VERSION ""

NS_ :

BS_:

BU_: PFAF_HS LVMPC_HS DCDC_HS AMP_HS VICM2_HS FICM_HS ARS_HS MCP_B_HS MCP_A_HS ICCM_OBD_HS SAS_HS ACCM_HS VLBS_HS EBCM_OBD_HS EDI_HS HPCC_HS VITM_OBD_HS PTAM_HS OBCM_HS VICM_HS HCP_HS FDCM_HS APPS_HS ICCM_HS EOCM_F_HS GPCM_HS FSCM_ITBC_HS SCM_HS ITBC_HS VCM_HS HMIM_HS FCP_HS VES_HS Dummy_HS MCP_C_HS RWS_HS ONSTAR_HS EPS_HS TestTool_HS MCP_HS BCP_HS ALC_HS AHL_AFL_HS SADS_HS EPB_HS FSCM_HS AFS_HS FCM_HS TCCM_HS RDCM_HS PTO_HS PCM_HS EBCM_HS ACC_HS BCM_HS TCM_HS ECM_HS

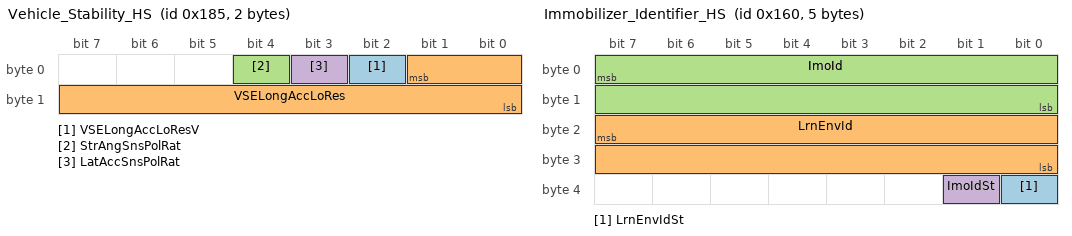
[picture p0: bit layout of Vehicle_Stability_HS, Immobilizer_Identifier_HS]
BO_ 389 Vehicle_Stability_HS: 2 EBCM_HS
 SG_ VSELongAccLoResV : 2|1@0+ (1,0) [0|1] ""  EDI_HS,FCM_HS,TCM_HS,ICCM_OBD_HS,ICCM_HS,ALC_HS,SADS_HS,VES_HS,EPS_HS,EPB_HS,RDCM_HS,BCM_HS,ACC_HS
 SG_ VSELongAccLoRes : 1|10@0- (0.03,0) [-15.36|15.33] "m/s^2"  EDI_HS,FCM_HS,TCM_HS,ICCM_OBD_HS,ICCM_HS,ALC_HS,SADS_HS,VES_HS,EPS_HS,EPB_HS,RDCM_HS,BCM_HS,ACC_HS
 SG_ StrAngSnsPolRat : 4|1@0+ (1,0) [0|1] ""  EPS_HS
 SG_ LatAccSnsPolRat : 3|1@0+ (1,0) [0|1] ""  EPS_HS

BO_ 1922 DTC_Triggered_782: 7 Dummy_HS
 SG_ DTCI_WrnIndRqdSt_782 : 47|1@0+ (1,0) [0|1] ""  HMIM_HS,FCP_HS,ONSTAR_HS
 SG_ DTCIUnused7_782 : 1|1@0+ (1,0) [0|1] ""  HMIM_HS,FCP_HS,ONSTAR_HS
 SG_ DTCIUnused6_782 : 2|1@0+ (1,0) [0|1] ""  HMIM_HS,FCP_HS,ONSTAR_HS
 SG_ DTCIUnused5_782 : 3|1@0+ (1,0) [0|1] ""  HMIM_HS,FCP_HS,ONSTAR_HS
 SG_ DTCIUnused4_782 : 4|1@0+ (1,0) [0|1] ""  HMIM_HS,FCP_HS,ONSTAR_HS
 SG_ DTCIUnused3_782 : 5|1@0+ (1,0) [0|1] ""  HMIM_HS,FCP_HS,ONSTAR_HS
 SG_ DTCIUnused2_782 : 6|1@0+ (1,0) [0|1] ""  HMIM_HS,FCP_HS,ONSTAR_HS
 SG_ DTCIUnused1_782 : 7|1@0+ (1,0) [0|1] ""  HMIM_HS,FCP_HS,ONSTAR_HS
 SG_ DTCI_TstNPsdPwrUpSt_782 : 45|1@0+ (1,0) [0|1] ""  HMIM_HS,FCP_HS,ONSTAR_HS
 SG_ DTCI_TstNPsdCdClrdSt_782 : 42|1@0+ (1,0) [0|1] ""  HMIM_HS,FCP_HS,ONSTAR_HS
 SG_ DTCI_TstFldPwrUpSt_782 : 46|1@0+ (1,0) [0|1] ""  HMIM_HS,FCP_HS,ONSTAR_HS
 SG_ DTCI_TstFldCdClrdStat_782 : 43|1@0+ (1,0) [0|1] ""  HMIM_HS,FCP_HS,ONSTAR_HS
 SG_ DTCI_HistStat_782 : 44|1@0+ (1,0) [0|1] ""  HMIM_HS,FCP_HS,ONSTAR_HS
 SG_ DTCI_DTCTriggered_782 : 0|1@0+ (1,0) [0|1] ""  HMIM_HS,FCP_HS,ONSTAR_HS
 SG_ DTCI_DTCSource_782 : 15|8@0+ (1,0) [0|255] ""  HMIM_HS,FCP_HS,ONSTAR_HS
 SG_ DTCI_DTCNumber_782 : 23|16@0+ (1,0) [0|65535] ""  HMIM_HS,FCP_HS,ONSTAR_HS
 SG_ DTCI_DTCFaultType_782 : 55|8@0+ (1,0) [0|255] ""  HMIM_HS,FCP_HS,ONSTAR_HS
 SG_ DTCI_DTCFailType_782 : 39|8@0+ (1,0) [0|255] ""  HMIM_HS,FCP_HS,ONSTAR_HS
 SG_ DTCI_CurrentStatus_782 : 41|1@0+ (1,0) [0|1] ""  HMIM_HS,FCP_HS,ONSTAR_HS
 SG_ DTCI_CodeSupported_782 : 40|1@0+ (1,0) [0|1] ""  HMIM_HS,FCP_HS,ONSTAR_HS

BO_ 352 Immobilizer_Identifier_HS: 5 BCM_HS
 SG_ LrnEnvIdSt : 32|1@0+ (1,0) [0|1] ""  VLBS_HS,ONSTAR_HS,EBCM_OBD_HS,EBCM_HS
 SG_ LrnEnvId : 23|16@0+ (1,0) [0|65535] ""  VLBS_HS,ONSTAR_HS,EBCM_OBD_HS,EBCM_HS
 SG_ ImoId : 7|16@0+ (1,0) [0|65535] ""  VLBS_HS,ONSTAR_HS,EBCM_OBD_HS,EBCM_HS
 SG_ ImoIdSt : 33|1@0+ (1,0) [0|1] ""  VLBS_HS,ONSTAR_HS,EBCM_OBD_HS,EBCM_HS

BO_ 562 Driving_Mode_Control_HS: 8 EBCM_HS
 SG_ SndPerfMdCsStAvl : 63|1@0+ (1,0) [0|1] ""  BCM_HS
 SG_ SndPerfMdCsCrStVal : 62|3@0+ (1,0) [0|7] ""  BCM_HS
 SG_ DispPerfMdCsStAvl : 59|1@0+ (1,0) [0|1] ""  BCM_HS
 SG_ DispPerfMdCsCrStVal : 58|3@0+ (1,0) [0|7] ""  BCM_HS
 SG_ DrvlneMntsPerfMdRq : 50|3@0+ (1,0) [0|7] ""  Dummy_HS,ICCM_OBD_HS,ICCM_HS
 SG_ RideCntrlPerfMdRq : 18|3@0+ (1,0) [0|7] ""  EDI_HS,SADS_HS
 SG_ StgSysPerfMdRq : 29|3@0+ (1,0) [0|7] ""  EDI_HS,VES_HS,EPS_HS,ARS_HS,AFS_HS
 SG_ DiffPerfMdRq : 26|3@0+ (1,0) [0|7] ""  ICCM_OBD_HS,ICCM_HS
 SG_ SndEnhcmtPerfMdRq : 13|3@0+ (1,0) [0|7] ""  BCM_HS,AMP_HS
 SG_ DsplyPerfMdRq : 10|3@0+ (1,0) [0|7] ""  EDI_HS,BCM_HS
 SG_ ExhstPerfMdRq : 5|3@0+ (1,0) [0|7] ""  FSCM_HS,ICCM_OBD_HS,ICCM_HS
 SG_ HillDscntCntlSysStat : 55|3@0+ (1,0) [0|7] ""  BCM_HS
 SG_ SusCustStngAvlbl : 23|1@0+ (1,0) [0|1] ""  FCP_HS,ONSTAR_HS,BCM_HS
 SG_ SusCustCurrStngVal : 45|3@0+ (1,0) [0|7] ""  FCP_HS,ONSTAR_HS,BCM_HS
 SG_ StrCustStngAvlbl : 7|1@0+ (1,0) [0|1] ""  FCP_HS,ONSTAR_HS,BCM_HS
 SG_ StrCustCurrStngVal : 42|3@0+ (1,0) [0|7] ""  FCP_HS,ONSTAR_HS,BCM_HS
 SG_ DrvlnCustStngAvlbl : 6|1@0+ (1,0) [0|1] ""  FCP_HS,ONSTAR_HS,BCM_HS
 SG_ DrvMdCntrlState : 39|8@0+ (1,0) [0|255] ""  ARS_HS,VES_HS,EPS_HS,AFS_HS,RDCM_HS,SADS_HS
 SG_ AWDPerfMdRq : 2|3@0+ (1,0) [0|7] ""  RDCM_HS,TCCM_HS
 SG_ DrvlnCustCurrStngVal : 22|3@0+ (1,0) [0|7] ""  FCP_HS,ONSTAR_HS,BCM_HS

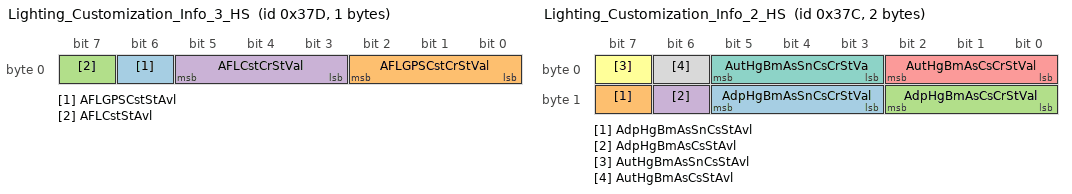
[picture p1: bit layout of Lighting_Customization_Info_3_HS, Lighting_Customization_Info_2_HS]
BO_ 893 Lighting_Customization_Info_3_HS: 1 AHL_AFL_HS
 SG_ AFLGPSCstStAvl : 6|1@0+ (1,0) [0|1] ""  BCM_HS
 SG_ AFLGPSCstCrStVal : 2|3@0+ (1,0) [0|7] ""  BCM_HS
 SG_ AFLCstStAvl : 7|1@0+ (1,0) [0|1] ""  BCM_HS
 SG_ AFLCstCrStVal : 5|3@0+ (1,0) [0|7] ""  BCM_HS

BO_ 892 Lighting_Customization_Info_2_HS: 2 AHL_AFL_HS
 SG_ AdpHgBmAsSnCsCrStVal : 13|3@0+ (1,0) [0|7] ""  BCM_HS
 SG_ AdpHgBmAsSnCsStAvl : 15|1@0+ (1,0) [0|1] ""  BCM_HS
 SG_ AdpHgBmAsCsCrStVal : 10|3@0+ (1,0) [0|7] ""  BCM_HS
 SG_ AdpHgBmAsCsStAvl : 14|1@0+ (1,0) [0|1] ""  BCM_HS
 SG_ AutHgBmAsCsCrStVal : 2|3@0+ (1,0) [0|7] ""  BCM_HS
 SG_ AutHgBmAsSnCsStAvl : 7|1@0+ (1,0) [0|1] ""  BCM_HS
 SG_ AutHgBmAsSnCsCrStVa : 5|3@0+ (1,0) [0|7] ""  BCM_HS
 SG_ AutHgBmAsCsStAvl : 6|1@0+ (1,0) [0|1] ""  BCM_HS

BO_ 386 Environment_Id_Resp_4_HS: 3 EBCM_HS
 SG_ EnvIdRsp4 : 7|16@0+ (1,0) [0|65535] ""  BCM_HS
 SG_ EnvIdRspSt4 : 17|2@0+ (1,0) [0|3] ""  BCM_HS

BO_ 597 USDT_Req_to_AFS_HS: 8 TestTool_HS
 SG_ DgnInf : 7|64@0+ (1,0) [0|1.844674407371E+019] ""  AFS_HS

BO_ 1621 USDT_Resp_From_AFS_HS: 8 AFS_HS
 SG_ DgnInf : 7|64@0+ (1,0) [0|1.844674407371E+019] ""  FCP_HS,ONSTAR_HS,TestTool_HS

BO_ 532 Brake_Pedal_Driver_Status_HS: 6 EBCM_HS
 SG_ RedntVSEActARC : 38|2@0+ (1,0) [0|3] ""  ICCM_OBD_HS,ICCM_HS
 SG_ RedntVSEAct : 39|1@0+ (1,0) [0|1] ""  ICCM_OBD_HS,ICCM_HS
 SG_ AutoBrkngActARC : 22|2@0+ (1,0) [0|3] ""  ICCM_OBD_HS,ICCM_HS
 SG_ ABSAutnmsBrkReqPVal : 41|2@0+ (1,0) [0|3] ""  EPB_HS
 SG_ AutoBrkngAvlbl : 17|1@0+ (1,0) [0|1] ""  EPB_HS
 SG_ ABSAutnmsBrkReqARC : 35|2@0+ (1,0) [0|3] ""  EPB_HS
 SG_ ABSAutnmsBrkReq : 33|1@0+ (1,0) [0|1] ""  EPB_HS
 SG_ ABSActvProtPVal : 43|2@0+ (1,0) [0|3] ""  ICCM_OBD_HS,ICCM_HS
 SG_ ABSActvProtARC : 45|2@0+ (1,0) [0|3] ""  ICCM_OBD_HS,ICCM_HS
 SG_ HlStrAssActIO : 20|1@0+ (1,0) [0|1] ""  BCM_HS
 SG_ ABSActvProt : 46|1@0+ (1,0) [0|1] ""  ICCM_OBD_HS,ICCM_HS
 SG_ BrkSysAutBrkFld : 5|1@0+ (1,0) [0|1] ""  EPB_HS,BCM_HS,ACC_HS
 SG_ IntBrkAssPreFilReq : 4|1@0+ (1,0) [0|1] "N/A"  BCM_HS
 SG_ BrkSysMalFuncIndOn : 3|1@0+ (1,0) [0|1] ""  BCM_HS
 SG_ BrkPdDrvAPrsStaPVal : 16|9@0+ (1,0) [0|511] ""  ACC_HS,EOCM_F_HS,FSCM_ITBC_HS,EPB_HS,SADS_HS
 SG_ BPDAPS_BkPDrvApPV : 8|1@0+ (1,0) [0|1] ""  EOCM_F_HS,FSCM_ITBC_HS,BCM_HS,ACC_HS,SADS_HS,EPB_HS
 SG_ BPDAPS_BkPDrvApP : 0|8@0+ (75,0) [0|19125] "kPa"  EOCM_F_HS,FSCM_ITBC_HS,BCM_HS,ACC_HS,SADS_HS,EPB_HS
 SG_ BrkPdDrvAppPrsAlRC : 2|2@0+ (1,0) [0|3] ""  ACC_HS,EOCM_F_HS,FSCM_ITBC_HS,SADS_HS,EPB_HS
 SG_ BrkFldLvlLwV : 7|1@0+ (1,0) [0|1] ""  BCM_HS
 SG_ AutoBrkngAct : 18|1@0+ (1,0) [0|1] ""  ICCM_OBD_HS,ICCM_HS,EPB_HS,ACC_HS
 SG_ BrkFldLvlLw : 6|1@0+ (1,0) [0|1] ""  BCM_HS

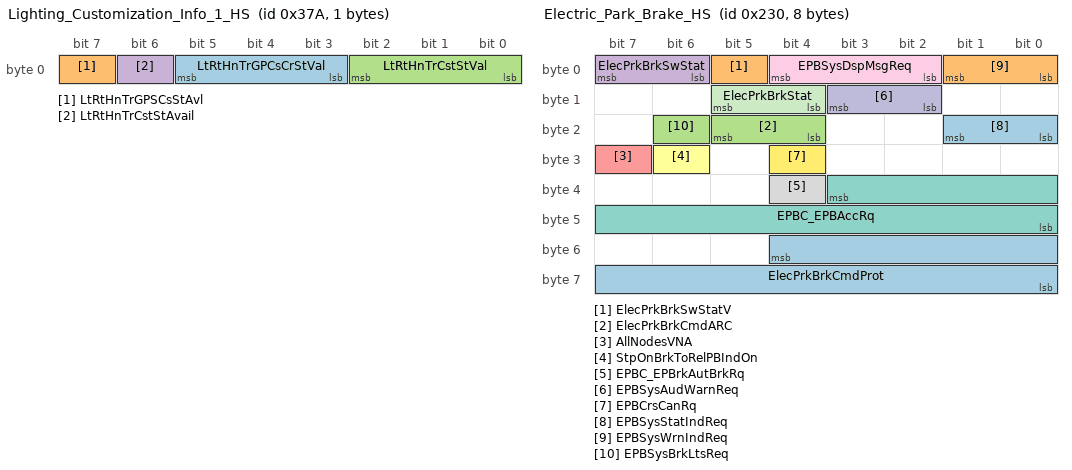
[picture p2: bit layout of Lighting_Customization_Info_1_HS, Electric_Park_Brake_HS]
BO_ 890 Lighting_Customization_Info_1_HS: 1 AHL_AFL_HS
 SG_ LtRtHnTrGPCsCrStVal : 5|3@0+ (1,0) [0|7] ""  BCM_HS
 SG_ LtRtHnTrGPSCsStAvl : 7|1@0+ (1,0) [0|1] ""  BCM_HS
 SG_ LtRtHnTrCstStVal : 2|3@0+ (1,0) [0|7] ""  BCM_HS
 SG_ LtRtHnTrCstStAvail : 6|1@0+ (1,0) [0|1] ""  BCM_HS

BO_ 592 USDT_Req_to_PTAM_HS: 8 TestTool_HS
 SG_ DgnInf : 7|64@0+ (1,0) [0|1.844674407371E+019] ""  PTAM_HS

BO_ 1365 UUDT_Resp_From_AFS_HS: 8 AFS_HS
 SG_ DgnInf_HS555 : 7|64@0+ (1,0) [0|1.844674407371E+019] ""  FCP_HS,ONSTAR_HS,TestTool_HS

BO_ 328 Power_Steering_Information_HS: 1 EPS_HS
 SG_ StrngAsstRdcdIO : 1|1@0+ (1,0) [0|1] ""  BCM_HS
 SG_ PwrStrIO : 0|1@0+ (1,0) [0|1] ""  BCM_HS,EPB_HS

BO_ 560 Electric_Park_Brake_HS: 8 EPB_HS
 SG_ ElecPrkBrkCmdProt : 52|13@0+ (1,0) [0|8191] ""  EBCM_OBD_HS,EBCM_HS
 SG_ ElecPrkBrkSwStatV : 5|1@0+ (1,0) [0|1] ""  EBCM_OBD_HS,EBCM_HS
 SG_ ElecPrkBrkCmdARC : 21|2@0+ (1,0) [0|3] ""  EBCM_OBD_HS,EBCM_HS
 SG_ ElecPrkBrkSwStat : 7|2@0+ (1,0) [0|3] ""  EBCM_OBD_HS,EBCM_HS
 SG_ AllNodesVNA : 31|1@0+ (1,0) [0|1] ""  BCM_HS
 SG_ StpOnBrkToRelPBIndOn : 30|1@0+ (1,0) [0|1] ""  BCM_HS
 SG_ EPBC_EPBAccRq : 35|12@0- (0.01,0) [-20.48|20.47] "m/s^2"  EBCM_OBD_HS,EBCM_HS
 SG_ EPBC_EPBrkAutBrkRq : 36|1@0+ (1,0) [0|1] ""  EBCM_OBD_HS,EBCM_HS
 SG_ EPBSysDspMsgReq : 4|3@0+ (1,0) [0|7] ""  BCM_HS
 SG_ EPBSysAudWarnReq : 11|2@0+ (1,0) [0|3] ""  BCM_HS
 SG_ ElecPrkBrkStat : 13|2@0+ (1,0) [0|2] ""  ICCM_OBD_HS,ICCM_HS,ACC_HS,EOCM_F_HS,BCM_HS,EBCM_OBD_HS,EBCM_HS,RDCM_HS
 SG_ EPBCrsCanRq : 28|1@0+ (1,0) [0|1] ""  ACC_HS,EOCM_F_HS,EBCM_OBD_HS,EBCM_HS,BCM_HS
 SG_ EPBSysStatIndReq : 17|2@0+ (1,0) [0|3] ""  BCM_HS
 SG_ EPBSysWrnIndReq : 1|2@0+ (1,0) [0|3] ""  BCM_HS
 SG_ EPBSysBrkLtsReq : 22|1@0+ (1,0) [0|1] ""  BCM_HS

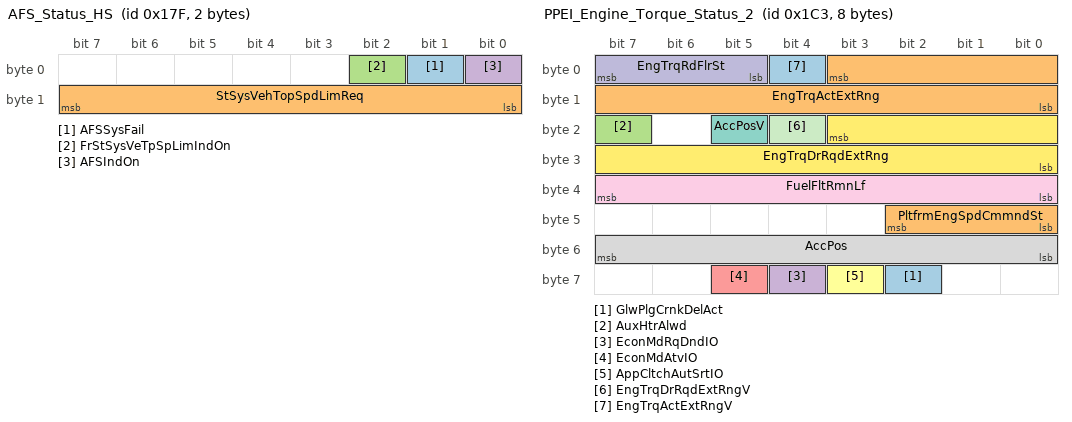
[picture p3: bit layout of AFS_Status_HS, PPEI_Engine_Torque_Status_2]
BO_ 383 AFS_Status_HS: 2 AFS_HS
 SG_ AFSSysFail : 1|1@0+ (1,0) [0|1] ""  EBCM_OBD_HS,EBCM_HS
 SG_ StSysVehTopSpdLimReq : 15|8@0+ (2,0) [0|510] "km/h"  BCM_HS
 SG_ FrStSysVeTpSpLimIndOn : 2|1@0+ (1,0) [0|1] ""  BCM_HS
 SG_ AFSIndOn : 0|1@0+ (1,0) [0|1] ""  BCM_HS

BO_ 451 PPEI_Engine_Torque_Status_2: 8 ECM_HS
 SG_ GlwPlgCrnkDelAct : 58|1@0+ (1,0) [0|1] ""  BCM_HS
 SG_ PltfrmEngSpdCmmndSt : 42|3@0+ (1,0) [0|7] ""  PTO_HS
 SG_ AuxHtrAlwd : 23|1@0+ (1,0) [0|1] ""  BCM_HS
 SG_ EconMdRqDndIO : 60|1@0+ (1,0) [0|1] ""  BCM_HS
 SG_ EconMdAtvIO : 61|1@0+ (1,0) [0|1] ""  BCM_HS
 SG_ AppCltchAutSrtIO : 59|1@0+ (1,0) [0|1] ""  BCM_HS
 SG_ AccPosV : 21|1@0+ (1,0) [0|1] ""  ICCM_OBD_HS,ICCM_HS,FSCM_ITBC_HS,FSCM_HS,ACC_HS,EOCM_F_HS,TCCM_HS,EBCM_OBD_HS,EBCM_HS
 SG_ AccPos : 55|8@0+ (0.392157,0) [0|100.000035] "%"  ICCM_OBD_HS,ICCM_HS,FSCM_ITBC_HS,FSCM_HS,EOCM_F_HS,VICM_HS,ACC_HS,TCCM_HS,EBCM_OBD_HS,EBCM_HS
 SG_ FuelFltRmnLf : 39|8@0+ (0.392157,0) [0|100.000035] "%"  FCP_HS,ONSTAR_HS,BCM_HS
 SG_ EngTrqRdFlrSt : 7|3@0+ (1,0) [0|7] ""  PTAM_HS,EBCM_OBD_HS,EBCM_HS
 SG_ EngTrqDrRqdExtRngV : 20|1@0+ (1,0) [0|1] ""  LVMPC_HS,BCM_HS,PTAM_HS,ACC_HS,RDCM_HS,EBCM_OBD_HS,EBCM_HS,SADS_HS
 SG_ EngTrqDrRqdExtRng : 19|12@0+ (0.5,-848) [-848|1199.5] "Nm"  LVMPC_HS,BCM_HS,PTAM_HS,ACC_HS,RDCM_HS,EBCM_OBD_HS,EBCM_HS,SADS_HS
 SG_ EngTrqActExtRngV : 4|1@0+ (1,0) [0|1] ""  PTO_HS,ICCM_OBD_HS,ICCM_HS,FSCM_ITBC_HS,FSCM_HS,AMP_HS,PTAM_HS,TCCM_HS,VES_HS,ACC_HS,EPS_HS,EPB_HS,BCM_HS,RDCM_HS,EBCM_OBD_HS,EBCM_HS,SADS_HS
 SG_ EngTrqActExtRng : 3|12@0+ (0.5,-848) [-848|1199.5] "Nm"  ICCM_OBD_HS,ICCM_HS,FSCM_ITBC_HS,FSCM_HS,PTO_HS,AMP_HS,PTAM_HS,TCCM_HS,VES_HS,ACC_HS,EPS_HS,EPB_HS,BCM_HS,RDCM_HS,EBCM_OBD_HS,EBCM_HS,SADS_HS

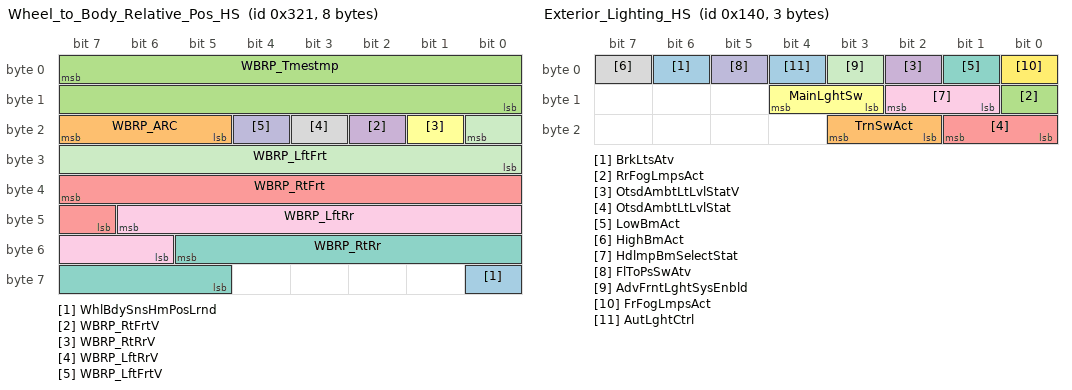
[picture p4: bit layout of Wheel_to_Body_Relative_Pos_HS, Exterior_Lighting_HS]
BO_ 801 Wheel_to_Body_Relative_Pos_HS: 8 SADS_HS
 SG_ WhlBdySnsHmPosLrnd : 56|1@0+ (1,0) [0|1] ""  EDI_HS,ICCM_OBD_HS,ICCM_HS,ALC_HS,SADS_HS,FCM_HS,AHL_AFL_HS,EBCM_OBD_HS,EBCM_HS
 SG_ WBRP_ARC : 23|3@0+ (1,0) [0|7] "counts"  EDI_HS,ICCM_OBD_HS,ICCM_HS,ALC_HS,SADS_HS,FCM_HS,EBCM_OBD_HS,EBCM_HS,AHL_AFL_HS
 SG_ WBRP_Tmestmp : 7|16@0+ (1,0) [0|65535] "micro sec"  EDI_HS,ICCM_OBD_HS,ICCM_HS,ALC_HS,SADS_HS,FCM_HS,EBCM_OBD_HS,EBCM_HS,AHL_AFL_HS
 SG_ WBRP_RtFrtV : 18|1@0+ (1,0) [0|1] ""  EDI_HS,ICCM_OBD_HS,ICCM_HS,ALC_HS,SADS_HS,FCM_HS,EBCM_OBD_HS,EBCM_HS,AHL_AFL_HS
 SG_ WBRP_RtFrt : 39|9@0- (1,0) [-256|255] "mm"  EDI_HS,ICCM_OBD_HS,ICCM_HS,ALC_HS,SADS_HS,FCM_HS,EBCM_OBD_HS,EBCM_HS,AHL_AFL_HS
 SG_ WBRP_RtRrV : 17|1@0+ (1,0) [0|1] ""  EDI_HS,ICCM_OBD_HS,ICCM_HS,ALC_HS,SADS_HS,FCM_HS,EBCM_OBD_HS,EBCM_HS,AHL_AFL_HS
 SG_ WBRP_RtRr : 53|9@0- (1,0) [-256|255] "mm"  EDI_HS,ICCM_OBD_HS,ICCM_HS,ALC_HS,SADS_HS,FCM_HS,EBCM_OBD_HS,EBCM_HS,AHL_AFL_HS
 SG_ WBRP_LftRrV : 19|1@0+ (1,0) [0|1] ""  EDI_HS,ICCM_OBD_HS,ICCM_HS,ALC_HS,SADS_HS,FCM_HS,EBCM_OBD_HS,EBCM_HS,AHL_AFL_HS
 SG_ WBRP_LftRr : 46|9@0- (1,0) [-256|255] "mm"  EDI_HS,ICCM_OBD_HS,ICCM_HS,ALC_HS,SADS_HS,FCM_HS,EBCM_OBD_HS,EBCM_HS,AHL_AFL_HS
 SG_ WBRP_LftFrtV : 20|1@0+ (1,0) [0|1] ""  EDI_HS,ICCM_OBD_HS,ICCM_HS,ALC_HS,SADS_HS,FCM_HS,EBCM_OBD_HS,EBCM_HS,AHL_AFL_HS
 SG_ WBRP_LftFrt : 16|9@0- (1,0) [-256|255] "mm"  EDI_HS,ICCM_OBD_HS,ICCM_HS,ALC_HS,SADS_HS,FCM_HS,EBCM_OBD_HS,EBCM_HS,AHL_AFL_HS

BO_ 320 Exterior_Lighting_HS: 3 BCM_HS
 SG_ BrkLtsAtv : 6|1@0+ (1,0) [0|1] ""  AHL_AFL_HS,EOCM_F_HS,ACC_HS
 SG_ TrnSwAct : 19|2@0+ (1,0) [0|3] ""  EOCM_F_HS,AHL_AFL_HS
 SG_ RrFogLmpsAct : 8|1@0+ (1,0) [0|1] ""  AHL_AFL_HS
 SG_ OtsdAmbtLtLvlStatV : 2|1@0+ (1,0) [0|1] ""  FCM_HS,EOCM_F_HS,AHL_AFL_HS
 SG_ OtsdAmbtLtLvlStat : 17|2@0+ (1,0) [0|3] ""  FCM_HS,EOCM_F_HS,AHL_AFL_HS
 SG_ MainLghtSw : 12|2@0+ (1,0) [0|3] "N/A"  FCM_HS,AHL_AFL_HS
 SG_ LowBmAct : 1|1@0+ (1,0) [0|1] ""  FCM_HS,EOCM_F_HS,AHL_AFL_HS
 SG_ HighBmAct : 7|1@0+ (1,0) [0|1] ""  FCM_HS,EOCM_F_HS,AHL_AFL_HS
 SG_ HdlmpBmSelectStat : 10|2@0+ (1,0) [0|3] ""  FCM_HS,AHL_AFL_HS
 SG_ FlToPsSwAtv : 5|1@0+ (1,0) [0|1] ""  FCM_HS,AHL_AFL_HS
 SG_ AdvFrntLghtSysEnbld : 3|1@0+ (1,0) [0|1] ""  AHL_AFL_HS
 SG_ FrFogLmpsAct : 0|1@0+ (1,0) [0|1] ""  FCM_HS,AHL_AFL_HS
 SG_ AutLghtCtrl : 4|1@0+ (1,0) [0|1] "N/A"  AHL_AFL_HS

BO_ 957 ETEI_Glow_Plug_Diagnostic_Status: 8 GPCM_HS
 SG_ RdctHtrCStat : 26|1@0+ (1,0) [0|1] ""  PCM_HS,ECM_HS
 SG_ RdctHtrBStat : 27|1@0+ (1,0) [0|1] ""  PCM_HS,ECM_HS
 SG_ RdctHtrAStat : 28|1@0+ (1,0) [0|1] ""  PCM_HS,ECM_HS
 SG_ GPCMDS2_DTCStatus : 58|3@0+ (1,0) [0|7] ""  PCM_HS,ECM_HS
 SG_ GPCMDS2_DTCIndex : 63|5@0+ (1,0) [0|31] ""  PCM_HS,ECM_HS
 SG_ IntAirHtrPwrConsmp : 55|8@0+ (20,0) [0|5100] "W"  PCM_HS,ECM_HS
 SG_ IntAirHtrPwrConsmpV : 29|1@0+ (1,0) [0|1] ""  PCM_HS,ECM_HS
 SG_ DslGlwPlgMdOvTmOD : 25|1@0+ (1,0) [0|1] ""  PCM_HS,ECM_HS
 SG_ IQAI_DataByte : 47|8@0+ (1,0) [0|255] ""  PCM_HS,ECM_HS
 SG_ IQAI_DataSeqNmbr : 35|4@0+ (1,0) [0|15] ""  PCM_HS,ECM_HS
 SG_ IQAI_InjIdInd : 38|3@0+ (1,0) [0|7] ""  PCM_HS,ECM_HS
 SG_ IQAI_DataStat : 39|1@0+ (1,0) [0|1] ""  PCM_HS,ECM_HS
 SG_ IntAirHtrTempSensVoltV : 30|1@0+ (1,0) [0|1] ""  PCM_HS,ECM_HS
 SG_ IntAirHtrTempSensVolt : 23|8@0+ (0.0196078,0) [0|4.999989] "volts"  PCM_HS,ECM_HS
 SG_ IntAirHtrSupVoltV : 31|1@0+ (1,0) [0|1] ""  PCM_HS,ECM_HS
 SG_ IntAirHtrSupVolt : 15|8@0+ (0.1,0) [0|25.5] "volts"  PCM_HS,ECM_HS
 SG_ GPCMDS_DTCStatus : 2|3@0+ (1,0) [0|7] ""  PCM_HS,ECM_HS
 SG_ GPCMDS_DTCIndex : 7|5@0+ (1,0) [0|31] ""  PCM_HS,ECM_HS

BO_ 1364 UUDT_Resp_From_EPB_HS: 8 EPB_HS
 SG_ DgnInf_HS554 : 7|64@0+ (1,0) [0|1.844674407371E+019] ""  FCP_HS,ONSTAR_HS,TestTool_HS

BO_ 2041 PCU_Resp_From_SDM_HS: 8 BCM_HS
 SG_ PCUInfo_7F9 : 7|64@0+ (1,0) [0|1.844674407371E+019] ""  TestTool_HS

BO_ 1904 DTC_Triggered_770: 7 FSCM_HS
 SG_ DTCI_WrnIndRqdSt_770 : 47|1@0+ (1,0) [0|1] ""  HMIM_HS,FCP_HS,ONSTAR_HS
 SG_ DTCIUnused7_770 : 7|1@0+ (1,0) [0|1] ""  HMIM_HS,FCP_HS,ONSTAR_HS
 SG_ DTCIUnused6_770 : 6|1@0+ (1,0) [0|1] ""  HMIM_HS,FCP_HS,ONSTAR_HS
 SG_ DTCIUnused5_770 : 5|1@0+ (1,0) [0|1] ""  HMIM_HS,FCP_HS,ONSTAR_HS
 SG_ DTCIUnused4_770 : 4|1@0+ (1,0) [0|1] ""  HMIM_HS,FCP_HS,ONSTAR_HS
 SG_ DTCIUnused3_770 : 3|1@0+ (1,0) [0|1] ""  HMIM_HS,FCP_HS,ONSTAR_HS
 SG_ DTCIUnused2_770 : 2|1@0+ (1,0) [0|1] ""  HMIM_HS,FCP_HS,ONSTAR_HS
 SG_ DTCIUnused1_770 : 1|1@0+ (1,0) [0|1] ""  HMIM_HS,FCP_HS,ONSTAR_HS
 SG_ DTCI_TstNPsdPwrUpSt_770 : 45|1@0+ (1,0) [0|1] ""  HMIM_HS,FCP_HS,ONSTAR_HS
 SG_ DTCI_TstNPsdCdClrdSt_770 : 42|1@0+ (1,0) [0|1] ""  HMIM_HS,FCP_HS,ONSTAR_HS
 SG_ DTCI_TstFldPwrUpSt_770 : 46|1@0+ (1,0) [0|1] ""  HMIM_HS,FCP_HS,ONSTAR_HS
 SG_ DTCI_TstFldCdClrdStat_770 : 43|1@0+ (1,0) [0|1] ""  HMIM_HS,FCP_HS,ONSTAR_HS
 SG_ DTCI_HistStat_770 : 44|1@0+ (1,0) [0|1] ""  HMIM_HS,FCP_HS,ONSTAR_HS
 SG_ DTCI_DTCTriggered_770 : 0|1@0+ (1,0) [0|1] ""  HMIM_HS,FCP_HS,ONSTAR_HS
 SG_ DTCI_DTCSource_770 : 15|8@0+ (1,0) [0|255] ""  HMIM_HS,FCP_HS,ONSTAR_HS
 SG_ DTCI_DTCNumber_770 : 23|16@0+ (1,0) [0|65535] ""  HMIM_HS,FCP_HS,ONSTAR_HS
 SG_ DTCI_DTCFaultType_770 : 55|8@0+ (1,0) [0|255] ""  HMIM_HS,FCP_HS,ONSTAR_HS
 SG_ DTCI_DTCFailType_770 : 39|8@0+ (1,0) [0|255] ""  HMIM_HS,FCP_HS,ONSTAR_HS
 SG_ DTCI_CurrentStatus_770 : 41|1@0+ (1,0) [0|1] ""  HMIM_HS,FCP_HS,ONSTAR_HS
 SG_ DTCI_CodeSupported_770 : 40|1@0+ (1,0) [0|1] ""  HMIM_HS,FCP_HS,ONSTAR_HS

BO_ 1908 DTC_Triggered_774: 7 DCDC_HS
 SG_ DTCI_DTCFaultType_774 : 55|8@0+ (1,0) [0|255] ""  HMIM_HS,FCP_HS,ONSTAR_HS
 SG_ DTCI_CodeSupported_774 : 40|1@0+ (1,0) [0|1] ""  HMIM_HS,FCP_HS,ONSTAR_HS
 SG_ DTCI_CurrentStatus_774 : 41|1@0+ (1,0) [0|1] ""  HMIM_HS,FCP_HS,ONSTAR_HS
 SG_ DTCI_TstNPsdCdClrdSt_774 : 42|1@0+ (1,0) [0|1] ""  HMIM_HS,FCP_HS,ONSTAR_HS
 SG_ DTCI_TstFldCdClrdStat_774 : 43|1@0+ (1,0) [0|1] ""  HMIM_HS,FCP_HS,ONSTAR_HS
 SG_ DTCI_HistStat_774 : 44|1@0+ (1,0) [0|1] ""  HMIM_HS,FCP_HS,ONSTAR_HS
 SG_ DTCI_TstNPsdPwrUpSt_774 : 45|1@0+ (1,0) [0|1] ""  HMIM_HS,FCP_HS,ONSTAR_HS
 SG_ DTCI_TstFldPwrUpSt_774 : 46|1@0+ (1,0) [0|1] ""  HMIM_HS,FCP_HS,ONSTAR_HS
 SG_ DTCI_WrnIndRqdSt_774 : 47|1@0+ (1,0) [0|1] ""  HMIM_HS,FCP_HS,ONSTAR_HS
 SG_ DTCI_DTCFailType_774 : 39|8@0+ (1,0) [0|255] ""  HMIM_HS,FCP_HS,ONSTAR_HS
 SG_ DTCI_DTCNumber_774 : 23|16@0+ (1,0) [0|65535] ""  HMIM_HS,FCP_HS,ONSTAR_HS
 SG_ DTCI_DTCSource_774 : 15|8@0+ (1,0) [0|255] ""  HMIM_HS,FCP_HS,ONSTAR_HS
 SG_ DTCI_DTCTriggered_774 : 0|1@0+ (1,0) [0|1] ""  HMIM_HS,FCP_HS,ONSTAR_HS
 SG_ DTCIUnused7_774 : 1|1@0+ (1,0) [0|1] ""  HMIM_HS,FCP_HS,ONSTAR_HS
 SG_ DTCIUnused6_774 : 2|1@0+ (1,0) [0|1] ""  HMIM_HS,FCP_HS,ONSTAR_HS
 SG_ DTCIUnused5_774 : 3|1@0+ (1,0) [0|1] ""  HMIM_HS,FCP_HS,ONSTAR_HS
 SG_ DTCIUnused4_774 : 4|1@0+ (1,0) [0|1] ""  HMIM_HS,FCP_HS,ONSTAR_HS
 SG_ DTCIUnused3_774 : 5|1@0+ (1,0) [0|1] ""  HMIM_HS,FCP_HS,ONSTAR_HS
 SG_ DTCIUnused2_774 : 6|1@0+ (1,0) [0|1] ""  HMIM_HS,FCP_HS,ONSTAR_HS
 SG_ DTCIUnused1_774 : 7|1@0+ (1,0) [0|1] ""  HMIM_HS,FCP_HS,ONSTAR_HS

BO_ 1909 DTC_Triggered_775: 7 MCP_HS
 SG_ DTCI_DTCFaultType_775 : 55|8@0+ (1,0) [0|255] ""  HMIM_HS,FCP_HS,ONSTAR_HS
 SG_ DTCI_CodeSupported_775 : 40|1@0+ (1,0) [0|1] ""  HMIM_HS,FCP_HS,ONSTAR_HS
 SG_ DTCI_CurrentStatus_775 : 41|1@0+ (1,0) [0|1] ""  HMIM_HS,FCP_HS,ONSTAR_HS
 SG_ DTCI_TstNPsdCdClrdSt_775 : 42|1@0+ (1,0) [0|1] ""  HMIM_HS,FCP_HS,ONSTAR_HS
 SG_ DTCI_TstFldCdClrdStat_775 : 43|1@0+ (1,0) [0|1] ""  HMIM_HS,FCP_HS,ONSTAR_HS
 SG_ DTCI_HistStat_775 : 44|1@0+ (1,0) [0|1] ""  HMIM_HS,FCP_HS,ONSTAR_HS
 SG_ DTCI_TstNPsdPwrUpSt_775 : 45|1@0+ (1,0) [0|1] ""  HMIM_HS,FCP_HS,ONSTAR_HS
 SG_ DTCI_TstFldPwrUpSt_775 : 46|1@0+ (1,0) [0|1] ""  HMIM_HS,FCP_HS,ONSTAR_HS
 SG_ DTCI_WrnIndRqdSt_775 : 47|1@0+ (1,0) [0|1] ""  HMIM_HS,FCP_HS,ONSTAR_HS
 SG_ DTCI_DTCFailType_775 : 39|8@0+ (1,0) [0|255] ""  HMIM_HS,FCP_HS,ONSTAR_HS
 SG_ DTCI_DTCNumber_775 : 23|16@0+ (1,0) [0|65535] ""  HMIM_HS,FCP_HS,ONSTAR_HS
 SG_ DTCI_DTCSource_775 : 15|8@0+ (1,0) [0|255] ""  HMIM_HS,FCP_HS,ONSTAR_HS
 SG_ DTCI_DTCTriggered_775 : 0|1@0+ (1,0) [0|1] ""  HMIM_HS,FCP_HS,ONSTAR_HS
 SG_ DTCIUnused7_775 : 1|1@0+ (1,0) [0|1] ""  HMIM_HS,FCP_HS,ONSTAR_HS
 SG_ DTCIUnused6_775 : 2|1@0+ (1,0) [0|1] ""  HMIM_HS,FCP_HS,ONSTAR_HS
 SG_ DTCIUnused5_775 : 3|1@0+ (1,0) [0|1] ""  HMIM_HS,FCP_HS,ONSTAR_HS
 SG_ DTCIUnused4_775 : 4|1@0+ (1,0) [0|1] ""  HMIM_HS,FCP_HS,ONSTAR_HS
 SG_ DTCIUnused3_775 : 5|1@0+ (1,0) [0|1] ""  HMIM_HS,FCP_HS,ONSTAR_HS
 SG_ DTCIUnused2_775 : 6|1@0+ (1,0) [0|1] ""  HMIM_HS,FCP_HS,ONSTAR_HS
 SG_ DTCIUnused1_775 : 7|1@0+ (1,0) [0|1] ""  HMIM_HS,FCP_HS,ONSTAR_HS

BO_ 1910 DTC_Triggered_776: 7 BCP_HS
 SG_ DTCI_DTCFaultType_776 : 55|8@0+ (1,0) [0|255] ""  HMIM_HS,FCP_HS,ONSTAR_HS
 SG_ DTCI_CodeSupported_776 : 40|1@0+ (1,0) [0|1] ""  HMIM_HS,FCP_HS,ONSTAR_HS
 SG_ DTCI_CurrentStatus_776 : 41|1@0+ (1,0) [0|1] ""  HMIM_HS,FCP_HS,ONSTAR_HS
 SG_ DTCI_TstNPsdCdClrdSt_776 : 42|1@0+ (1,0) [0|1] ""  HMIM_HS,FCP_HS,ONSTAR_HS
 SG_ DTCI_TstFldCdClrdStat_776 : 43|1@0+ (1,0) [0|1] ""  HMIM_HS,FCP_HS,ONSTAR_HS
 SG_ DTCI_HistStat_776 : 44|1@0+ (1,0) [0|1] ""  HMIM_HS,FCP_HS,ONSTAR_HS
 SG_ DTCI_TstNPsdPwrUpSt_776 : 45|1@0+ (1,0) [0|1] ""  HMIM_HS,FCP_HS,ONSTAR_HS
 SG_ DTCI_TstFldPwrUpSt_776 : 46|1@0+ (1,0) [0|1] ""  HMIM_HS,FCP_HS,ONSTAR_HS
 SG_ DTCI_WrnIndRqdSt_776 : 47|1@0+ (1,0) [0|1] ""  HMIM_HS,FCP_HS,ONSTAR_HS
 SG_ DTCI_DTCFailType_776 : 39|8@0+ (1,0) [0|255] ""  HMIM_HS,FCP_HS,ONSTAR_HS
 SG_ DTCI_DTCNumber_776 : 23|16@0+ (1,0) [0|65535] ""  HMIM_HS,FCP_HS,ONSTAR_HS
 SG_ DTCI_DTCSource_776 : 15|8@0+ (1,0) [0|255] ""  HMIM_HS,FCP_HS,ONSTAR_HS
 SG_ DTCI_DTCTriggered_776 : 0|1@0+ (1,0) [0|1] ""  HMIM_HS,FCP_HS,ONSTAR_HS
 SG_ DTCIUnused7_776 : 1|1@0+ (1,0) [0|1] ""  HMIM_HS,FCP_HS,ONSTAR_HS
 SG_ DTCIUnused6_776 : 2|1@0+ (1,0) [0|1] ""  HMIM_HS,FCP_HS,ONSTAR_HS
 SG_ DTCIUnused5_776 : 3|1@0+ (1,0) [0|1] ""  HMIM_HS,FCP_HS,ONSTAR_HS
 SG_ DTCIUnused4_776 : 4|1@0+ (1,0) [0|1] ""  HMIM_HS,FCP_HS,ONSTAR_HS
 SG_ DTCIUnused3_776 : 5|1@0+ (1,0) [0|1] ""  HMIM_HS,FCP_HS,ONSTAR_HS
 SG_ DTCIUnused2_776 : 6|1@0+ (1,0) [0|1] ""  HMIM_HS,FCP_HS,ONSTAR_HS
 SG_ DTCIUnused1_776 : 7|1@0+ (1,0) [0|1] ""  HMIM_HS,FCP_HS,ONSTAR_HS

BO_ 1912 DTC_Triggered_778: 7 EPS_HS
 SG_ DTCI_DTCFaultType_778 : 55|8@0+ (1,0) [0|255] ""  HMIM_HS,FCP_HS,ONSTAR_HS
 SG_ DTCI_CodeSupported_778 : 40|1@0+ (1,0) [0|1] ""  HMIM_HS,FCP_HS,ONSTAR_HS
 SG_ DTCI_CurrentStatus_778 : 41|1@0+ (1,0) [0|1] ""  HMIM_HS,FCP_HS,ONSTAR_HS
 SG_ DTCI_TstNPsdCdClrdSt_778 : 42|1@0+ (1,0) [0|1] ""  HMIM_HS,FCP_HS,ONSTAR_HS
 SG_ DTCI_TstFldCdClrdStat_778 : 43|1@0+ (1,0) [0|1] ""  HMIM_HS,FCP_HS,ONSTAR_HS
 SG_ DTCI_HistStat_778 : 44|1@0+ (1,0) [0|1] ""  HMIM_HS,FCP_HS,ONSTAR_HS
 SG_ DTCI_TstNPsdPwrUpSt_778 : 45|1@0+ (1,0) [0|1] ""  HMIM_HS,FCP_HS,ONSTAR_HS
 SG_ DTCI_TstFldPwrUpSt_778 : 46|1@0+ (1,0) [0|1] ""  HMIM_HS,FCP_HS,ONSTAR_HS
 SG_ DTCI_WrnIndRqdSt_778 : 47|1@0+ (1,0) [0|1] ""  HMIM_HS,FCP_HS,ONSTAR_HS
 SG_ DTCI_DTCFailType_778 : 39|8@0+ (1,0) [0|255] ""  HMIM_HS,FCP_HS,ONSTAR_HS
 SG_ DTCI_DTCNumber_778 : 23|16@0+ (1,0) [0|65535] ""  HMIM_HS,FCP_HS,ONSTAR_HS
 SG_ DTCI_DTCSource_778 : 15|8@0+ (1,0) [0|255] ""  HMIM_HS,FCP_HS,ONSTAR_HS
 SG_ DTCI_DTCTriggered_778 : 0|1@0+ (1,0) [0|1] ""  HMIM_HS,FCP_HS,ONSTAR_HS
 SG_ DTCIUnused7_778 : 1|1@0+ (1,0) [0|1] ""  HMIM_HS,FCP_HS,ONSTAR_HS
 SG_ DTCIUnused6_778 : 2|1@0+ (1,0) [0|1] ""  HMIM_HS,FCP_HS,ONSTAR_HS
 SG_ DTCIUnused5_778 : 3|1@0+ (1,0) [0|1] ""  HMIM_HS,FCP_HS,ONSTAR_HS
 SG_ DTCIUnused4_778 : 4|1@0+ (1,0) [0|1] ""  HMIM_HS,FCP_HS,ONSTAR_HS
 SG_ DTCIUnused3_778 : 5|1@0+ (1,0) [0|1] ""  HMIM_HS,FCP_HS,ONSTAR_HS
 SG_ DTCIUnused2_778 : 6|1@0+ (1,0) [0|1] ""  HMIM_HS,FCP_HS,ONSTAR_HS
 SG_ DTCIUnused1_778 : 7|1@0+ (1,0) [0|1] ""  HMIM_HS,FCP_HS,ONSTAR_HS

BO_ 1913 DTC_Triggered_779: 7 AFS_HS
 SG_ DTCI_DTCFaultType_779 : 55|8@0+ (1,0) [0|255] ""  HMIM_HS,FCP_HS,ONSTAR_HS
 SG_ DTCI_CodeSupported_779 : 40|1@0+ (1,0) [0|1] ""  HMIM_HS,FCP_HS,ONSTAR_HS
 SG_ DTCI_CurrentStatus_779 : 41|1@0+ (1,0) [0|1] ""  HMIM_HS,FCP_HS,ONSTAR_HS
 SG_ DTCI_TstNPsdCdClrdSt_779 : 42|1@0+ (1,0) [0|1] ""  HMIM_HS,FCP_HS,ONSTAR_HS
 SG_ DTCI_TstFldCdClrdStat_779 : 43|1@0+ (1,0) [0|1] ""  HMIM_HS,FCP_HS,ONSTAR_HS
 SG_ DTCI_HistStat_779 : 44|1@0+ (1,0) [0|1] ""  HMIM_HS,FCP_HS,ONSTAR_HS
 SG_ DTCI_TstNPsdPwrUpSt_779 : 45|1@0+ (1,0) [0|1] ""  HMIM_HS,FCP_HS,ONSTAR_HS
 SG_ DTCI_TstFldPwrUpSt_779 : 46|1@0+ (1,0) [0|1] ""  HMIM_HS,FCP_HS,ONSTAR_HS
 SG_ DTCI_WrnIndRqdSt_779 : 47|1@0+ (1,0) [0|1] ""  HMIM_HS,FCP_HS,ONSTAR_HS
 SG_ DTCI_DTCFailType_779 : 39|8@0+ (1,0) [0|255] ""  HMIM_HS,FCP_HS,ONSTAR_HS
 SG_ DTCI_DTCNumber_779 : 23|16@0+ (1,0) [0|65535] ""  HMIM_HS,FCP_HS,ONSTAR_HS
 SG_ DTCI_DTCSource_779 : 15|8@0+ (1,0) [0|255] ""  HMIM_HS,FCP_HS,ONSTAR_HS
 SG_ DTCI_DTCTriggered_779 : 0|1@0+ (1,0) [0|1] ""  HMIM_HS,FCP_HS,ONSTAR_HS
 SG_ DTCIUnused7_779 : 1|1@0+ (1,0) [0|1] ""  HMIM_HS,FCP_HS,ONSTAR_HS
 SG_ DTCIUnused6_779 : 2|1@0+ (1,0) [0|1] ""  HMIM_HS,FCP_HS,ONSTAR_HS
 SG_ DTCIUnused5_779 : 3|1@0+ (1,0) [0|1] ""  HMIM_HS,FCP_HS,ONSTAR_HS
 SG_ DTCIUnused4_779 : 4|1@0+ (1,0) [0|1] ""  HMIM_HS,FCP_HS,ONSTAR_HS
 SG_ DTCIUnused3_779 : 5|1@0+ (1,0) [0|1] ""  HMIM_HS,FCP_HS,ONSTAR_HS
 SG_ DTCIUnused2_779 : 6|1@0+ (1,0) [0|1] ""  HMIM_HS,FCP_HS,ONSTAR_HS
 SG_ DTCIUnused1_779 : 7|1@0+ (1,0) [0|1] ""  HMIM_HS,FCP_HS,ONSTAR_HS

BO_ 1916 DTC_Triggered_77C: 7 AHL_AFL_HS
 SG_ DTCI_DTCFaultType_77C : 55|8@0+ (1,0) [0|255] ""  HMIM_HS,FCP_HS,ONSTAR_HS
 SG_ DTCI_CodeSupported_77C : 40|1@0+ (1,0) [0|1] ""  HMIM_HS,FCP_HS,ONSTAR_HS
 SG_ DTCI_CurrentStatus_77C : 41|1@0+ (1,0) [0|1] ""  HMIM_HS,FCP_HS,ONSTAR_HS
 SG_ DTCI_TstNPsdCdClrdSt_77C : 42|1@0+ (1,0) [0|1] ""  HMIM_HS,FCP_HS,ONSTAR_HS
 SG_ DTCI_TstFldCdClrdStat_77C : 43|1@0+ (1,0) [0|1] ""  HMIM_HS,FCP_HS,ONSTAR_HS
 SG_ DTCI_HistStat_77C : 44|1@0+ (1,0) [0|1] ""  HMIM_HS,FCP_HS,ONSTAR_HS
 SG_ DTCI_TstNPsdPwrUpSt_77C : 45|1@0+ (1,0) [0|1] ""  HMIM_HS,FCP_HS,ONSTAR_HS
 SG_ DTCI_TstFldPwrUpSt_77C : 46|1@0+ (1,0) [0|1] ""  HMIM_HS,FCP_HS,ONSTAR_HS
 SG_ DTCI_WrnIndRqdSt_77C : 47|1@0+ (1,0) [0|1] ""  HMIM_HS,FCP_HS,ONSTAR_HS
 SG_ DTCI_DTCFailType_77C : 39|8@0+ (1,0) [0|255] ""  HMIM_HS,FCP_HS,ONSTAR_HS
 SG_ DTCI_DTCNumber_77C : 23|16@0+ (1,0) [0|65535] ""  HMIM_HS,FCP_HS,ONSTAR_HS
 SG_ DTCI_DTCSource_77C : 15|8@0+ (1,0) [0|255] ""  HMIM_HS,FCP_HS,ONSTAR_HS
 SG_ DTCI_DTCTriggered_77C : 0|1@0+ (1,0) [0|1] ""  HMIM_HS,FCP_HS,ONSTAR_HS
 SG_ DTCIUnused7_77C : 1|1@0+ (1,0) [0|1] ""  HMIM_HS,FCP_HS,ONSTAR_HS
 SG_ DTCIUnused6_77C : 2|1@0+ (1,0) [0|1] ""  HMIM_HS,FCP_HS,ONSTAR_HS
 SG_ DTCIUnused5_77C : 3|1@0+ (1,0) [0|1] ""  HMIM_HS,FCP_HS,ONSTAR_HS
 SG_ DTCIUnused4_77C : 4|1@0+ (1,0) [0|1] ""  HMIM_HS,FCP_HS,ONSTAR_HS
 SG_ DTCIUnused3_77C : 5|1@0+ (1,0) [0|1] ""  HMIM_HS,FCP_HS,ONSTAR_HS
 SG_ DTCIUnused2_77C : 6|1@0+ (1,0) [0|1] ""  HMIM_HS,FCP_HS,ONSTAR_HS
 SG_ DTCIUnused1_77C : 7|1@0+ (1,0) [0|1] ""  HMIM_HS,FCP_HS,ONSTAR_HS

BO_ 1917 DTC_Triggered_77D: 7 EPB_HS
 SG_ DTCI_DTCFaultType_77D : 55|8@0+ (1,0) [0|255] ""  HMIM_HS,FCP_HS,ONSTAR_HS
 SG_ DTCI_CodeSupported_77D : 40|1@0+ (1,0) [0|1] ""  HMIM_HS,FCP_HS,ONSTAR_HS
 SG_ DTCI_CurrentStatus_77D : 41|1@0+ (1,0) [0|1] ""  HMIM_HS,FCP_HS,ONSTAR_HS
 SG_ DTCI_TstNPsdCdClrdSt_77D : 42|1@0+ (1,0) [0|1] ""  HMIM_HS,FCP_HS,ONSTAR_HS
 SG_ DTCI_TstFldCdClrdStat_77D : 43|1@0+ (1,0) [0|1] ""  HMIM_HS,FCP_HS,ONSTAR_HS
 SG_ DTCI_HistStat_77D : 44|1@0+ (1,0) [0|1] ""  HMIM_HS,FCP_HS,ONSTAR_HS
 SG_ DTCI_TstNPsdPwrUpSt_77D : 45|1@0+ (1,0) [0|1] ""  HMIM_HS,FCP_HS,ONSTAR_HS
 SG_ DTCI_TstFldPwrUpSt_77D : 46|1@0+ (1,0) [0|1] ""  HMIM_HS,FCP_HS,ONSTAR_HS
 SG_ DTCI_WrnIndRqdSt_77D : 47|1@0+ (1,0) [0|1] ""  HMIM_HS,FCP_HS,ONSTAR_HS
 SG_ DTCI_DTCFailType_77D : 39|8@0+ (1,0) [0|255] ""  HMIM_HS,FCP_HS,ONSTAR_HS
 SG_ DTCI_DTCNumber_77D : 23|16@0+ (1,0) [0|65535] ""  HMIM_HS,FCP_HS,ONSTAR_HS
 SG_ DTCI_DTCSource_77D : 15|8@0+ (1,0) [0|255] ""  HMIM_HS,FCP_HS,ONSTAR_HS
 SG_ DTCI_DTCTriggered_77D : 0|1@0+ (1,0) [0|1] ""  HMIM_HS,FCP_HS,ONSTAR_HS
 SG_ DTCIUnused7_77D : 1|1@0+ (1,0) [0|1] ""  HMIM_HS,FCP_HS,ONSTAR_HS
 SG_ DTCIUnused6_77D : 2|1@0+ (1,0) [0|1] ""  HMIM_HS,FCP_HS,ONSTAR_HS
 SG_ DTCIUnused5_77D : 3|1@0+ (1,0) [0|1] ""  HMIM_HS,FCP_HS,ONSTAR_HS
 SG_ DTCIUnused4_77D : 4|1@0+ (1,0) [0|1] ""  HMIM_HS,FCP_HS,ONSTAR_HS
 SG_ DTCIUnused3_77D : 5|1@0+ (1,0) [0|1] ""  HMIM_HS,FCP_HS,ONSTAR_HS
 SG_ DTCIUnused2_77D : 6|1@0+ (1,0) [0|1] ""  HMIM_HS,FCP_HS,ONSTAR_HS
 SG_ DTCIUnused1_77D : 7|1@0+ (1,0) [0|1] ""  HMIM_HS,FCP_HS,ONSTAR_HS

BO_ 1918 DTC_Triggered_77E: 7 SADS_HS
 SG_ DTCI_DTCFaultType_77E : 55|8@0+ (1,0) [0|255] ""  HMIM_HS,FCP_HS,ONSTAR_HS
 SG_ DTCI_CodeSupported_77E : 40|1@0+ (1,0) [0|1] ""  HMIM_HS,FCP_HS,ONSTAR_HS
 SG_ DTCI_CurrentStatus_77E : 41|1@0+ (1,0) [0|1] ""  HMIM_HS,FCP_HS,ONSTAR_HS
 SG_ DTCI_TstNPsdCdClrdSt_77E : 42|1@0+ (1,0) [0|1] ""  HMIM_HS,FCP_HS,ONSTAR_HS
 SG_ DTCI_TstFldCdClrdStat_77E : 43|1@0+ (1,0) [0|1] ""  HMIM_HS,FCP_HS,ONSTAR_HS
 SG_ DTCI_HistStat_77E : 44|1@0+ (1,0) [0|1] ""  HMIM_HS,FCP_HS,ONSTAR_HS
 SG_ DTCI_TstNPsdPwrUpSt_77E : 45|1@0+ (1,0) [0|1] ""  HMIM_HS,FCP_HS,ONSTAR_HS
 SG_ DTCI_TstFldPwrUpSt_77E : 46|1@0+ (1,0) [0|1] ""  HMIM_HS,FCP_HS,ONSTAR_HS
 SG_ DTCI_WrnIndRqdSt_77E : 47|1@0+ (1,0) [0|1] ""  HMIM_HS,FCP_HS,ONSTAR_HS
 SG_ DTCI_DTCFailType_77E : 39|8@0+ (1,0) [0|255] ""  HMIM_HS,FCP_HS,ONSTAR_HS
 SG_ DTCI_DTCNumber_77E : 23|16@0+ (1,0) [0|65535] ""  HMIM_HS,FCP_HS,ONSTAR_HS
 SG_ DTCI_DTCSource_77E : 15|8@0+ (1,0) [0|255] ""  HMIM_HS,FCP_HS,ONSTAR_HS
 SG_ DTCI_DTCTriggered_77E : 0|1@0+ (1,0) [0|1] ""  HMIM_HS,FCP_HS,ONSTAR_HS
 SG_ DTCIUnused7_77E : 1|1@0+ (1,0) [0|1] ""  HMIM_HS,FCP_HS,ONSTAR_HS
 SG_ DTCIUnused6_77E : 2|1@0+ (1,0) [0|1] ""  HMIM_HS,FCP_HS,ONSTAR_HS
 SG_ DTCIUnused5_77E : 3|1@0+ (1,0) [0|1] ""  HMIM_HS,FCP_HS,ONSTAR_HS
 SG_ DTCIUnused4_77E : 4|1@0+ (1,0) [0|1] ""  HMIM_HS,FCP_HS,ONSTAR_HS
 SG_ DTCIUnused3_77E : 5|1@0+ (1,0) [0|1] ""  HMIM_HS,FCP_HS,ONSTAR_HS
 SG_ DTCIUnused2_77E : 6|1@0+ (1,0) [0|1] ""  HMIM_HS,FCP_HS,ONSTAR_HS
 SG_ DTCIUnused1_77E : 7|1@0+ (1,0) [0|1] ""  HMIM_HS,FCP_HS,ONSTAR_HS

BO_ 1919 DTC_Triggered_77F: 7 TCM_HS
 SG_ DTCI_DTCFaultType_77F : 55|8@0+ (1,0) [0|255] ""  HMIM_HS,FCP_HS,ONSTAR_HS
 SG_ DTCI_CodeSupported_77F : 40|1@0+ (1,0) [0|1] ""  HMIM_HS,FCP_HS,ONSTAR_HS
 SG_ DTCI_CurrentStatus_77F : 41|1@0+ (1,0) [0|1] ""  HMIM_HS,FCP_HS,ONSTAR_HS
 SG_ DTCI_TstNPsdCdClrdSt_77F : 42|1@0+ (1,0) [0|1] ""  HMIM_HS,FCP_HS,ONSTAR_HS
 SG_ DTCI_TstFldCdClrdStat_77F : 43|1@0+ (1,0) [0|1] ""  HMIM_HS,FCP_HS,ONSTAR_HS
 SG_ DTCI_HistStat_77F : 44|1@0+ (1,0) [0|1] ""  HMIM_HS,FCP_HS,ONSTAR_HS
 SG_ DTCI_TstNPsdPwrUpSt_77F : 45|1@0+ (1,0) [0|1] ""  HMIM_HS,FCP_HS,ONSTAR_HS
 SG_ DTCI_TstFldPwrUpSt_77F : 46|1@0+ (1,0) [0|1] ""  HMIM_HS,FCP_HS,ONSTAR_HS
 SG_ DTCI_WrnIndRqdSt_77F : 47|1@0+ (1,0) [0|1] ""  HMIM_HS,FCP_HS,ONSTAR_HS
 SG_ DTCI_DTCFailType_77F : 39|8@0+ (1,0) [0|255] ""  HMIM_HS,FCP_HS,ONSTAR_HS
 SG_ DTCI_DTCNumber_77F : 23|16@0+ (1,0) [0|65535] ""  HMIM_HS,FCP_HS,ONSTAR_HS
 SG_ DTCI_DTCSource_77F : 15|8@0+ (1,0) [0|255] ""  HMIM_HS,FCP_HS,ONSTAR_HS
 SG_ DTCI_DTCTriggered_77F : 0|1@0+ (1,0) [0|1] ""  HMIM_HS,FCP_HS,ONSTAR_HS
 SG_ DTCIUnused7_77F : 1|1@0+ (1,0) [0|1] ""  HMIM_HS,FCP_HS,ONSTAR_HS
 SG_ DTCIUnused6_77F : 2|1@0+ (1,0) [0|1] ""  HMIM_HS,FCP_HS,ONSTAR_HS
 SG_ DTCIUnused5_77F : 3|1@0+ (1,0) [0|1] ""  HMIM_HS,FCP_HS,ONSTAR_HS
 SG_ DTCIUnused4_77F : 4|1@0+ (1,0) [0|1] ""  HMIM_HS,FCP_HS,ONSTAR_HS
 SG_ DTCIUnused3_77F : 5|1@0+ (1,0) [0|1] ""  HMIM_HS,FCP_HS,ONSTAR_HS
 SG_ DTCIUnused2_77F : 6|1@0+ (1,0) [0|1] ""  HMIM_HS,FCP_HS,ONSTAR_HS
 SG_ DTCIUnused1_77F : 7|1@0+ (1,0) [0|1] ""  HMIM_HS,FCP_HS,ONSTAR_HS

BO_ 589 USDT_Req_to_ONS_HS: 8 TestTool_HS
 SG_ DgnInf : 7|64@0+ (1,0) [0|1.844674407371E+019] ""  FCP_HS,ONSTAR_HS

BO_ 1357 UUDT_Resp_From_ONS_HS: 8 ONSTAR_HS
 SG_ DgnInf_HS54D : 7|64@0+ (1,0) [0|1.844674407371E+019] ""  TestTool_HS

BO_ 1613 USDT_Resp_From_ONS_HS: 8 ONSTAR_HS
 SG_ DgnInf : 7|64@0+ (1,0) [0|1.844674407371E+019] ""  TestTool_HS

BO_ 1606 USDT_Resp_From_APPS_HS: 8 APPS_HS
 SG_ DgnInf : 7|64@0+ (1,0) [0|1.844674407371E+019] ""  FCP_HS,ONSTAR_HS,TestTool_HS

BO_ 582 USDT_Req_to_APPS_HS: 8 TestTool_HS
 SG_ DgnInf : 7|64@0+ (1,0) [0|1.844674407371E+019] ""  APPS_HS

BO_ 590 USDT_Req_to_SADS_HS: 8 TestTool_HS
 SG_ DgnInf : 7|64@0+ (1,0) [0|1.844674407371E+019] ""  SADS_HS

BO_ 601 USDT_Req_to_MCP_C_HS: 8 TestTool_HS
 SG_ DgnInf : 7|64@0+ (1,0) [0|1.844674407371E+019] ""  MCP_C_HS

BO_ 1369 UUDT_Resp_From_MCP_C_HS: 8 MCP_C_HS
 SG_ DgnInf_HS559 : 7|64@0+ (1,0) [0|1.844674407371E+019] ""  FCP_HS,ONSTAR_HS,TestTool_HS

BO_ 1625 USDT_Resp_From_MCP_C_HS: 8 MCP_C_HS
 SG_ DgnInf : 7|64@0+ (1,0) [0|1.844674407371E+019] ""  FCP_HS,ONSTAR_HS,TestTool_HS

BO_ 1356 UUDT_Resp_From_PFAF_HS: 8 PFAF_HS
 SG_ DgnInf_HS54C : 7|64@0+ (1,0) [0|1.844674407371E+019] ""  FCP_HS,ONSTAR_HS,TestTool_HS

BO_ 1358 UUDT_Resp_From_SADS_HS: 8 SADS_HS
 SG_ DgnInf_HS54E : 7|64@0+ (1,0) [0|1.844674407371E+019] ""  FCP_HS,ONSTAR_HS,TestTool_HS

BO_TX_BU_ 389 : EBCM_OBD_HS,EBCM_HS;
BO_TX_BU_ 562 : EBCM_OBD_HS,EBCM_HS;
BO_TX_BU_ 386 : EBCM_OBD_HS,EBCM_HS;
BO_TX_BU_ 597 : FCP_HS,ONSTAR_HS,TestTool_HS;
BO_TX_BU_ 532 : EBCM_OBD_HS,EBCM_HS;
BO_TX_BU_ 592 : FCP_HS,ONSTAR_HS,TestTool_HS;
BO_TX_BU_ 328 : EBCM_OBD_HS,EBCM_HS,VES_HS,EPS_HS;
BO_TX_BU_ 801 : ICCM_OBD_HS,ICCM_HS,ALC_HS,SADS_HS;
BO_TX_BU_ 1904 : FSCM_ITBC_HS,FSCM_HS;
BO_TX_BU_ 1909 : MCP_A_HS,MCP_HS;
BO_TX_BU_ 1912 : VES_HS,EPS_HS;
BO_TX_BU_ 1357 : FCP_HS,ONSTAR_HS;
BO_TX_BU_ 1613 : FCP_HS,ONSTAR_HS;
BO_TX_BU_ 582 : FCP_HS,ONSTAR_HS,TestTool_HS;
BO_TX_BU_ 590 : FCP_HS,ONSTAR_HS,TestTool_HS;
BO_TX_BU_ 601 : FCP_HS,ONSTAR_HS,TestTool_HS;
CM_ SG_ 1922 DTCI_DTCSource_782 "This shall be equal to the Diagnostic Address of the transmittting device.";
CM_ SG_ 1922 DTCI_DTCFaultType_782 "Based on Powertrain definition.  Not expected to be supported by all devices.";
CM_ SG_ 1922 DTCI_DTCFailType_782 "Assigned per GMW3110, Appendix E";
CM_ SG_ 532 BrkSysAutBrkFld "BrakeSystemAutomaticBrakingFailed";
CM_ SG_ 532 IntBrkAssPreFilReq "IntelligentBrakeAssistPreFillRequest";
CM_ SG_ 801 WBRP_RtFrt "Negative values indicate Compression, Positive values indicate Extension.";
CM_ SG_ 801 WBRP_RtRr "Negative values indicate Compression, Positive values indicate Extension.";
CM_ SG_ 801 WBRP_LftRr "Negative values indicate Compression, Positive values indicate Extension.";
CM_ SG_ 801 WBRP_LftFrt "Negative values indicate Compression, Positive values indicate Extension.";
CM_ SG_ 320 MainLghtSw "Operator selection for the main lighting switch";
CM_ SG_ 320 AutLghtCtrl "This signal represents if Automatic Lights Control feature is active/inactive";
CM_ SG_ 1904 DTCI_DTCSource_770 "This shall be equal to the Diagnostic Address of the transmittting device.";
CM_ SG_ 1904 DTCI_DTCFaultType_770 "Based on Powertrain definition.  Not expected to be supported by all devices.";
CM_ SG_ 1904 DTCI_DTCFailType_770 "Assigned per GMW3110, Appendix E";
CM_ SG_ 1908 DTCI_DTCFaultType_774 "Based on Powertrain definition.  Not expected to be supported by all devices.";
CM_ SG_ 1908 DTCI_DTCFailType_774 "Assigned per GMW3110, Appendix E";
CM_ SG_ 1908 DTCI_DTCSource_774 "This shall be equal to the Diagnostic Address of the transmittting device.";
CM_ SG_ 1909 DTCI_DTCFaultType_775 "Based on Powertrain definition.  Not expected to be supported by all devices.";
CM_ SG_ 1909 DTCI_DTCFailType_775 "Assigned per GMW3110, Appendix E";
CM_ SG_ 1909 DTCI_DTCSource_775 "This shall be equal to the Diagnostic Address of the transmittting device.";
CM_ SG_ 1910 DTCI_DTCFaultType_776 "Based on Powertrain definition.  Not expected to be supported by all devices.";
CM_ SG_ 1910 DTCI_DTCFailType_776 "Assigned per GMW3110, Appendix E";
CM_ SG_ 1910 DTCI_DTCSource_776 "This shall be equal to the Diagnostic Address of the transmittting device.";
CM_ SG_ 1912 DTCI_DTCFaultType_778 "Based on Powertrain definition.  Not expected to be supported by all devices.";
CM_ SG_ 1912 DTCI_DTCFailType_778 "Assigned per GMW3110, Appendix E";
CM_ SG_ 1912 DTCI_DTCSource_778 "This shall be equal to the Diagnostic Address of the transmittting device.";
CM_ SG_ 1913 DTCI_DTCFaultType_779 "Based on Powertrain definition.  Not expected to be supported by all devices.";
CM_ SG_ 1913 DTCI_DTCFailType_779 "Assigned per GMW3110, Appendix E";
CM_ SG_ 1913 DTCI_DTCSource_779 "This shall be equal to the Diagnostic Address of the transmittting device.";
CM_ SG_ 1916 DTCI_DTCFaultType_77C "Based on Powertrain definition.  Not expected to be supported by all devices.";
CM_ SG_ 1916 DTCI_DTCFailType_77C "Assigned per GMW3110, Appendix E";
CM_ SG_ 1916 DTCI_DTCSource_77C "This shall be equal to the Diagnostic Address of the transmittting device.";
CM_ SG_ 1917 DTCI_DTCFaultType_77D "Based on Powertrain definition.  Not expected to be supported by all devices.";
CM_ SG_ 1917 DTCI_DTCFailType_77D "Assigned per GMW3110, Appendix E";
CM_ SG_ 1917 DTCI_DTCSource_77D "This shall be equal to the Diagnostic Address of the transmittting device.";
CM_ SG_ 1918 DTCI_DTCFaultType_77E "Based on Powertrain definition.  Not expected to be supported by all devices.";
CM_ SG_ 1918 DTCI_DTCFailType_77E "Assigned per GMW3110, Appendix E";
CM_ SG_ 1918 DTCI_DTCSource_77E "This shall be equal to the Diagnostic Address of the transmittting device.";
CM_ SG_ 1919 DTCI_DTCFaultType_77F "Based on Powertrain definition.  Not expected to be supported by all devices.";
CM_ SG_ 1919 DTCI_DTCFailType_77F "Assigned per GMW3110, Appendix E";
CM_ SG_ 1919 DTCI_DTCSource_77F "This shall be equal to the Diagnostic Address of the transmittting device.";
BA_DEF_ SG_  "VNSigSLHS_VNReq" ENUM  "No","Yes";
BA_DEF_ SG_  "VNSigSLHSSharedDiagnostic" ENUM  "No","Yes";
BA_DEF_ SG_  "SignalType" STRING ;
BA_DEF_ SG_  "PacketOrder" INT 0 65535;
BA_DEF_ SG_  "SignalLongName" STRING ;
BA_DEF_ SG_  "GenSigStartValue" INT 0 65535;
BA_DEF_ SG_  "VNSigAllNodes" ENUM  "No","Yes";
BA_DEF_ SG_  "GenSigDeltaValue" INT 0 0;
BA_DEF_ SG_  "GenSigSendType" ENUM  "not used","not used","not used","not used","not used","not used","not used","NoSigSendType","not used","not used","OnAnyChange","OnChangeIfActive","OnDelta";
BA_DEF_ SG_  "GenSigSendOnInit" ENUM  "Not Initialized","Application","Handler";
BA_DEF_ BO_  "AppGenMsgCycleTime" INT 0 0;
BA_DEF_ BO_  "GenMsgILSupport" ENUM  "No","Yes";
BA_DEF_ BO_  "TpApplType" STRING ;
BA_DEF_ BO_  "Prio" INT 0 7;
BA_DEF_ BO_  "MessageSubnet" ENUM  "LS","MS","HS","CE","PE","HV","FO";
BA_DEF_ BO_  "DiagState" ENUM  "No","Yes";
BA_DEF_ BO_  "GenMsgDelayTime" INT 0 100000;
BA_DEF_ BO_  "GenMsgCycleTime" INT 0 100000;
BA_DEF_ BO_  "GenMsgSendType" ENUM  "cyclicX","spontanX","cyclicIfActiveX","spontanWithDelay","cyclicAndSpontanX","cyclicAndSpontanWithDelay","spontanWithRepitition","cyclicIfActiveAndSpontanWD";
BA_DEF_ BO_  "DiagResponse" ENUM  "No","Yes";
BA_DEF_ BO_  "DiagRequest" ENUM  "No","Yes";
BA_DEF_ BO_  "NmMessage" ENUM  "No","Yes";
BA_DEF_REL_ BU_SG_REL_  "GenSigSuprvRespComment" STRING ;
BA_DEF_REL_ BU_SG_REL_  "GenSigVBitResp" ENUM  "No","Yes";
BA_DEF_REL_ BU_SG_REL_  "GenSigVBitRespComment" STRING ;
BA_DEF_REL_ BU_SG_REL_  "GenSigVDAFailComment" STRING ;
BA_DEF_REL_ BU_SG_REL_  "GenSigVDAFailResp" ENUM  "No","Yes";
BA_DEF_REL_ BU_SG_REL_  "GenSigRxStartValue" STRING ;
BA_DEF_REL_ BU_SG_REL_  "GenSigSuprvRespSubValue" INT 0 65535;
BA_DEF_REL_ BU_SG_REL_  "GenSigSuprvResp" ENUM  "None","Notify App","Substitute Default";
BA_DEF_REL_ BU_SG_REL_  "GenSigTimeoutMsg" HEX -2147483648 268435455;
BA_DEF_REL_ BU_SG_REL_  "GenSigTimeoutTime" INT 0 15000;
BA_DEF_DEF_  "VNSigSLHS_VNReq" "No";
BA_DEF_DEF_  "VNSigSLHSSharedDiagnostic" "No";
BA_DEF_DEF_  "SignalType" "";
BA_DEF_DEF_  "PacketOrder" 0;
BA_DEF_DEF_  "SignalLongName" "";
BA_DEF_DEF_  "GenSigStartValue" 0;
BA_DEF_DEF_  "VNSigAllNodes" "No";
BA_DEF_DEF_  "GenSigDeltaValue" 0;
BA_DEF_DEF_  "GenSigSendType" "NoSigSendType";
BA_DEF_DEF_  "GenSigSendOnInit" "Not Initialized";
BA_DEF_DEF_  "AppGenMsgCycleTime" 0;
BA_DEF_DEF_  "GenMsgILSupport" "Yes";
BA_DEF_DEF_  "TpApplType" "";
BA_DEF_DEF_  "Prio" 4;
BA_DEF_DEF_  "MessageSubnet" "FO";
BA_DEF_DEF_  "DiagState" "No";
BA_DEF_DEF_  "GenMsgDelayTime" 0;
BA_DEF_DEF_  "GenMsgCycleTime" 0;
BA_DEF_DEF_  "GenMsgSendType" "spontanX";
BA_DEF_DEF_  "DiagResponse" "No";
BA_DEF_DEF_  "DiagRequest" "No";
BA_DEF_DEF_  "NmMessage" "No";
BA_DEF_DEF_REL_ "GenSigSuprvRespComment" "";
BA_DEF_DEF_REL_ "GenSigVBitResp" "No";
BA_DEF_DEF_REL_ "GenSigVBitRespComment" "";
BA_DEF_DEF_REL_ "GenSigVDAFailComment" "";
BA_DEF_DEF_REL_ "GenSigVDAFailResp" "No";
BA_DEF_DEF_REL_ "GenSigRxStartValue" "";
BA_DEF_DEF_REL_ "GenSigSuprvRespSubValue" 0;
BA_DEF_DEF_REL_ "GenSigSuprvResp" "None";
BA_DEF_DEF_REL_ "GenSigTimeoutMsg" 0;
BA_DEF_DEF_REL_ "GenSigTimeoutTime" 0;
BA_ "Prio" BO_ 389 0;
BA_ "MessageSubnet" BO_ 389 2;
BA_ "GenMsgCycleTime" BO_ 389 20;
BA_ "GenMsgSendType" BO_ 389 0;
BA_ "Prio" BO_ 1922 0;
BA_ "MessageSubnet" BO_ 1922 2;
BA_ "GenMsgCycleTime" BO_ 1922 1000;
BA_ "GenMsgSendType" BO_ 1922 0;
BA_ "Prio" BO_ 352 0;
BA_ "MessageSubnet" BO_ 352 2;
BA_ "GenMsgCycleTime" BO_ 352 100;
BA_ "GenMsgSendType" BO_ 352 0;
BA_ "Prio" BO_ 562 0;
BA_ "MessageSubnet" BO_ 562 2;
BA_ "GenMsgCycleTime" BO_ 562 20;
BA_ "GenMsgSendType" BO_ 562 0;
BA_ "Prio" BO_ 893 0;
BA_ "MessageSubnet" BO_ 893 2;
BA_ "GenMsgCycleTime" BO_ 893 100;
BA_ "GenMsgSendType" BO_ 893 0;
BA_ "Prio" BO_ 892 0;
BA_ "MessageSubnet" BO_ 892 2;
BA_ "GenMsgCycleTime" BO_ 892 100;
BA_ "GenMsgSendType" BO_ 892 0;
BA_ "Prio" BO_ 386 0;
BA_ "MessageSubnet" BO_ 386 2;
BA_ "GenMsgCycleTime" BO_ 386 100;
BA_ "GenMsgSendType" BO_ 386 0;
BA_ "Prio" BO_ 597 0;
BA_ "MessageSubnet" BO_ 597 2;
BA_ "DiagRequest" BO_ 597 1;
BA_ "Prio" BO_ 1621 0;
BA_ "MessageSubnet" BO_ 1621 2;
BA_ "DiagResponse" BO_ 1621 1;
BA_ "Prio" BO_ 532 0;
BA_ "MessageSubnet" BO_ 532 2;
BA_ "GenMsgCycleTime" BO_ 532 50;
BA_ "GenMsgSendType" BO_ 532 0;
BA_ "Prio" BO_ 890 0;
BA_ "MessageSubnet" BO_ 890 2;
BA_ "GenMsgCycleTime" BO_ 890 100;
BA_ "GenMsgSendType" BO_ 890 0;
BA_ "Prio" BO_ 592 0;
BA_ "MessageSubnet" BO_ 592 2;
BA_ "DiagRequest" BO_ 592 1;
BA_ "GenMsgILSupport" BO_ 1365 0;
BA_ "TpApplType" BO_ 1365 "DiagUUDTResponse";
BA_ "Prio" BO_ 1365 0;
BA_ "MessageSubnet" BO_ 1365 2;
BA_ "Prio" BO_ 328 0;
BA_ "MessageSubnet" BO_ 328 2;
BA_ "GenMsgDelayTime" BO_ 328 100;
BA_ "GenMsgCycleTime" BO_ 328 1000;
BA_ "GenMsgSendType" BO_ 328 0;
BA_ "Prio" BO_ 560 0;
BA_ "MessageSubnet" BO_ 560 2;
BA_ "GenMsgCycleTime" BO_ 560 50;
BA_ "GenMsgSendType" BO_ 560 0;
BA_ "Prio" BO_ 383 0;
BA_ "MessageSubnet" BO_ 383 2;
BA_ "GenMsgCycleTime" BO_ 383 100;
BA_ "GenMsgSendType" BO_ 383 0;
BA_ "Prio" BO_ 451 0;
BA_ "MessageSubnet" BO_ 451 2;
BA_ "GenMsgCycleTime" BO_ 451 25;
BA_ "GenMsgSendType" BO_ 451 0;
BA_ "Prio" BO_ 801 0;
BA_ "MessageSubnet" BO_ 801 2;
BA_ "GenMsgCycleTime" BO_ 801 25;
BA_ "GenMsgSendType" BO_ 801 0;
BA_ "Prio" BO_ 320 0;
BA_ "MessageSubnet" BO_ 320 2;
BA_ "GenMsgDelayTime" BO_ 320 10;
BA_ "GenMsgCycleTime" BO_ 320 1000;
BA_ "GenMsgSendType" BO_ 320 0;
BA_ "Prio" BO_ 957 0;
BA_ "MessageSubnet" BO_ 957 2;
BA_ "GenMsgCycleTime" BO_ 957 100;
BA_ "GenMsgSendType" BO_ 957 0;
BA_ "GenMsgILSupport" BO_ 1364 0;
BA_ "TpApplType" BO_ 1364 "DiagUUDTResponse";
BA_ "Prio" BO_ 1364 0;
BA_ "MessageSubnet" BO_ 1364 2;
BA_ "Prio" BO_ 2041 0;
BA_ "MessageSubnet" BO_ 2041 2;
BA_ "Prio" BO_ 1904 6;
BA_ "MessageSubnet" BO_ 1904 2;
BA_ "GenMsgCycleTime" BO_ 1904 1000;
BA_ "GenMsgSendType" BO_ 1904 0;
BA_ "Prio" BO_ 1908 6;
BA_ "MessageSubnet" BO_ 1908 2;
BA_ "GenMsgCycleTime" BO_ 1908 1000;
BA_ "GenMsgSendType" BO_ 1908 0;
BA_ "Prio" BO_ 1909 6;
BA_ "MessageSubnet" BO_ 1909 2;
BA_ "GenMsgCycleTime" BO_ 1909 1000;
BA_ "GenMsgSendType" BO_ 1909 0;
BA_ "Prio" BO_ 1910 6;
BA_ "MessageSubnet" BO_ 1910 2;
BA_ "GenMsgCycleTime" BO_ 1910 1000;
BA_ "GenMsgSendType" BO_ 1910 0;
BA_ "Prio" BO_ 1912 6;
BA_ "MessageSubnet" BO_ 1912 2;
BA_ "GenMsgCycleTime" BO_ 1912 1000;
BA_ "GenMsgSendType" BO_ 1912 0;
BA_ "Prio" BO_ 1913 6;
BA_ "MessageSubnet" BO_ 1913 2;
BA_ "GenMsgCycleTime" BO_ 1913 1000;
BA_ "GenMsgSendType" BO_ 1913 0;
BA_ "Prio" BO_ 1916 6;
BA_ "MessageSubnet" BO_ 1916 2;
BA_ "GenMsgCycleTime" BO_ 1916 1000;
BA_ "GenMsgSendType" BO_ 1916 0;
BA_ "Prio" BO_ 1917 6;
BA_ "MessageSubnet" BO_ 1917 2;
BA_ "GenMsgCycleTime" BO_ 1917 1000;
BA_ "GenMsgSendType" BO_ 1917 0;
BA_ "Prio" BO_ 1918 6;
BA_ "MessageSubnet" BO_ 1918 2;
BA_ "GenMsgCycleTime" BO_ 1918 1000;
BA_ "GenMsgSendType" BO_ 1918 0;
BA_ "Prio" BO_ 1919 6;
BA_ "MessageSubnet" BO_ 1919 2;
BA_ "GenMsgCycleTime" BO_ 1919 1000;
BA_ "GenMsgSendType" BO_ 1919 0;
BA_ "Prio" BO_ 589 0;
BA_ "MessageSubnet" BO_ 589 2;
BA_ "DiagRequest" BO_ 589 1;
BA_ "GenMsgILSupport" BO_ 1357 0;
BA_ "TpApplType" BO_ 1357 "DiagUUDTResponse";
BA_ "Prio" BO_ 1357 0;
BA_ "MessageSubnet" BO_ 1357 2;
BA_ "Prio" BO_ 1613 0;
BA_ "MessageSubnet" BO_ 1613 2;
BA_ "DiagResponse" BO_ 1613 1;
BA_ "Prio" BO_ 1606 0;
BA_ "MessageSubnet" BO_ 1606 2;
BA_ "DiagResponse" BO_ 1606 1;
BA_ "Prio" BO_ 582 0;
BA_ "MessageSubnet" BO_ 582 2;
BA_ "DiagRequest" BO_ 582 1;
BA_ "Prio" BO_ 590 0;
BA_ "MessageSubnet" BO_ 590 2;
BA_ "DiagRequest" BO_ 590 1;
BA_ "Prio" BO_ 601 0;
BA_ "MessageSubnet" BO_ 601 2;
BA_ "DiagRequest" BO_ 601 1;
BA_ "GenMsgILSupport" BO_ 1369 0;
BA_ "TpApplType" BO_ 1369 "DiagUUDTResponse";
BA_ "Prio" BO_ 1369 0;
BA_ "MessageSubnet" BO_ 1369 2;
BA_ "Prio" BO_ 1625 0;
BA_ "MessageSubnet" BO_ 1625 2;
BA_ "DiagResponse" BO_ 1625 1;
BA_ "GenMsgILSupport" BO_ 1356 0;
BA_ "TpApplType" BO_ 1356 "DiagUUDTResponse";
BA_ "Prio" BO_ 1356 0;
BA_ "MessageSubnet" BO_ 1356 2;
BA_ "GenMsgILSupport" BO_ 1358 0;
BA_ "TpApplType" BO_ 1358 "DiagUUDTResponse";
BA_ "Prio" BO_ 1358 0;
BA_ "MessageSubnet" BO_ 1358 2;
BA_ "SignalType" SG_ 389 VSELongAccLoResV "ENM";
BA_ "SignalLongName" SG_ 389 VSELongAccLoResV "Vehicle Stability Enhancement Longitudinal Acceleration Low Resolution Validity";
BA_ "VNSigAllNodes" SG_ 389 VSELongAccLoResV 1;
BA_ "SignalType" SG_ 389 VSELongAccLoRes "SNM";
BA_ "SignalLongName" SG_ 389 VSELongAccLoRes "Vehicle Stability Enhancement Longitudinal Acceleration Low Resolution";
BA_ "VNSigAllNodes" SG_ 389 VSELongAccLoRes 1;
BA_ "SignalType" SG_ 389 StrAngSnsPolRat "ENM";
BA_ "SignalLongName" SG_ 389 StrAngSnsPolRat "Steering Angle Sensor Polarity Rationality";
BA_ "VNSigAllNodes" SG_ 389 StrAngSnsPolRat 1;
BA_ "SignalType" SG_ 389 LatAccSnsPolRat "ENM";
BA_ "SignalLongName" SG_ 389 LatAccSnsPolRat "Lateral Acceleration Sensor Polarity Rationality";
BA_ "VNSigAllNodes" SG_ 389 LatAccSnsPolRat 1;
BA_ "SignalType" SG_ 1922 DTCI_WrnIndRqdSt_782 "BLN";
BA_ "PacketOrder" SG_ 1922 DTCI_WrnIndRqdSt_782 12;
BA_ "SignalLongName" SG_ 1922 DTCI_WrnIndRqdSt_782 "Diagnostic Trouble Code Information Extended 782 : Warning Indicator Requested Status";
BA_ "VNSigAllNodes" SG_ 1922 DTCI_WrnIndRqdSt_782 1;
BA_ "SignalType" SG_ 1922 DTCIUnused7_782 "BLN";
BA_ "PacketOrder" SG_ 1922 DTCIUnused7_782 7;
BA_ "SignalLongName" SG_ 1922 DTCIUnused7_782 "Diagnostic Trouble Code Information Extended 782 : Unused 7";
BA_ "VNSigAllNodes" SG_ 1922 DTCIUnused7_782 1;
BA_ "SignalType" SG_ 1922 DTCIUnused6_782 "BLN";
BA_ "PacketOrder" SG_ 1922 DTCIUnused6_782 6;
BA_ "SignalLongName" SG_ 1922 DTCIUnused6_782 "Diagnostic Trouble Code Information Extended 782 : Unused 6";
BA_ "VNSigAllNodes" SG_ 1922 DTCIUnused6_782 1;
BA_ "SignalType" SG_ 1922 DTCIUnused5_782 "BLN";
BA_ "PacketOrder" SG_ 1922 DTCIUnused5_782 5;
BA_ "SignalLongName" SG_ 1922 DTCIUnused5_782 "Diagnostic Trouble Code Information Extended 782 : Unused 5";
BA_ "VNSigAllNodes" SG_ 1922 DTCIUnused5_782 1;
BA_ "SignalType" SG_ 1922 DTCIUnused4_782 "BLN";
BA_ "PacketOrder" SG_ 1922 DTCIUnused4_782 4;
BA_ "SignalLongName" SG_ 1922 DTCIUnused4_782 "Diagnostic Trouble Code Information Extended 782 : Unused 4";
BA_ "VNSigAllNodes" SG_ 1922 DTCIUnused4_782 1;
BA_ "SignalType" SG_ 1922 DTCIUnused3_782 "BLN";
BA_ "PacketOrder" SG_ 1922 DTCIUnused3_782 3;
BA_ "SignalLongName" SG_ 1922 DTCIUnused3_782 "Diagnostic Trouble Code Information Extended 782 : Unused 3";
BA_ "VNSigAllNodes" SG_ 1922 DTCIUnused3_782 1;
BA_ "SignalType" SG_ 1922 DTCIUnused2_782 "BLN";
BA_ "PacketOrder" SG_ 1922 DTCIUnused2_782 2;
BA_ "SignalLongName" SG_ 1922 DTCIUnused2_782 "Diagnostic Trouble Code Information Extended 782 : Unused 2";
BA_ "VNSigAllNodes" SG_ 1922 DTCIUnused2_782 1;
BA_ "SignalType" SG_ 1922 DTCIUnused1_782 "BLN";
BA_ "PacketOrder" SG_ 1922 DTCIUnused1_782 1;
BA_ "SignalLongName" SG_ 1922 DTCIUnused1_782 "Diagnostic Trouble Code Information Extended 782 : Unused 1";
BA_ "VNSigAllNodes" SG_ 1922 DTCIUnused1_782 1;
BA_ "SignalType" SG_ 1922 DTCI_TstNPsdPwrUpSt_782 "BLN";
BA_ "PacketOrder" SG_ 1922 DTCI_TstNPsdPwrUpSt_782 14;
BA_ "SignalLongName" SG_ 1922 DTCI_TstNPsdPwrUpSt_782 "Diagnostic Trouble Code Information Extended 782 : Test Not Passed Since Power Up Status";
BA_ "VNSigAllNodes" SG_ 1922 DTCI_TstNPsdPwrUpSt_782 1;
BA_ "SignalType" SG_ 1922 DTCI_TstNPsdCdClrdSt_782 "BLN";
BA_ "PacketOrder" SG_ 1922 DTCI_TstNPsdCdClrdSt_782 17;
BA_ "SignalLongName" SG_ 1922 DTCI_TstNPsdCdClrdSt_782 "Diagnostic Trouble Code Information Extended 782 : Test Not Passed Since Code Cleared Status";
BA_ "VNSigAllNodes" SG_ 1922 DTCI_TstNPsdCdClrdSt_782 1;
BA_ "SignalType" SG_ 1922 DTCI_TstFldPwrUpSt_782 "BLN";
BA_ "PacketOrder" SG_ 1922 DTCI_TstFldPwrUpSt_782 13;
BA_ "SignalLongName" SG_ 1922 DTCI_TstFldPwrUpSt_782 "Diagnostic Trouble Code Information Extended 782 : Test Failed Since Power Up Status";
BA_ "VNSigAllNodes" SG_ 1922 DTCI_TstFldPwrUpSt_782 1;
BA_ "SignalType" SG_ 1922 DTCI_TstFldCdClrdStat_782 "BLN";
BA_ "PacketOrder" SG_ 1922 DTCI_TstFldCdClrdStat_782 16;
BA_ "SignalLongName" SG_ 1922 DTCI_TstFldCdClrdStat_782 "Diagnostic Trouble Code Information Extended 782 : Test Failed Since Code Cleared Status";
BA_ "VNSigAllNodes" SG_ 1922 DTCI_TstFldCdClrdStat_782 1;
BA_ "SignalType" SG_ 1922 DTCI_HistStat_782 "BLN";
BA_ "PacketOrder" SG_ 1922 DTCI_HistStat_782 15;
BA_ "SignalLongName" SG_ 1922 DTCI_HistStat_782 "Diagnostic Trouble Code Information Extended 782 : History Status";
BA_ "VNSigAllNodes" SG_ 1922 DTCI_HistStat_782 1;
BA_ "SignalType" SG_ 1922 DTCI_DTCTriggered_782 "BLN";
BA_ "PacketOrder" SG_ 1922 DTCI_DTCTriggered_782 8;
BA_ "SignalLongName" SG_ 1922 DTCI_DTCTriggered_782 "Diagnostic Trouble Code Information Extended 782 : Diagnostic Trouble Code Triggered";
BA_ "VNSigAllNodes" SG_ 1922 DTCI_DTCTriggered_782 1;
BA_ "SignalType" SG_ 1922 DTCI_DTCSource_782 "UNM";
BA_ "PacketOrder" SG_ 1922 DTCI_DTCSource_782 9;
BA_ "SignalLongName" SG_ 1922 DTCI_DTCSource_782 "Diagnostic Trouble Code Information Extended 782 : Diagnostic Trouble Code Source";
BA_ "VNSigAllNodes" SG_ 1922 DTCI_DTCSource_782 1;
BA_ "SignalType" SG_ 1922 DTCI_DTCNumber_782 "UNM";
BA_ "PacketOrder" SG_ 1922 DTCI_DTCNumber_782 10;
BA_ "SignalLongName" SG_ 1922 DTCI_DTCNumber_782 "Diagnostic Trouble Code Information Extended 782 : Diagnostic Trouble Code Number";
BA_ "VNSigAllNodes" SG_ 1922 DTCI_DTCNumber_782 1;
BA_ "SignalType" SG_ 1922 DTCI_DTCFaultType_782 "ENM";
BA_ "PacketOrder" SG_ 1922 DTCI_DTCFaultType_782 20;
BA_ "SignalLongName" SG_ 1922 DTCI_DTCFaultType_782 "Diagnostic Trouble Code Information Extended 782 : Diagnostic Trouble Code Fault Type";
BA_ "VNSigAllNodes" SG_ 1922 DTCI_DTCFaultType_782 1;
BA_ "SignalType" SG_ 1922 DTCI_DTCFailType_782 "UNM";
BA_ "PacketOrder" SG_ 1922 DTCI_DTCFailType_782 11;
BA_ "SignalLongName" SG_ 1922 DTCI_DTCFailType_782 "Diagnostic Trouble Code Information Extended 782 : Diagnostic Trouble Code Failure Type";
BA_ "VNSigAllNodes" SG_ 1922 DTCI_DTCFailType_782 1;
BA_ "SignalType" SG_ 1922 DTCI_CurrentStatus_782 "BLN";
BA_ "PacketOrder" SG_ 1922 DTCI_CurrentStatus_782 18;
BA_ "SignalLongName" SG_ 1922 DTCI_CurrentStatus_782 "Diagnostic Trouble Code Information Extended 782 : Current Status";
BA_ "VNSigAllNodes" SG_ 1922 DTCI_CurrentStatus_782 1;
BA_ "SignalType" SG_ 1922 DTCI_CodeSupported_782 "BLN";
BA_ "PacketOrder" SG_ 1922 DTCI_CodeSupported_782 19;
BA_ "SignalLongName" SG_ 1922 DTCI_CodeSupported_782 "Diagnostic Trouble Code Information Extended 782 : Code Supported";
BA_ "VNSigAllNodes" SG_ 1922 DTCI_CodeSupported_782 1;
BA_ "SignalType" SG_ 352 LrnEnvIdSt "ENM";
BA_ "SignalLongName" SG_ 352 LrnEnvIdSt "Learn Environment Identification Status";
BA_ "VNSigAllNodes" SG_ 352 LrnEnvIdSt 1;
BA_ "SignalType" SG_ 352 LrnEnvId "UNM";
BA_ "SignalLongName" SG_ 352 LrnEnvId "Learn Environment Identification";
BA_ "VNSigAllNodes" SG_ 352 LrnEnvId 1;
BA_ "SignalType" SG_ 352 ImoId "UNM";
BA_ "SignalLongName" SG_ 352 ImoId "Immobilizer Identifier";
BA_ "VNSigAllNodes" SG_ 352 ImoId 1;
BA_ "SignalType" SG_ 352 ImoIdSt "ENM";
BA_ "SignalLongName" SG_ 352 ImoIdSt "Immobilizer Identifier Status";
BA_ "VNSigAllNodes" SG_ 352 ImoIdSt 1;
BA_ "SignalType" SG_ 562 SndPerfMdCsStAvl "BLN";
BA_ "SignalLongName" SG_ 562 SndPerfMdCsStAvl "Sound Performance Mode Customization Setting Available";
BA_ "VNSigAllNodes" SG_ 562 SndPerfMdCsStAvl 1;
BA_ "SignalType" SG_ 562 SndPerfMdCsCrStVal "ENM";
BA_ "SignalLongName" SG_ 562 SndPerfMdCsCrStVal "Sound Performance Mode Customization Current Setting Value";
BA_ "VNSigAllNodes" SG_ 562 SndPerfMdCsCrStVal 1;
BA_ "SignalType" SG_ 562 DispPerfMdCsStAvl "BLN";
BA_ "SignalLongName" SG_ 562 DispPerfMdCsStAvl "Display Performance Mode Customization Setting Available";
BA_ "VNSigAllNodes" SG_ 562 DispPerfMdCsStAvl 1;
BA_ "SignalType" SG_ 562 DispPerfMdCsCrStVal "ENM";
BA_ "SignalLongName" SG_ 562 DispPerfMdCsCrStVal "Display Performance Mode Customization Current Setting Value";
BA_ "VNSigAllNodes" SG_ 562 DispPerfMdCsCrStVal 1;
BA_ "SignalType" SG_ 562 DrvlneMntsPerfMdRq "ENM";
BA_ "SignalLongName" SG_ 562 DrvlneMntsPerfMdRq "Driveline Mounts Performance Mode Request";
BA_ "VNSigAllNodes" SG_ 562 DrvlneMntsPerfMdRq 1;
BA_ "SignalType" SG_ 562 RideCntrlPerfMdRq "ENM";
BA_ "SignalLongName" SG_ 562 RideCntrlPerfMdRq "Ride Control Performance Mode Request";
BA_ "VNSigAllNodes" SG_ 562 RideCntrlPerfMdRq 1;
BA_ "SignalType" SG_ 562 StgSysPerfMdRq "ENM";
BA_ "SignalLongName" SG_ 562 StgSysPerfMdRq "Steering System Performance Mode Request";
BA_ "VNSigAllNodes" SG_ 562 StgSysPerfMdRq 1;
BA_ "SignalType" SG_ 562 DiffPerfMdRq "ENM";
BA_ "SignalLongName" SG_ 562 DiffPerfMdRq "Differential Performance Mode Request";
BA_ "VNSigAllNodes" SG_ 562 DiffPerfMdRq 1;
BA_ "SignalType" SG_ 562 SndEnhcmtPerfMdRq "ENM";
BA_ "SignalLongName" SG_ 562 SndEnhcmtPerfMdRq "Sound Enhancement Performance Mode Request";
BA_ "VNSigAllNodes" SG_ 562 SndEnhcmtPerfMdRq 1;
BA_ "SignalType" SG_ 562 DsplyPerfMdRq "ENM";
BA_ "SignalLongName" SG_ 562 DsplyPerfMdRq "Display Performance Mode Request";
BA_ "VNSigAllNodes" SG_ 562 DsplyPerfMdRq 1;
BA_ "SignalType" SG_ 562 ExhstPerfMdRq "ENM";
BA_ "SignalLongName" SG_ 562 ExhstPerfMdRq "Exhaust Performance Mode Request";
BA_ "VNSigAllNodes" SG_ 562 ExhstPerfMdRq 1;
BA_ "SignalType" SG_ 562 HillDscntCntlSysStat "ENM";
BA_ "SignalLongName" SG_ 562 HillDscntCntlSysStat "Hill Descent Control System Status";
BA_ "VNSigAllNodes" SG_ 562 HillDscntCntlSysStat 1;
BA_ "SignalType" SG_ 562 SusCustStngAvlbl "BLN";
BA_ "SignalLongName" SG_ 562 SusCustStngAvlbl "Suspension Customization Setting Available";
BA_ "VNSigAllNodes" SG_ 562 SusCustStngAvlbl 1;
BA_ "SignalType" SG_ 562 SusCustCurrStngVal "ENM";
BA_ "SignalLongName" SG_ 562 SusCustCurrStngVal "Suspension Customization Current Setting Value";
BA_ "VNSigAllNodes" SG_ 562 SusCustCurrStngVal 1;
BA_ "SignalType" SG_ 562 StrCustStngAvlbl "BLN";
BA_ "SignalLongName" SG_ 562 StrCustStngAvlbl "Steering Customization Setting Available";
BA_ "VNSigAllNodes" SG_ 562 StrCustStngAvlbl 1;
BA_ "SignalType" SG_ 562 StrCustCurrStngVal "ENM";
BA_ "SignalLongName" SG_ 562 StrCustCurrStngVal "Steering Customization Current Setting Value";
BA_ "VNSigAllNodes" SG_ 562 StrCustCurrStngVal 1;
BA_ "SignalType" SG_ 562 DrvlnCustStngAvlbl "BLN";
BA_ "SignalLongName" SG_ 562 DrvlnCustStngAvlbl "Driveline Customization Setting Available";
BA_ "VNSigAllNodes" SG_ 562 DrvlnCustStngAvlbl 1;
BA_ "SignalType" SG_ 562 DrvMdCntrlState "UNM";
BA_ "SignalLongName" SG_ 562 DrvMdCntrlState "Driving Mode Control State";
BA_ "VNSigAllNodes" SG_ 562 DrvMdCntrlState 1;
BA_ "SignalType" SG_ 562 AWDPerfMdRq "ENM";
BA_ "SignalLongName" SG_ 562 AWDPerfMdRq "AWD Performance Mode Request";
BA_ "VNSigAllNodes" SG_ 562 AWDPerfMdRq 1;
BA_ "SignalType" SG_ 562 DrvlnCustCurrStngVal "ENM";
BA_ "SignalLongName" SG_ 562 DrvlnCustCurrStngVal "Driveline Customization Current Setting Value";
BA_ "VNSigAllNodes" SG_ 562 DrvlnCustCurrStngVal 1;
BA_ "SignalType" SG_ 893 AFLGPSCstStAvl "BLN";
BA_ "SignalLongName" SG_ 893 AFLGPSCstStAvl "Adaptive Forward Lighting With GPS Customization Setting Available";
BA_ "VNSigAllNodes" SG_ 893 AFLGPSCstStAvl 1;
BA_ "SignalType" SG_ 893 AFLGPSCstCrStVal "ENM";
BA_ "SignalLongName" SG_ 893 AFLGPSCstCrStVal "Adaptive Forward Lighting With GPS Customization Current Setting Value";
BA_ "VNSigAllNodes" SG_ 893 AFLGPSCstCrStVal 1;
BA_ "SignalType" SG_ 893 AFLCstStAvl "BLN";
BA_ "SignalLongName" SG_ 893 AFLCstStAvl "Adaptive Forward Lighting Customization Setting Available";
BA_ "VNSigAllNodes" SG_ 893 AFLCstStAvl 1;
BA_ "SignalType" SG_ 893 AFLCstCrStVal "ENM";
BA_ "SignalLongName" SG_ 893 AFLCstCrStVal "Adaptive Forward Lighting Customization Current Setting Value";
BA_ "VNSigAllNodes" SG_ 893 AFLCstCrStVal 1;
BA_ "SignalType" SG_ 892 AdpHgBmAsSnCsCrStVal "ENM";
BA_ "SignalLongName" SG_ 892 AdpHgBmAsSnCsCrStVal "Adaptive High Beam Assist With Sensitivity Customization Current Setting Value";
BA_ "VNSigAllNodes" SG_ 892 AdpHgBmAsSnCsCrStVal 1;
BA_ "SignalType" SG_ 892 AdpHgBmAsSnCsStAvl "BLN";
BA_ "SignalLongName" SG_ 892 AdpHgBmAsSnCsStAvl "Adaptive High Beam Assist With Sensitivity Customization Setting Available";
BA_ "VNSigAllNodes" SG_ 892 AdpHgBmAsSnCsStAvl 1;
BA_ "SignalType" SG_ 892 AdpHgBmAsCsCrStVal "ENM";
BA_ "SignalLongName" SG_ 892 AdpHgBmAsCsCrStVal "Adaptive High Beam Assist Customization Current Setting Value";
BA_ "VNSigAllNodes" SG_ 892 AdpHgBmAsCsCrStVal 1;
BA_ "SignalType" SG_ 892 AdpHgBmAsCsStAvl "BLN";
BA_ "SignalLongName" SG_ 892 AdpHgBmAsCsStAvl "Adaptive High Beam Assist Customization Setting Available";
BA_ "VNSigAllNodes" SG_ 892 AdpHgBmAsCsStAvl 1;
BA_ "SignalType" SG_ 892 AutHgBmAsCsCrStVal "ENM";
BA_ "SignalLongName" SG_ 892 AutHgBmAsCsCrStVal "Auto High Beam Assist Customization Current Setting Value";
BA_ "VNSigAllNodes" SG_ 892 AutHgBmAsCsCrStVal 1;
BA_ "SignalType" SG_ 892 AutHgBmAsSnCsStAvl "BLN";
BA_ "SignalLongName" SG_ 892 AutHgBmAsSnCsStAvl "Auto High Beam Assist With Sensitivity Customization Setting Available";
BA_ "VNSigAllNodes" SG_ 892 AutHgBmAsSnCsStAvl 1;
BA_ "SignalType" SG_ 892 AutHgBmAsSnCsCrStVa "ENM";
BA_ "SignalLongName" SG_ 892 AutHgBmAsSnCsCrStVa "Auto High Beam Assist With Sensitivity Customization Current Setting Value";
BA_ "VNSigAllNodes" SG_ 892 AutHgBmAsSnCsCrStVa 1;
BA_ "SignalType" SG_ 892 AutHgBmAsCsStAvl "BLN";
BA_ "SignalLongName" SG_ 892 AutHgBmAsCsStAvl "Auto High Beam Assist Customization Setting Available";
BA_ "VNSigAllNodes" SG_ 892 AutHgBmAsCsStAvl 1;
BA_ "SignalType" SG_ 386 EnvIdRsp4 "UNM";
BA_ "SignalLongName" SG_ 386 EnvIdRsp4 "Environment Identification Response 4";
BA_ "VNSigAllNodes" SG_ 386 EnvIdRsp4 1;
BA_ "SignalType" SG_ 386 EnvIdRspSt4 "ENM";
BA_ "SignalLongName" SG_ 386 EnvIdRspSt4 "Environment Identification Response Status 4";
BA_ "VNSigAllNodes" SG_ 386 EnvIdRspSt4 1;
BA_ "VNSigSLHSSharedDiagnostic" SG_ 597 DgnInf 1;
BA_ "SignalType" SG_ 597 DgnInf "UNM";
BA_ "SignalLongName" SG_ 597 DgnInf "Diagnostic Information";
BA_ "VNSigAllNodes" SG_ 597 DgnInf 1;
BA_ "VNSigSLHSSharedDiagnostic" SG_ 1621 DgnInf 1;
BA_ "SignalType" SG_ 1621 DgnInf "UNM";
BA_ "SignalLongName" SG_ 1621 DgnInf "Diagnostic Information";
BA_ "VNSigAllNodes" SG_ 1621 DgnInf 1;
BA_ "SignalType" SG_ 532 RedntVSEActARC "UNM";
BA_ "SignalLongName" SG_ 532 RedntVSEActARC "Redundant Vehicle Stability Enhancement System Active Alive Rolling Count";
BA_ "VNSigAllNodes" SG_ 532 RedntVSEActARC 1;
BA_ "SignalType" SG_ 532 RedntVSEAct "BLN";
BA_ "SignalLongName" SG_ 532 RedntVSEAct "Redundant Vehicle Stability Enhancement System Active";
BA_ "VNSigAllNodes" SG_ 532 RedntVSEAct 1;
BA_ "SignalType" SG_ 532 AutoBrkngActARC "UNM";
BA_ "SignalLongName" SG_ 532 AutoBrkngActARC "Automatic Braking Active Alive Rolling Count";
BA_ "VNSigAllNodes" SG_ 532 AutoBrkngActARC 1;
BA_ "SignalType" SG_ 532 ABSAutnmsBrkReqPVal "UNM";
BA_ "SignalLongName" SG_ 532 ABSAutnmsBrkReqPVal "Antilock Brake System Autonomous Braking Request Protection Value";
BA_ "VNSigAllNodes" SG_ 532 ABSAutnmsBrkReqPVal 1;
BA_ "SignalType" SG_ 532 AutoBrkngAvlbl "BLN";
BA_ "SignalLongName" SG_ 532 AutoBrkngAvlbl "Automatic Braking Available";
BA_ "VNSigAllNodes" SG_ 532 AutoBrkngAvlbl 1;
BA_ "SignalType" SG_ 532 ABSAutnmsBrkReqARC "UNM";
BA_ "SignalLongName" SG_ 532 ABSAutnmsBrkReqARC "Antilock Brake System Autonomous Braking Request Alive Rolling Count";
BA_ "VNSigAllNodes" SG_ 532 ABSAutnmsBrkReqARC 1;
BA_ "SignalType" SG_ 532 ABSAutnmsBrkReq "BLN";
BA_ "SignalLongName" SG_ 532 ABSAutnmsBrkReq "Antilock Brake System Autonomous Braking Request";
BA_ "VNSigAllNodes" SG_ 532 ABSAutnmsBrkReq 1;
BA_ "SignalType" SG_ 532 ABSActvProtPVal "UNM";
BA_ "SignalLongName" SG_ 532 ABSActvProtPVal "Antilock Brake System Active Protected Protection Value";
BA_ "VNSigAllNodes" SG_ 532 ABSActvProtPVal 1;
BA_ "SignalType" SG_ 532 ABSActvProtARC "UNM";
BA_ "SignalLongName" SG_ 532 ABSActvProtARC "Antilock Brake System Active Protected Alive Rolling Count";
BA_ "VNSigAllNodes" SG_ 532 ABSActvProtARC 1;
BA_ "SignalType" SG_ 532 HlStrAssActIO "BLN";
BA_ "SignalLongName" SG_ 532 HlStrAssActIO "Hill Start Assist Active Indication On";
BA_ "VNSigAllNodes" SG_ 532 HlStrAssActIO 1;
BA_ "SignalType" SG_ 532 ABSActvProt "BLN";
BA_ "SignalLongName" SG_ 532 ABSActvProt "Antilock Brake System Active Protected";
BA_ "VNSigAllNodes" SG_ 532 ABSActvProt 1;
BA_ "SignalType" SG_ 532 BrkSysAutBrkFld "BLN";
BA_ "SignalLongName" SG_ 532 BrkSysAutBrkFld "Brake System Automatic Braking Failed";
BA_ "VNSigAllNodes" SG_ 532 BrkSysAutBrkFld 1;
BA_ "SignalType" SG_ 532 IntBrkAssPreFilReq "BLN";
BA_ "SignalLongName" SG_ 532 IntBrkAssPreFilReq "Inteligent Brake Assist Pre-Fil Request";
BA_ "VNSigAllNodes" SG_ 532 IntBrkAssPreFilReq 1;
BA_ "SignalType" SG_ 532 BrkSysMalFuncIndOn "BLN";
BA_ "SignalLongName" SG_ 532 BrkSysMalFuncIndOn "Brake System Malfunction Indication On";
BA_ "VNSigAllNodes" SG_ 532 BrkSysMalFuncIndOn 1;
BA_ "SignalType" SG_ 532 BrkPdDrvAPrsStaPVal "UNM";
BA_ "SignalLongName" SG_ 532 BrkPdDrvAPrsStaPVal "Brake Pedal Driver Applied Pressure Status Protection Value";
BA_ "VNSigAllNodes" SG_ 532 BrkPdDrvAPrsStaPVal 1;
BA_ "SignalType" SG_ 532 BPDAPS_BkPDrvApPV "ENM";
BA_ "PacketOrder" SG_ 532 BPDAPS_BkPDrvApPV 2;
BA_ "SignalLongName" SG_ 532 BPDAPS_BkPDrvApPV "Brake Pedal Driver Applied Pressure Status : Brake Pedal Driver Applied Pressure Validity";
BA_ "VNSigAllNodes" SG_ 532 BPDAPS_BkPDrvApPV 1;
BA_ "SignalType" SG_ 532 BPDAPS_BkPDrvApP "UNM";
BA_ "PacketOrder" SG_ 532 BPDAPS_BkPDrvApP 1;
BA_ "SignalLongName" SG_ 532 BPDAPS_BkPDrvApP "Brake Pedal Driver Applied Pressure Status : Brake Pedal Driver Applied Pressure";
BA_ "VNSigAllNodes" SG_ 532 BPDAPS_BkPDrvApP 1;
BA_ "SignalType" SG_ 532 BrkPdDrvAppPrsAlRC "UNM";
BA_ "SignalLongName" SG_ 532 BrkPdDrvAppPrsAlRC "Brake Pedal Driver Applied Pressure Alive Rolling Count";
BA_ "VNSigAllNodes" SG_ 532 BrkPdDrvAppPrsAlRC 1;
BA_ "SignalType" SG_ 532 BrkFldLvlLwV "ENM";
BA_ "SignalLongName" SG_ 532 BrkFldLvlLwV "Brake Fluid Level Low Validity";
BA_ "VNSigAllNodes" SG_ 532 BrkFldLvlLwV 1;
BA_ "SignalType" SG_ 532 AutoBrkngAct "BLN";
BA_ "SignalLongName" SG_ 532 AutoBrkngAct "Automatic Braking Active";
BA_ "VNSigAllNodes" SG_ 532 AutoBrkngAct 1;
BA_ "SignalType" SG_ 532 BrkFldLvlLw "BLN";
BA_ "SignalLongName" SG_ 532 BrkFldLvlLw "Brake Fluid Level Low";
BA_ "VNSigAllNodes" SG_ 532 BrkFldLvlLw 1;
BA_ "SignalType" SG_ 890 LtRtHnTrGPCsCrStVal "ENM";
BA_ "SignalLongName" SG_ 890 LtRtHnTrGPCsCrStVal "Left Right Hand Traffic With GPS Customization Current Setting Value";
BA_ "VNSigAllNodes" SG_ 890 LtRtHnTrGPCsCrStVal 1;
BA_ "SignalType" SG_ 890 LtRtHnTrGPSCsStAvl "BLN";
BA_ "SignalLongName" SG_ 890 LtRtHnTrGPSCsStAvl "Left Right Hand Traffic With GPS Customization Setting Available";
BA_ "VNSigAllNodes" SG_ 890 LtRtHnTrGPSCsStAvl 1;
BA_ "SignalType" SG_ 890 LtRtHnTrCstStVal "ENM";
BA_ "SignalLongName" SG_ 890 LtRtHnTrCstStVal "Left Right Hand Traffic Customization Current Setting Value";
BA_ "VNSigAllNodes" SG_ 890 LtRtHnTrCstStVal 1;
BA_ "SignalType" SG_ 890 LtRtHnTrCstStAvail "ENM";
BA_ "SignalLongName" SG_ 890 LtRtHnTrCstStAvail "Left Right Hand Traffic Customization Setting Available";
BA_ "VNSigAllNodes" SG_ 890 LtRtHnTrCstStAvail 1;
BA_ "VNSigSLHSSharedDiagnostic" SG_ 592 DgnInf 1;
BA_ "SignalType" SG_ 592 DgnInf "UNM";
BA_ "SignalLongName" SG_ 592 DgnInf "Diagnostic Information";
BA_ "VNSigAllNodes" SG_ 592 DgnInf 1;
BA_ "VNSigSLHSSharedDiagnostic" SG_ 1365 DgnInf_HS555 1;
BA_ "SignalType" SG_ 1365 DgnInf_HS555 "UNM";
BA_ "SignalLongName" SG_ 1365 DgnInf_HS555 "Diagnostic Information HS555";
BA_ "VNSigAllNodes" SG_ 1365 DgnInf_HS555 1;
BA_ "GenSigSendType" SG_ 328 StrngAsstRdcdIO 10;
BA_ "SignalType" SG_ 328 StrngAsstRdcdIO "BLN";
BA_ "SignalLongName" SG_ 328 StrngAsstRdcdIO "Steering Assist Reduced Indication On";
BA_ "VNSigAllNodes" SG_ 328 StrngAsstRdcdIO 1;
BA_ "GenSigSendType" SG_ 328 PwrStrIO 10;
BA_ "SignalType" SG_ 328 PwrStrIO "BLN";
BA_ "SignalLongName" SG_ 328 PwrStrIO "Power Steering Indication On";
BA_ "VNSigAllNodes" SG_ 328 PwrStrIO 1;
BA_ "SignalType" SG_ 560 ElecPrkBrkCmdProt "UNM";
BA_ "SignalLongName" SG_ 560 ElecPrkBrkCmdProt "Electric Park Brake Command Protection";
BA_ "VNSigAllNodes" SG_ 560 ElecPrkBrkCmdProt 1;
BA_ "SignalType" SG_ 560 ElecPrkBrkSwStatV "ENM";
BA_ "SignalLongName" SG_ 560 ElecPrkBrkSwStatV "Electric Park Brake Switch Status Validity";
BA_ "VNSigAllNodes" SG_ 560 ElecPrkBrkSwStatV 1;
BA_ "SignalType" SG_ 560 ElecPrkBrkCmdARC "UNM";
BA_ "SignalLongName" SG_ 560 ElecPrkBrkCmdARC "Electric Park Brake Command Alive Rolling Count";
BA_ "VNSigAllNodes" SG_ 560 ElecPrkBrkCmdARC 1;
BA_ "SignalType" SG_ 560 ElecPrkBrkSwStat "ENM";
BA_ "SignalLongName" SG_ 560 ElecPrkBrkSwStat "Electric Park Brake Switch Status";
BA_ "VNSigAllNodes" SG_ 560 ElecPrkBrkSwStat 1;
BA_ "VNSigSLHS_VNReq" SG_ 560 AllNodesVNA 1;
BA_ "SignalType" SG_ 560 AllNodesVNA "ENM";
BA_ "SignalLongName" SG_ 560 AllNodesVNA "All Nodes Virtual Network Activation";
BA_ "VNSigAllNodes" SG_ 560 AllNodesVNA 1;
BA_ "SignalType" SG_ 560 StpOnBrkToRelPBIndOn "BLN";
BA_ "SignalLongName" SG_ 560 StpOnBrkToRelPBIndOn "Step On Brake To Release Park Brake Indication On";
BA_ "VNSigAllNodes" SG_ 560 StpOnBrkToRelPBIndOn 1;
BA_ "SignalType" SG_ 560 EPBC_EPBAccRq "SNM";
BA_ "PacketOrder" SG_ 560 EPBC_EPBAccRq 2;
BA_ "SignalLongName" SG_ 560 EPBC_EPBAccRq "Electric Park Brake Command : Electric Park Brake Acceleration Requested";
BA_ "VNSigAllNodes" SG_ 560 EPBC_EPBAccRq 1;
BA_ "SignalType" SG_ 560 EPBC_EPBrkAutBrkRq "BLN";
BA_ "PacketOrder" SG_ 560 EPBC_EPBrkAutBrkRq 1;
BA_ "SignalLongName" SG_ 560 EPBC_EPBrkAutBrkRq "Electric Park Brake Command : Electric Park Brake Automatic Braking Requested";
BA_ "VNSigAllNodes" SG_ 560 EPBC_EPBrkAutBrkRq 1;
BA_ "SignalType" SG_ 560 EPBSysDspMsgReq "ENM";
BA_ "SignalLongName" SG_ 560 EPBSysDspMsgReq "Electric Park Brake System Display Message Request";
BA_ "VNSigAllNodes" SG_ 560 EPBSysDspMsgReq 1;
BA_ "SignalType" SG_ 560 EPBSysAudWarnReq "ENM";
BA_ "SignalLongName" SG_ 560 EPBSysAudWarnReq "Electric Park Brake System Audible Warning Request";
BA_ "VNSigAllNodes" SG_ 560 EPBSysAudWarnReq 1;
BA_ "SignalType" SG_ 560 ElecPrkBrkStat "ENM";
BA_ "SignalLongName" SG_ 560 ElecPrkBrkStat "Electric Park Brake Status";
BA_ "VNSigAllNodes" SG_ 560 ElecPrkBrkStat 1;
BA_ "SignalType" SG_ 560 EPBCrsCanRq "BLN";
BA_ "SignalLongName" SG_ 560 EPBCrsCanRq "Electric Park Brake Cruise Control Cancel Requested";
BA_ "VNSigAllNodes" SG_ 560 EPBCrsCanRq 1;
BA_ "SignalType" SG_ 560 EPBSysStatIndReq "ENM";
BA_ "SignalLongName" SG_ 560 EPBSysStatIndReq "Electric Park Brake System Status Indication Request";
BA_ "VNSigAllNodes" SG_ 560 EPBSysStatIndReq 1;
BA_ "SignalType" SG_ 560 EPBSysWrnIndReq "ENM";
BA_ "SignalLongName" SG_ 560 EPBSysWrnIndReq "Electric Park Brake System Warning Indication Request";
BA_ "VNSigAllNodes" SG_ 560 EPBSysWrnIndReq 1;
BA_ "SignalType" SG_ 560 EPBSysBrkLtsReq "BLN";
BA_ "SignalLongName" SG_ 560 EPBSysBrkLtsReq "Electric Park Brake System Brake Lights Requested";
BA_ "VNSigAllNodes" SG_ 560 EPBSysBrkLtsReq 1;
BA_ "SignalType" SG_ 383 AFSSysFail "BLN";
BA_ "SignalLongName" SG_ 383 AFSSysFail "Active Front Steering System Failed";
BA_ "VNSigAllNodes" SG_ 383 AFSSysFail 1;
BA_ "SignalType" SG_ 383 StSysVehTopSpdLimReq "UNM";
BA_ "SignalLongName" SG_ 383 StSysVehTopSpdLimReq "Steering System Vehicle Top Speed Limit Request";
BA_ "VNSigAllNodes" SG_ 383 StSysVehTopSpdLimReq 1;
BA_ "SignalType" SG_ 383 FrStSysVeTpSpLimIndOn "BLN";
BA_ "SignalLongName" SG_ 383 FrStSysVeTpSpLimIndOn "Front Steering System Vehicle Top Speed Limitation Indication On";
BA_ "VNSigAllNodes" SG_ 383 FrStSysVeTpSpLimIndOn 1;
BA_ "SignalType" SG_ 383 AFSIndOn "BLN";
BA_ "SignalLongName" SG_ 383 AFSIndOn "Active Front Steering Indication On";
BA_ "VNSigAllNodes" SG_ 383 AFSIndOn 1;
BA_ "SignalType" SG_ 451 GlwPlgCrnkDelAct "BLN";
BA_ "SignalLongName" SG_ 451 GlwPlgCrnkDelAct "Glow Plugs Crank Delay Active";
BA_ "VNSigAllNodes" SG_ 451 GlwPlgCrnkDelAct 1;
BA_ "SignalType" SG_ 451 PltfrmEngSpdCmmndSt "ENM";
BA_ "SignalLongName" SG_ 451 PltfrmEngSpdCmmndSt "Platform Engine Speed Command Status";
BA_ "VNSigAllNodes" SG_ 451 PltfrmEngSpdCmmndSt 1;
BA_ "SignalType" SG_ 451 AuxHtrAlwd "BLN";
BA_ "SignalLongName" SG_ 451 AuxHtrAlwd "Auxiliary Heater Allowed";
BA_ "VNSigAllNodes" SG_ 451 AuxHtrAlwd 1;
BA_ "SignalType" SG_ 451 EconMdRqDndIO "BLN";
BA_ "SignalLongName" SG_ 451 EconMdRqDndIO "Economy Mode Request Denied Indication On";
BA_ "VNSigAllNodes" SG_ 451 EconMdRqDndIO 1;
BA_ "SignalType" SG_ 451 EconMdAtvIO "BLN";
BA_ "SignalLongName" SG_ 451 EconMdAtvIO "Economy Mode Active Indication On";
BA_ "VNSigAllNodes" SG_ 451 EconMdAtvIO 1;
BA_ "SignalType" SG_ 451 AppCltchAutSrtIO "BLN";
BA_ "SignalLongName" SG_ 451 AppCltchAutSrtIO "Apply Clutch For Automatic Start Indication On";
BA_ "VNSigAllNodes" SG_ 451 AppCltchAutSrtIO 1;
BA_ "SignalType" SG_ 451 AccPosV "ENM";
BA_ "SignalLongName" SG_ 451 AccPosV "Accelerator Effective Position Validity";
BA_ "VNSigAllNodes" SG_ 451 AccPosV 1;
BA_ "SignalType" SG_ 451 AccPos "UNM";
BA_ "SignalLongName" SG_ 451 AccPos "Accelerator Effective Position";
BA_ "VNSigAllNodes" SG_ 451 AccPos 1;
BA_ "SignalType" SG_ 451 FuelFltRmnLf "UNM";
BA_ "SignalLongName" SG_ 451 FuelFltRmnLf "Fuel Filter Remaining Life";
BA_ "VNSigAllNodes" SG_ 451 FuelFltRmnLf 1;
BA_ "SignalType" SG_ 451 EngTrqRdFlrSt "ENM";
BA_ "SignalLongName" SG_ 451 EngTrqRdFlrSt "Engine Torque Reduction Failure Status";
BA_ "VNSigAllNodes" SG_ 451 EngTrqRdFlrSt 1;
BA_ "SignalType" SG_ 451 EngTrqDrRqdExtRngV "ENM";
BA_ "SignalLongName" SG_ 451 EngTrqDrRqdExtRngV "Engine Torque Driver Requested Extended Range Validity";
BA_ "VNSigAllNodes" SG_ 451 EngTrqDrRqdExtRngV 1;
BA_ "SignalType" SG_ 451 EngTrqDrRqdExtRng "UNM";
BA_ "SignalLongName" SG_ 451 EngTrqDrRqdExtRng "Engine Torque Driver Requested Extended Range";
BA_ "GenSigStartValue" SG_ 451 EngTrqDrRqdExtRng 1696;
BA_ "VNSigAllNodes" SG_ 451 EngTrqDrRqdExtRng 1;
BA_ "SignalType" SG_ 451 EngTrqActExtRngV "ENM";
BA_ "SignalLongName" SG_ 451 EngTrqActExtRngV "Engine Torque Actual Extended Range Validity";
BA_ "VNSigAllNodes" SG_ 451 EngTrqActExtRngV 1;
BA_ "SignalType" SG_ 451 EngTrqActExtRng "UNM";
BA_ "SignalLongName" SG_ 451 EngTrqActExtRng "Engine Torque Actual Extended Range";
BA_ "GenSigStartValue" SG_ 451 EngTrqActExtRng 1696;
BA_ "VNSigAllNodes" SG_ 451 EngTrqActExtRng 1;
BA_ "SignalType" SG_ 801 WhlBdySnsHmPosLrnd "BLN";
BA_ "SignalLongName" SG_ 801 WhlBdySnsHmPosLrnd "Wheel to Body Sensors Home Position Learned";
BA_ "VNSigAllNodes" SG_ 801 WhlBdySnsHmPosLrnd 1;
BA_ "SignalType" SG_ 801 WBRP_ARC "UNM";
BA_ "SignalLongName" SG_ 801 WBRP_ARC "Wheel to Body Relative Position : Alive Rolling Count";
BA_ "VNSigAllNodes" SG_ 801 WBRP_ARC 1;
BA_ "SignalType" SG_ 801 WBRP_Tmestmp "UNM";
BA_ "SignalLongName" SG_ 801 WBRP_Tmestmp "Wheel to Body Relative Position : Timestamp";
BA_ "VNSigAllNodes" SG_ 801 WBRP_Tmestmp 1;
BA_ "SignalType" SG_ 801 WBRP_RtFrtV "ENM";
BA_ "SignalLongName" SG_ 801 WBRP_RtFrtV "Wheel to Body Relative Position : Right Front Validity";
BA_ "VNSigAllNodes" SG_ 801 WBRP_RtFrtV 1;
BA_ "SignalType" SG_ 801 WBRP_RtFrt "SNM";
BA_ "SignalLongName" SG_ 801 WBRP_RtFrt "Wheel to Body Relative Position : Right Front";
BA_ "VNSigAllNodes" SG_ 801 WBRP_RtFrt 1;
BA_ "SignalType" SG_ 801 WBRP_RtRrV "ENM";
BA_ "SignalLongName" SG_ 801 WBRP_RtRrV "Wheel to Body Relative Position : Right Rear Validity";
BA_ "VNSigAllNodes" SG_ 801 WBRP_RtRrV 1;
BA_ "SignalType" SG_ 801 WBRP_RtRr "SNM";
BA_ "SignalLongName" SG_ 801 WBRP_RtRr "Wheel to Body Relative Position : Right Rear";
BA_ "VNSigAllNodes" SG_ 801 WBRP_RtRr 1;
BA_ "SignalType" SG_ 801 WBRP_LftRrV "ENM";
BA_ "SignalLongName" SG_ 801 WBRP_LftRrV "Wheel to Body Relative Position : Left Rear Validity";
BA_ "VNSigAllNodes" SG_ 801 WBRP_LftRrV 1;
BA_ "SignalType" SG_ 801 WBRP_LftRr "SNM";
BA_ "SignalLongName" SG_ 801 WBRP_LftRr "Wheel to Body Relative Position : Left Rear";
BA_ "VNSigAllNodes" SG_ 801 WBRP_LftRr 1;
BA_ "SignalType" SG_ 801 WBRP_LftFrtV "ENM";
BA_ "SignalLongName" SG_ 801 WBRP_LftFrtV "Wheel to Body Relative Position : Left Front Validity";
BA_ "VNSigAllNodes" SG_ 801 WBRP_LftFrtV 1;
BA_ "SignalType" SG_ 801 WBRP_LftFrt "SNM";
BA_ "SignalLongName" SG_ 801 WBRP_LftFrt "Wheel to Body Relative Position : Left Front";
BA_ "VNSigAllNodes" SG_ 801 WBRP_LftFrt 1;
BA_ "GenSigSendType" SG_ 320 BrkLtsAtv 10;
BA_ "SignalType" SG_ 320 BrkLtsAtv "BLN";
BA_ "SignalLongName" SG_ 320 BrkLtsAtv "Brake Lights Active";
BA_ "VNSigAllNodes" SG_ 320 BrkLtsAtv 1;
BA_ "GenSigSendType" SG_ 320 TrnSwAct 10;
BA_ "SignalType" SG_ 320 TrnSwAct "ENM";
BA_ "SignalLongName" SG_ 320 TrnSwAct "Turn Switch Activation";
BA_ "VNSigAllNodes" SG_ 320 TrnSwAct 1;
BA_ "GenSigSendType" SG_ 320 RrFogLmpsAct 10;
BA_ "SignalType" SG_ 320 RrFogLmpsAct "BLN";
BA_ "SignalLongName" SG_ 320 RrFogLmpsAct "Rear Fog Lamps Active";
BA_ "VNSigAllNodes" SG_ 320 RrFogLmpsAct 1;
BA_ "GenSigSendType" SG_ 320 OtsdAmbtLtLvlStatV 10;
BA_ "SignalType" SG_ 320 OtsdAmbtLtLvlStatV "ENM";
BA_ "SignalLongName" SG_ 320 OtsdAmbtLtLvlStatV "Outside Ambient Light Level Status Validity";
BA_ "VNSigAllNodes" SG_ 320 OtsdAmbtLtLvlStatV 1;
BA_ "GenSigSendType" SG_ 320 OtsdAmbtLtLvlStat 10;
BA_ "SignalType" SG_ 320 OtsdAmbtLtLvlStat "ENM";
BA_ "SignalLongName" SG_ 320 OtsdAmbtLtLvlStat "Outside Ambient Light Level Status";
BA_ "VNSigAllNodes" SG_ 320 OtsdAmbtLtLvlStat 1;
BA_ "GenSigSendType" SG_ 320 MainLghtSw 10;
BA_ "SignalType" SG_ 320 MainLghtSw "ENM";
BA_ "SignalLongName" SG_ 320 MainLghtSw "Main Light Switch";
BA_ "VNSigAllNodes" SG_ 320 MainLghtSw 1;
BA_ "GenSigSendType" SG_ 320 LowBmAct 10;
BA_ "SignalType" SG_ 320 LowBmAct "BLN";
BA_ "SignalLongName" SG_ 320 LowBmAct "Low Beam Active";
BA_ "VNSigAllNodes" SG_ 320 LowBmAct 1;
BA_ "GenSigSendType" SG_ 320 HighBmAct 10;
BA_ "SignalType" SG_ 320 HighBmAct "BLN";
BA_ "SignalLongName" SG_ 320 HighBmAct "High Beam Active";
BA_ "VNSigAllNodes" SG_ 320 HighBmAct 1;
BA_ "GenSigSendType" SG_ 320 HdlmpBmSelectStat 10;
BA_ "SignalType" SG_ 320 HdlmpBmSelectStat "ENM";
BA_ "SignalLongName" SG_ 320 HdlmpBmSelectStat "Headlamp Beam Select Status";
BA_ "VNSigAllNodes" SG_ 320 HdlmpBmSelectStat 1;
BA_ "GenSigSendType" SG_ 320 FlToPsSwAtv 10;
BA_ "SignalType" SG_ 320 FlToPsSwAtv "BLN";
BA_ "SignalLongName" SG_ 320 FlToPsSwAtv "Flash To Pass Switch Active";
BA_ "VNSigAllNodes" SG_ 320 FlToPsSwAtv 1;
BA_ "GenSigSendType" SG_ 320 AdvFrntLghtSysEnbld 10;
BA_ "SignalType" SG_ 320 AdvFrntLghtSysEnbld "BLN";
BA_ "SignalLongName" SG_ 320 AdvFrntLghtSysEnbld "Advanced Front Lighting System Enabled";
BA_ "VNSigAllNodes" SG_ 320 AdvFrntLghtSysEnbld 1;
BA_ "GenSigSendType" SG_ 320 FrFogLmpsAct 10;
BA_ "SignalType" SG_ 320 FrFogLmpsAct "BLN";
BA_ "SignalLongName" SG_ 320 FrFogLmpsAct "Front Fog Lamps Active";
BA_ "VNSigAllNodes" SG_ 320 FrFogLmpsAct 1;
BA_ "GenSigSendType" SG_ 320 AutLghtCtrl 10;
BA_ "SignalType" SG_ 320 AutLghtCtrl "BLN";
BA_ "SignalLongName" SG_ 320 AutLghtCtrl "Auto Light Control";
BA_ "VNSigAllNodes" SG_ 320 AutLghtCtrl 1;
BA_ "SignalType" SG_ 957 RdctHtrCStat "ENM";
BA_ "SignalLongName" SG_ 957 RdctHtrCStat "Reductant Heater C Status";
BA_ "VNSigAllNodes" SG_ 957 RdctHtrCStat 1;
BA_ "SignalType" SG_ 957 RdctHtrBStat "ENM";
BA_ "SignalLongName" SG_ 957 RdctHtrBStat "Reductant Heater B Status";
BA_ "VNSigAllNodes" SG_ 957 RdctHtrBStat 1;
BA_ "SignalType" SG_ 957 RdctHtrAStat "ENM";
BA_ "SignalLongName" SG_ 957 RdctHtrAStat "Reductant Heater A Status";
BA_ "VNSigAllNodes" SG_ 957 RdctHtrAStat 1;
BA_ "SignalType" SG_ 957 GPCMDS2_DTCStatus "ENM";
BA_ "PacketOrder" SG_ 957 GPCMDS2_DTCStatus 2;
BA_ "SignalLongName" SG_ 957 GPCMDS2_DTCStatus "Glow Plug Control Module Diagnostic Status 2 : Diagnostic Trouble Code Status";
BA_ "VNSigAllNodes" SG_ 957 GPCMDS2_DTCStatus 1;
BA_ "SignalType" SG_ 957 GPCMDS2_DTCIndex "UNM";
BA_ "PacketOrder" SG_ 957 GPCMDS2_DTCIndex 1;
BA_ "SignalLongName" SG_ 957 GPCMDS2_DTCIndex "Glow Plug Control Module Diagnostic Status 2 : Diagnostic Trouble Code Index";
BA_ "VNSigAllNodes" SG_ 957 GPCMDS2_DTCIndex 1;
BA_ "SignalType" SG_ 957 IntAirHtrPwrConsmp "UNM";
BA_ "SignalLongName" SG_ 957 IntAirHtrPwrConsmp "Intake Air Heater Power Consumption";
BA_ "VNSigAllNodes" SG_ 957 IntAirHtrPwrConsmp 1;
BA_ "SignalType" SG_ 957 IntAirHtrPwrConsmpV "ENM";
BA_ "SignalLongName" SG_ 957 IntAirHtrPwrConsmpV "Intake Air Heater Power Consumption Validity";
BA_ "VNSigAllNodes" SG_ 957 IntAirHtrPwrConsmpV 1;
BA_ "SignalType" SG_ 957 DslGlwPlgMdOvTmOD "BLN";
BA_ "SignalLongName" SG_ 957 DslGlwPlgMdOvTmOD "Glow Plug Control Module Over Temperature Outputs Disabled";
BA_ "VNSigAllNodes" SG_ 957 DslGlwPlgMdOvTmOD 1;
BA_ "SignalType" SG_ 957 IQAI_DataByte "UNM";
BA_ "PacketOrder" SG_ 957 IQAI_DataByte 4;
BA_ "SignalLongName" SG_ 957 IQAI_DataByte "Injector Quantity Adjustment Information : Data Byte";
BA_ "VNSigAllNodes" SG_ 957 IQAI_DataByte 1;
BA_ "SignalType" SG_ 957 IQAI_DataSeqNmbr "UNM";
BA_ "PacketOrder" SG_ 957 IQAI_DataSeqNmbr 3;
BA_ "SignalLongName" SG_ 957 IQAI_DataSeqNmbr "Injector Quantity Adjustment Information : Data Sequence Number";
BA_ "VNSigAllNodes" SG_ 957 IQAI_DataSeqNmbr 1;
BA_ "GenSigStartValue" SG_ 957 IQAI_InjIdInd 1;
BA_ "SignalType" SG_ 957 IQAI_InjIdInd "ENM";
BA_ "PacketOrder" SG_ 957 IQAI_InjIdInd 2;
BA_ "SignalLongName" SG_ 957 IQAI_InjIdInd "Injector Quantity Adjustment Information : Injector Identification Index";
BA_ "VNSigAllNodes" SG_ 957 IQAI_InjIdInd 1;
BA_ "SignalType" SG_ 957 IQAI_DataStat "ENM";
BA_ "PacketOrder" SG_ 957 IQAI_DataStat 1;
BA_ "SignalLongName" SG_ 957 IQAI_DataStat "Injector Quantity Adjustment Information : Data Status";
BA_ "VNSigAllNodes" SG_ 957 IQAI_DataStat 1;
BA_ "SignalType" SG_ 957 IntAirHtrTempSensVoltV "ENM";
BA_ "SignalLongName" SG_ 957 IntAirHtrTempSensVoltV "Intake Air Heater Temperature Sensor Voltage Validity";
BA_ "VNSigAllNodes" SG_ 957 IntAirHtrTempSensVoltV 1;
BA_ "SignalType" SG_ 957 IntAirHtrTempSensVolt "UNM";
BA_ "SignalLongName" SG_ 957 IntAirHtrTempSensVolt "Intake Air Heater Temperature Sensor Voltage";
BA_ "VNSigAllNodes" SG_ 957 IntAirHtrTempSensVolt 1;
BA_ "SignalType" SG_ 957 IntAirHtrSupVoltV "ENM";
BA_ "SignalLongName" SG_ 957 IntAirHtrSupVoltV "Intake Air Heater Supply Voltage Validity";
BA_ "VNSigAllNodes" SG_ 957 IntAirHtrSupVoltV 1;
BA_ "SignalType" SG_ 957 IntAirHtrSupVolt "UNM";
BA_ "SignalLongName" SG_ 957 IntAirHtrSupVolt "Intake Air Heater Supply Voltage";
BA_ "VNSigAllNodes" SG_ 957 IntAirHtrSupVolt 1;
BA_ "SignalType" SG_ 957 GPCMDS_DTCStatus "ENM";
BA_ "PacketOrder" SG_ 957 GPCMDS_DTCStatus 2;
BA_ "SignalLongName" SG_ 957 GPCMDS_DTCStatus "Glow Plug Control Module Diagnostic Status : Diagnostic Trouble Code Status";
BA_ "VNSigAllNodes" SG_ 957 GPCMDS_DTCStatus 1;
BA_ "SignalType" SG_ 957 GPCMDS_DTCIndex "UNM";
BA_ "PacketOrder" SG_ 957 GPCMDS_DTCIndex 1;
BA_ "SignalLongName" SG_ 957 GPCMDS_DTCIndex "Glow Plug Control Module Diagnostic Status : Diagnostic Trouble Code Index";
BA_ "VNSigAllNodes" SG_ 957 GPCMDS_DTCIndex 1;
BA_ "VNSigSLHSSharedDiagnostic" SG_ 1364 DgnInf_HS554 1;
BA_ "SignalType" SG_ 1364 DgnInf_HS554 "UNM";
BA_ "SignalLongName" SG_ 1364 DgnInf_HS554 "Diagnostic Information HS554";
BA_ "VNSigAllNodes" SG_ 1364 DgnInf_HS554 1;
BA_ "GenSigDeltaValue" SG_ 2041 PCUInfo_7F9 1;
BA_ "GenSigSendType" SG_ 2041 PCUInfo_7F9 12;
BA_ "SignalType" SG_ 2041 PCUInfo_7F9 "UNM";
BA_ "SignalLongName" SG_ 2041 PCUInfo_7F9 "Pyrotechnical Control Unit Information 7F9";
BA_ "VNSigAllNodes" SG_ 2041 PCUInfo_7F9 1;
BA_ "SignalType" SG_ 1904 DTCI_WrnIndRqdSt_770 "BLN";
BA_ "PacketOrder" SG_ 1904 DTCI_WrnIndRqdSt_770 12;
BA_ "SignalLongName" SG_ 1904 DTCI_WrnIndRqdSt_770 "Diagnostic Trouble Code Information Extended 770 : Warning Indicator Requested Status";
BA_ "VNSigAllNodes" SG_ 1904 DTCI_WrnIndRqdSt_770 1;
BA_ "SignalType" SG_ 1904 DTCIUnused7_770 "BLN";
BA_ "PacketOrder" SG_ 1904 DTCIUnused7_770 7;
BA_ "SignalLongName" SG_ 1904 DTCIUnused7_770 "Diagnostic Trouble Code Information Extended 770 : Unused 7";
BA_ "VNSigAllNodes" SG_ 1904 DTCIUnused7_770 1;
BA_ "SignalType" SG_ 1904 DTCIUnused6_770 "BLN";
BA_ "PacketOrder" SG_ 1904 DTCIUnused6_770 6;
BA_ "SignalLongName" SG_ 1904 DTCIUnused6_770 "Diagnostic Trouble Code Information Extended 770 : Unused 6";
BA_ "VNSigAllNodes" SG_ 1904 DTCIUnused6_770 1;
BA_ "SignalType" SG_ 1904 DTCIUnused5_770 "BLN";
BA_ "PacketOrder" SG_ 1904 DTCIUnused5_770 5;
BA_ "SignalLongName" SG_ 1904 DTCIUnused5_770 "Diagnostic Trouble Code Information Extended 770 : Unused 5";
BA_ "VNSigAllNodes" SG_ 1904 DTCIUnused5_770 1;
BA_ "SignalType" SG_ 1904 DTCIUnused4_770 "BLN";
BA_ "PacketOrder" SG_ 1904 DTCIUnused4_770 4;
BA_ "SignalLongName" SG_ 1904 DTCIUnused4_770 "Diagnostic Trouble Code Information Extended 770 : Unused 4";
BA_ "VNSigAllNodes" SG_ 1904 DTCIUnused4_770 1;
BA_ "SignalType" SG_ 1904 DTCIUnused3_770 "BLN";
BA_ "PacketOrder" SG_ 1904 DTCIUnused3_770 3;
BA_ "SignalLongName" SG_ 1904 DTCIUnused3_770 "Diagnostic Trouble Code Information Extended 770 : Unused 3";
BA_ "VNSigAllNodes" SG_ 1904 DTCIUnused3_770 1;
BA_ "SignalType" SG_ 1904 DTCIUnused2_770 "BLN";
BA_ "PacketOrder" SG_ 1904 DTCIUnused2_770 2;
BA_ "SignalLongName" SG_ 1904 DTCIUnused2_770 "Diagnostic Trouble Code Information Extended 770 : Unused 2";
BA_ "VNSigAllNodes" SG_ 1904 DTCIUnused2_770 1;
BA_ "SignalType" SG_ 1904 DTCIUnused1_770 "BLN";
BA_ "PacketOrder" SG_ 1904 DTCIUnused1_770 1;
BA_ "SignalLongName" SG_ 1904 DTCIUnused1_770 "Diagnostic Trouble Code Information Extended 770 : Unused 1";
BA_ "VNSigAllNodes" SG_ 1904 DTCIUnused1_770 1;
BA_ "SignalType" SG_ 1904 DTCI_TstNPsdPwrUpSt_770 "BLN";
BA_ "PacketOrder" SG_ 1904 DTCI_TstNPsdPwrUpSt_770 14;
BA_ "SignalLongName" SG_ 1904 DTCI_TstNPsdPwrUpSt_770 "Diagnostic Trouble Code Information Extended 770 : Test Not Passed Since Power Up Status";
BA_ "VNSigAllNodes" SG_ 1904 DTCI_TstNPsdPwrUpSt_770 1;
BA_ "SignalType" SG_ 1904 DTCI_TstNPsdCdClrdSt_770 "BLN";
BA_ "PacketOrder" SG_ 1904 DTCI_TstNPsdCdClrdSt_770 17;
BA_ "SignalLongName" SG_ 1904 DTCI_TstNPsdCdClrdSt_770 "Diagnostic Trouble Code Information Extended 770 : Test Not Passed Since Code Cleared Status";
BA_ "VNSigAllNodes" SG_ 1904 DTCI_TstNPsdCdClrdSt_770 1;
BA_ "SignalType" SG_ 1904 DTCI_TstFldPwrUpSt_770 "BLN";
BA_ "PacketOrder" SG_ 1904 DTCI_TstFldPwrUpSt_770 13;
BA_ "SignalLongName" SG_ 1904 DTCI_TstFldPwrUpSt_770 "Diagnostic Trouble Code Information Extended 770 : Test Failed Since Power Up Status";
BA_ "VNSigAllNodes" SG_ 1904 DTCI_TstFldPwrUpSt_770 1;
BA_ "SignalType" SG_ 1904 DTCI_TstFldCdClrdStat_770 "BLN";
BA_ "PacketOrder" SG_ 1904 DTCI_TstFldCdClrdStat_770 16;
BA_ "SignalLongName" SG_ 1904 DTCI_TstFldCdClrdStat_770 "Diagnostic Trouble Code Information Extended 770 : Test Failed Since Code Cleared Status";
BA_ "VNSigAllNodes" SG_ 1904 DTCI_TstFldCdClrdStat_770 1;
BA_ "SignalType" SG_ 1904 DTCI_HistStat_770 "BLN";
BA_ "PacketOrder" SG_ 1904 DTCI_HistStat_770 15;
BA_ "SignalLongName" SG_ 1904 DTCI_HistStat_770 "Diagnostic Trouble Code Information Extended 770 : History Status";
BA_ "VNSigAllNodes" SG_ 1904 DTCI_HistStat_770 1;
BA_ "SignalType" SG_ 1904 DTCI_DTCTriggered_770 "BLN";
BA_ "PacketOrder" SG_ 1904 DTCI_DTCTriggered_770 8;
BA_ "SignalLongName" SG_ 1904 DTCI_DTCTriggered_770 "Diagnostic Trouble Code Information Extended 770 : Diagnostic Trouble Code Triggered";
BA_ "VNSigAllNodes" SG_ 1904 DTCI_DTCTriggered_770 1;
BA_ "SignalType" SG_ 1904 DTCI_DTCSource_770 "UNM";
BA_ "PacketOrder" SG_ 1904 DTCI_DTCSource_770 9;
BA_ "SignalLongName" SG_ 1904 DTCI_DTCSource_770 "Diagnostic Trouble Code Information Extended 770 : Diagnostic Trouble Code Source";
BA_ "VNSigAllNodes" SG_ 1904 DTCI_DTCSource_770 1;
BA_ "SignalType" SG_ 1904 DTCI_DTCNumber_770 "UNM";
BA_ "PacketOrder" SG_ 1904 DTCI_DTCNumber_770 10;
BA_ "SignalLongName" SG_ 1904 DTCI_DTCNumber_770 "Diagnostic Trouble Code Information Extended 770 : Diagnostic Trouble Code Number";
BA_ "VNSigAllNodes" SG_ 1904 DTCI_DTCNumber_770 1;
BA_ "SignalType" SG_ 1904 DTCI_DTCFaultType_770 "ENM";
BA_ "PacketOrder" SG_ 1904 DTCI_DTCFaultType_770 20;
BA_ "SignalLongName" SG_ 1904 DTCI_DTCFaultType_770 "Diagnostic Trouble Code Information Extended 770 : Diagnostic Trouble Code Fault Type";
BA_ "VNSigAllNodes" SG_ 1904 DTCI_DTCFaultType_770 1;
BA_ "SignalType" SG_ 1904 DTCI_DTCFailType_770 "UNM";
BA_ "PacketOrder" SG_ 1904 DTCI_DTCFailType_770 11;
BA_ "SignalLongName" SG_ 1904 DTCI_DTCFailType_770 "Diagnostic Trouble Code Information Extended 770 : Diagnostic Trouble Code Failure Type";
BA_ "VNSigAllNodes" SG_ 1904 DTCI_DTCFailType_770 1;
BA_ "SignalType" SG_ 1904 DTCI_CurrentStatus_770 "BLN";
BA_ "PacketOrder" SG_ 1904 DTCI_CurrentStatus_770 18;
BA_ "SignalLongName" SG_ 1904 DTCI_CurrentStatus_770 "Diagnostic Trouble Code Information Extended 770 : Current Status";
BA_ "VNSigAllNodes" SG_ 1904 DTCI_CurrentStatus_770 1;
BA_ "SignalType" SG_ 1904 DTCI_CodeSupported_770 "BLN";
BA_ "PacketOrder" SG_ 1904 DTCI_CodeSupported_770 19;
BA_ "SignalLongName" SG_ 1904 DTCI_CodeSupported_770 "Diagnostic Trouble Code Information Extended 770 : Code Supported";
BA_ "VNSigAllNodes" SG_ 1904 DTCI_CodeSupported_770 1;
BA_ "SignalType" SG_ 1908 DTCI_DTCFaultType_774 "ENM";
BA_ "PacketOrder" SG_ 1908 DTCI_DTCFaultType_774 20;
BA_ "SignalLongName" SG_ 1908 DTCI_DTCFaultType_774 "Diagnostic Trouble Code Information Extended 774 : Diagnostic Trouble Code Fault Type";
BA_ "VNSigAllNodes" SG_ 1908 DTCI_DTCFaultType_774 1;
BA_ "SignalType" SG_ 1908 DTCI_CodeSupported_774 "BLN";
BA_ "PacketOrder" SG_ 1908 DTCI_CodeSupported_774 19;
BA_ "SignalLongName" SG_ 1908 DTCI_CodeSupported_774 "Diagnostic Trouble Code Information Extended 774 : Code Supported";
BA_ "VNSigAllNodes" SG_ 1908 DTCI_CodeSupported_774 1;
BA_ "SignalType" SG_ 1908 DTCI_CurrentStatus_774 "BLN";
BA_ "PacketOrder" SG_ 1908 DTCI_CurrentStatus_774 18;
BA_ "SignalLongName" SG_ 1908 DTCI_CurrentStatus_774 "Diagnostic Trouble Code Information Extended 774 : Current Status";
BA_ "VNSigAllNodes" SG_ 1908 DTCI_CurrentStatus_774 1;
BA_ "SignalType" SG_ 1908 DTCI_TstNPsdCdClrdSt_774 "BLN";
BA_ "PacketOrder" SG_ 1908 DTCI_TstNPsdCdClrdSt_774 17;
BA_ "SignalLongName" SG_ 1908 DTCI_TstNPsdCdClrdSt_774 "Diagnostic Trouble Code Information Extended 774 : Test Not Passed Since Code Cleared Status";
BA_ "VNSigAllNodes" SG_ 1908 DTCI_TstNPsdCdClrdSt_774 1;
BA_ "SignalType" SG_ 1908 DTCI_TstFldCdClrdStat_774 "BLN";
BA_ "PacketOrder" SG_ 1908 DTCI_TstFldCdClrdStat_774 16;
BA_ "SignalLongName" SG_ 1908 DTCI_TstFldCdClrdStat_774 "Diagnostic Trouble Code Information Extended 774 : Test Failed Since Code Cleared Status";
BA_ "VNSigAllNodes" SG_ 1908 DTCI_TstFldCdClrdStat_774 1;
BA_ "SignalType" SG_ 1908 DTCI_HistStat_774 "BLN";
BA_ "PacketOrder" SG_ 1908 DTCI_HistStat_774 15;
BA_ "SignalLongName" SG_ 1908 DTCI_HistStat_774 "Diagnostic Trouble Code Information Extended 774 : History Status";
BA_ "VNSigAllNodes" SG_ 1908 DTCI_HistStat_774 1;
BA_ "SignalType" SG_ 1908 DTCI_TstNPsdPwrUpSt_774 "BLN";
BA_ "PacketOrder" SG_ 1908 DTCI_TstNPsdPwrUpSt_774 14;
BA_ "SignalLongName" SG_ 1908 DTCI_TstNPsdPwrUpSt_774 "Diagnostic Trouble Code Information Extended 774 : Test Not Passed Since Power Up Status";
BA_ "VNSigAllNodes" SG_ 1908 DTCI_TstNPsdPwrUpSt_774 1;
BA_ "SignalType" SG_ 1908 DTCI_TstFldPwrUpSt_774 "BLN";
BA_ "PacketOrder" SG_ 1908 DTCI_TstFldPwrUpSt_774 13;
BA_ "SignalLongName" SG_ 1908 DTCI_TstFldPwrUpSt_774 "Diagnostic Trouble Code Information Extended 774 : Test Failed Since Power Up Status";
BA_ "VNSigAllNodes" SG_ 1908 DTCI_TstFldPwrUpSt_774 1;
BA_ "SignalType" SG_ 1908 DTCI_WrnIndRqdSt_774 "BLN";
BA_ "PacketOrder" SG_ 1908 DTCI_WrnIndRqdSt_774 12;
BA_ "SignalLongName" SG_ 1908 DTCI_WrnIndRqdSt_774 "Diagnostic Trouble Code Information Extended 774 : Warning Indicator Requested Status";
BA_ "VNSigAllNodes" SG_ 1908 DTCI_WrnIndRqdSt_774 1;
BA_ "SignalType" SG_ 1908 DTCI_DTCFailType_774 "UNM";
BA_ "PacketOrder" SG_ 1908 DTCI_DTCFailType_774 11;
BA_ "SignalLongName" SG_ 1908 DTCI_DTCFailType_774 "Diagnostic Trouble Code Information Extended 774 : Diagnostic Trouble Code Failure Type";
BA_ "VNSigAllNodes" SG_ 1908 DTCI_DTCFailType_774 1;
BA_ "SignalType" SG_ 1908 DTCI_DTCNumber_774 "UNM";
BA_ "PacketOrder" SG_ 1908 DTCI_DTCNumber_774 10;
BA_ "SignalLongName" SG_ 1908 DTCI_DTCNumber_774 "Diagnostic Trouble Code Information Extended 774 : Diagnostic Trouble Code Number";
BA_ "VNSigAllNodes" SG_ 1908 DTCI_DTCNumber_774 1;
BA_ "SignalType" SG_ 1908 DTCI_DTCSource_774 "UNM";
BA_ "PacketOrder" SG_ 1908 DTCI_DTCSource_774 9;
BA_ "SignalLongName" SG_ 1908 DTCI_DTCSource_774 "Diagnostic Trouble Code Information Extended 774 : Diagnostic Trouble Code Source";
BA_ "VNSigAllNodes" SG_ 1908 DTCI_DTCSource_774 1;
BA_ "SignalType" SG_ 1908 DTCI_DTCTriggered_774 "BLN";
BA_ "PacketOrder" SG_ 1908 DTCI_DTCTriggered_774 8;
BA_ "SignalLongName" SG_ 1908 DTCI_DTCTriggered_774 "Diagnostic Trouble Code Information Extended 774 : Diagnostic Trouble Code Triggered";
BA_ "VNSigAllNodes" SG_ 1908 DTCI_DTCTriggered_774 1;
BA_ "SignalType" SG_ 1908 DTCIUnused7_774 "BLN";
BA_ "PacketOrder" SG_ 1908 DTCIUnused7_774 7;
BA_ "SignalLongName" SG_ 1908 DTCIUnused7_774 "Diagnostic Trouble Code Information Extended 774 : Unused 7";
BA_ "VNSigAllNodes" SG_ 1908 DTCIUnused7_774 1;
BA_ "SignalType" SG_ 1908 DTCIUnused6_774 "BLN";
BA_ "PacketOrder" SG_ 1908 DTCIUnused6_774 6;
BA_ "SignalLongName" SG_ 1908 DTCIUnused6_774 "Diagnostic Trouble Code Information Extended 774 : Unused 6";
BA_ "VNSigAllNodes" SG_ 1908 DTCIUnused6_774 1;
BA_ "SignalType" SG_ 1908 DTCIUnused5_774 "BLN";
BA_ "PacketOrder" SG_ 1908 DTCIUnused5_774 5;
BA_ "SignalLongName" SG_ 1908 DTCIUnused5_774 "Diagnostic Trouble Code Information Extended 774 : Unused 5";
BA_ "VNSigAllNodes" SG_ 1908 DTCIUnused5_774 1;
BA_ "SignalType" SG_ 1908 DTCIUnused4_774 "BLN";
BA_ "PacketOrder" SG_ 1908 DTCIUnused4_774 4;
BA_ "SignalLongName" SG_ 1908 DTCIUnused4_774 "Diagnostic Trouble Code Information Extended 774 : Unused 4";
BA_ "VNSigAllNodes" SG_ 1908 DTCIUnused4_774 1;
BA_ "SignalType" SG_ 1908 DTCIUnused3_774 "BLN";
BA_ "PacketOrder" SG_ 1908 DTCIUnused3_774 3;
BA_ "SignalLongName" SG_ 1908 DTCIUnused3_774 "Diagnostic Trouble Code Information Extended 774 : Unused 3";
BA_ "VNSigAllNodes" SG_ 1908 DTCIUnused3_774 1;
BA_ "SignalType" SG_ 1908 DTCIUnused2_774 "BLN";
BA_ "PacketOrder" SG_ 1908 DTCIUnused2_774 2;
BA_ "SignalLongName" SG_ 1908 DTCIUnused2_774 "Diagnostic Trouble Code Information Extended 774 : Unused 2";
BA_ "VNSigAllNodes" SG_ 1908 DTCIUnused2_774 1;
BA_ "SignalType" SG_ 1908 DTCIUnused1_774 "BLN";
BA_ "PacketOrder" SG_ 1908 DTCIUnused1_774 1;
BA_ "SignalLongName" SG_ 1908 DTCIUnused1_774 "Diagnostic Trouble Code Information Extended 774 : Unused 1";
BA_ "VNSigAllNodes" SG_ 1908 DTCIUnused1_774 1;
BA_ "SignalType" SG_ 1909 DTCI_DTCFaultType_775 "ENM";
BA_ "PacketOrder" SG_ 1909 DTCI_DTCFaultType_775 20;
BA_ "SignalLongName" SG_ 1909 DTCI_DTCFaultType_775 "Diagnostic Trouble Code Information Extended 775 : Diagnostic Trouble Code Fault Type";
BA_ "VNSigAllNodes" SG_ 1909 DTCI_DTCFaultType_775 1;
BA_ "SignalType" SG_ 1909 DTCI_CodeSupported_775 "BLN";
BA_ "PacketOrder" SG_ 1909 DTCI_CodeSupported_775 19;
BA_ "SignalLongName" SG_ 1909 DTCI_CodeSupported_775 "Diagnostic Trouble Code Information Extended 775 : Code Supported";
BA_ "VNSigAllNodes" SG_ 1909 DTCI_CodeSupported_775 1;
BA_ "SignalType" SG_ 1909 DTCI_CurrentStatus_775 "BLN";
BA_ "PacketOrder" SG_ 1909 DTCI_CurrentStatus_775 18;
BA_ "SignalLongName" SG_ 1909 DTCI_CurrentStatus_775 "Diagnostic Trouble Code Information Extended 775 : Current Status";
BA_ "VNSigAllNodes" SG_ 1909 DTCI_CurrentStatus_775 1;
BA_ "SignalType" SG_ 1909 DTCI_TstNPsdCdClrdSt_775 "BLN";
BA_ "PacketOrder" SG_ 1909 DTCI_TstNPsdCdClrdSt_775 17;
BA_ "SignalLongName" SG_ 1909 DTCI_TstNPsdCdClrdSt_775 "Diagnostic Trouble Code Information Extended 775 : Test Not Passed Since Code Cleared Status";
BA_ "VNSigAllNodes" SG_ 1909 DTCI_TstNPsdCdClrdSt_775 1;
BA_ "SignalType" SG_ 1909 DTCI_TstFldCdClrdStat_775 "BLN";
BA_ "PacketOrder" SG_ 1909 DTCI_TstFldCdClrdStat_775 16;
BA_ "SignalLongName" SG_ 1909 DTCI_TstFldCdClrdStat_775 "Diagnostic Trouble Code Information Extended 775 : Test Failed Since Code Cleared Status";
BA_ "VNSigAllNodes" SG_ 1909 DTCI_TstFldCdClrdStat_775 1;
BA_ "SignalType" SG_ 1909 DTCI_HistStat_775 "BLN";
BA_ "PacketOrder" SG_ 1909 DTCI_HistStat_775 15;
BA_ "SignalLongName" SG_ 1909 DTCI_HistStat_775 "Diagnostic Trouble Code Information Extended 775 : History Status";
BA_ "VNSigAllNodes" SG_ 1909 DTCI_HistStat_775 1;
BA_ "SignalType" SG_ 1909 DTCI_TstNPsdPwrUpSt_775 "BLN";
BA_ "PacketOrder" SG_ 1909 DTCI_TstNPsdPwrUpSt_775 14;
BA_ "SignalLongName" SG_ 1909 DTCI_TstNPsdPwrUpSt_775 "Diagnostic Trouble Code Information Extended 775 : Test Not Passed Since Power Up Status";
BA_ "VNSigAllNodes" SG_ 1909 DTCI_TstNPsdPwrUpSt_775 1;
BA_ "SignalType" SG_ 1909 DTCI_TstFldPwrUpSt_775 "BLN";
BA_ "PacketOrder" SG_ 1909 DTCI_TstFldPwrUpSt_775 13;
BA_ "SignalLongName" SG_ 1909 DTCI_TstFldPwrUpSt_775 "Diagnostic Trouble Code Information Extended 775 : Test Failed Since Power Up Status";
BA_ "VNSigAllNodes" SG_ 1909 DTCI_TstFldPwrUpSt_775 1;
BA_ "SignalType" SG_ 1909 DTCI_WrnIndRqdSt_775 "BLN";
BA_ "PacketOrder" SG_ 1909 DTCI_WrnIndRqdSt_775 12;
BA_ "SignalLongName" SG_ 1909 DTCI_WrnIndRqdSt_775 "Diagnostic Trouble Code Information Extended 775 : Warning Indicator Requested Status";
BA_ "VNSigAllNodes" SG_ 1909 DTCI_WrnIndRqdSt_775 1;
BA_ "SignalType" SG_ 1909 DTCI_DTCFailType_775 "UNM";
BA_ "PacketOrder" SG_ 1909 DTCI_DTCFailType_775 11;
BA_ "SignalLongName" SG_ 1909 DTCI_DTCFailType_775 "Diagnostic Trouble Code Information Extended 775 : Diagnostic Trouble Code Failure Type";
BA_ "VNSigAllNodes" SG_ 1909 DTCI_DTCFailType_775 1;
BA_ "SignalType" SG_ 1909 DTCI_DTCNumber_775 "UNM";
BA_ "PacketOrder" SG_ 1909 DTCI_DTCNumber_775 10;
BA_ "SignalLongName" SG_ 1909 DTCI_DTCNumber_775 "Diagnostic Trouble Code Information Extended 775 : Diagnostic Trouble Code Number";
BA_ "VNSigAllNodes" SG_ 1909 DTCI_DTCNumber_775 1;
BA_ "SignalType" SG_ 1909 DTCI_DTCSource_775 "UNM";
BA_ "PacketOrder" SG_ 1909 DTCI_DTCSource_775 9;
BA_ "SignalLongName" SG_ 1909 DTCI_DTCSource_775 "Diagnostic Trouble Code Information Extended 775 : Diagnostic Trouble Code Source";
BA_ "VNSigAllNodes" SG_ 1909 DTCI_DTCSource_775 1;
BA_ "SignalType" SG_ 1909 DTCI_DTCTriggered_775 "BLN";
BA_ "PacketOrder" SG_ 1909 DTCI_DTCTriggered_775 8;
BA_ "SignalLongName" SG_ 1909 DTCI_DTCTriggered_775 "Diagnostic Trouble Code Information Extended 775 : Diagnostic Trouble Code Triggered";
BA_ "VNSigAllNodes" SG_ 1909 DTCI_DTCTriggered_775 1;
BA_ "SignalType" SG_ 1909 DTCIUnused7_775 "BLN";
BA_ "PacketOrder" SG_ 1909 DTCIUnused7_775 7;
BA_ "SignalLongName" SG_ 1909 DTCIUnused7_775 "Diagnostic Trouble Code Information Extended 775 : Unused 7";
BA_ "VNSigAllNodes" SG_ 1909 DTCIUnused7_775 1;
BA_ "SignalType" SG_ 1909 DTCIUnused6_775 "BLN";
BA_ "PacketOrder" SG_ 1909 DTCIUnused6_775 6;
BA_ "SignalLongName" SG_ 1909 DTCIUnused6_775 "Diagnostic Trouble Code Information Extended 775 : Unused 6";
BA_ "VNSigAllNodes" SG_ 1909 DTCIUnused6_775 1;
BA_ "SignalType" SG_ 1909 DTCIUnused5_775 "BLN";
BA_ "PacketOrder" SG_ 1909 DTCIUnused5_775 5;
BA_ "SignalLongName" SG_ 1909 DTCIUnused5_775 "Diagnostic Trouble Code Information Extended 775 : Unused 5";
BA_ "VNSigAllNodes" SG_ 1909 DTCIUnused5_775 1;
BA_ "SignalType" SG_ 1909 DTCIUnused4_775 "BLN";
BA_ "PacketOrder" SG_ 1909 DTCIUnused4_775 4;
BA_ "SignalLongName" SG_ 1909 DTCIUnused4_775 "Diagnostic Trouble Code Information Extended 775 : Unused 4";
BA_ "VNSigAllNodes" SG_ 1909 DTCIUnused4_775 1;
BA_ "SignalType" SG_ 1909 DTCIUnused3_775 "BLN";
BA_ "PacketOrder" SG_ 1909 DTCIUnused3_775 3;
BA_ "SignalLongName" SG_ 1909 DTCIUnused3_775 "Diagnostic Trouble Code Information Extended 775 : Unused 3";
BA_ "VNSigAllNodes" SG_ 1909 DTCIUnused3_775 1;
BA_ "SignalType" SG_ 1909 DTCIUnused2_775 "BLN";
BA_ "PacketOrder" SG_ 1909 DTCIUnused2_775 2;
BA_ "SignalLongName" SG_ 1909 DTCIUnused2_775 "Diagnostic Trouble Code Information Extended 775 : Unused 2";
BA_ "VNSigAllNodes" SG_ 1909 DTCIUnused2_775 1;
BA_ "SignalType" SG_ 1909 DTCIUnused1_775 "BLN";
BA_ "PacketOrder" SG_ 1909 DTCIUnused1_775 1;
BA_ "SignalLongName" SG_ 1909 DTCIUnused1_775 "Diagnostic Trouble Code Information Extended 775 : Unused 1";
BA_ "VNSigAllNodes" SG_ 1909 DTCIUnused1_775 1;
BA_ "SignalType" SG_ 1910 DTCI_DTCFaultType_776 "ENM";
BA_ "PacketOrder" SG_ 1910 DTCI_DTCFaultType_776 20;
BA_ "SignalLongName" SG_ 1910 DTCI_DTCFaultType_776 "Diagnostic Trouble Code Information Extended 776 : Diagnostic Trouble Code Fault Type";
BA_ "VNSigAllNodes" SG_ 1910 DTCI_DTCFaultType_776 1;
BA_ "SignalType" SG_ 1910 DTCI_CodeSupported_776 "BLN";
BA_ "PacketOrder" SG_ 1910 DTCI_CodeSupported_776 19;
BA_ "SignalLongName" SG_ 1910 DTCI_CodeSupported_776 "Diagnostic Trouble Code Information Extended 776 : Code Supported";
BA_ "VNSigAllNodes" SG_ 1910 DTCI_CodeSupported_776 1;
BA_ "SignalType" SG_ 1910 DTCI_CurrentStatus_776 "BLN";
BA_ "PacketOrder" SG_ 1910 DTCI_CurrentStatus_776 18;
BA_ "SignalLongName" SG_ 1910 DTCI_CurrentStatus_776 "Diagnostic Trouble Code Information Extended 776 : Current Status";
BA_ "VNSigAllNodes" SG_ 1910 DTCI_CurrentStatus_776 1;
BA_ "SignalType" SG_ 1910 DTCI_TstNPsdCdClrdSt_776 "BLN";
BA_ "PacketOrder" SG_ 1910 DTCI_TstNPsdCdClrdSt_776 17;
BA_ "SignalLongName" SG_ 1910 DTCI_TstNPsdCdClrdSt_776 "Diagnostic Trouble Code Information Extended 776 : Test Not Passed Since Code Cleared Status";
BA_ "VNSigAllNodes" SG_ 1910 DTCI_TstNPsdCdClrdSt_776 1;
BA_ "SignalType" SG_ 1910 DTCI_TstFldCdClrdStat_776 "BLN";
BA_ "PacketOrder" SG_ 1910 DTCI_TstFldCdClrdStat_776 16;
BA_ "SignalLongName" SG_ 1910 DTCI_TstFldCdClrdStat_776 "Diagnostic Trouble Code Information Extended 776 : Test Failed Since Code Cleared Status";
BA_ "VNSigAllNodes" SG_ 1910 DTCI_TstFldCdClrdStat_776 1;
BA_ "SignalType" SG_ 1910 DTCI_HistStat_776 "BLN";
BA_ "PacketOrder" SG_ 1910 DTCI_HistStat_776 15;
BA_ "SignalLongName" SG_ 1910 DTCI_HistStat_776 "Diagnostic Trouble Code Information Extended 776 : History Status";
BA_ "VNSigAllNodes" SG_ 1910 DTCI_HistStat_776 1;
BA_ "SignalType" SG_ 1910 DTCI_TstNPsdPwrUpSt_776 "BLN";
BA_ "PacketOrder" SG_ 1910 DTCI_TstNPsdPwrUpSt_776 14;
BA_ "SignalLongName" SG_ 1910 DTCI_TstNPsdPwrUpSt_776 "Diagnostic Trouble Code Information Extended 776 : Test Not Passed Since Power Up Status";
BA_ "VNSigAllNodes" SG_ 1910 DTCI_TstNPsdPwrUpSt_776 1;
BA_ "SignalType" SG_ 1910 DTCI_TstFldPwrUpSt_776 "BLN";
BA_ "PacketOrder" SG_ 1910 DTCI_TstFldPwrUpSt_776 13;
BA_ "SignalLongName" SG_ 1910 DTCI_TstFldPwrUpSt_776 "Diagnostic Trouble Code Information Extended 776 : Test Failed Since Power Up Status";
BA_ "VNSigAllNodes" SG_ 1910 DTCI_TstFldPwrUpSt_776 1;
BA_ "SignalType" SG_ 1910 DTCI_WrnIndRqdSt_776 "BLN";
BA_ "PacketOrder" SG_ 1910 DTCI_WrnIndRqdSt_776 12;
BA_ "SignalLongName" SG_ 1910 DTCI_WrnIndRqdSt_776 "Diagnostic Trouble Code Information Extended 776 : Warning Indicator Requested Status";
BA_ "VNSigAllNodes" SG_ 1910 DTCI_WrnIndRqdSt_776 1;
BA_ "SignalType" SG_ 1910 DTCI_DTCFailType_776 "UNM";
BA_ "PacketOrder" SG_ 1910 DTCI_DTCFailType_776 11;
BA_ "SignalLongName" SG_ 1910 DTCI_DTCFailType_776 "Diagnostic Trouble Code Information Extended 776 : Diagnostic Trouble Code Failure Type";
BA_ "VNSigAllNodes" SG_ 1910 DTCI_DTCFailType_776 1;
BA_ "SignalType" SG_ 1910 DTCI_DTCNumber_776 "UNM";
BA_ "PacketOrder" SG_ 1910 DTCI_DTCNumber_776 10;
BA_ "SignalLongName" SG_ 1910 DTCI_DTCNumber_776 "Diagnostic Trouble Code Information Extended 776 : Diagnostic Trouble Code Number";
BA_ "VNSigAllNodes" SG_ 1910 DTCI_DTCNumber_776 1;
BA_ "SignalType" SG_ 1910 DTCI_DTCSource_776 "UNM";
BA_ "PacketOrder" SG_ 1910 DTCI_DTCSource_776 9;
BA_ "SignalLongName" SG_ 1910 DTCI_DTCSource_776 "Diagnostic Trouble Code Information Extended 776 : Diagnostic Trouble Code Source";
BA_ "VNSigAllNodes" SG_ 1910 DTCI_DTCSource_776 1;
BA_ "SignalType" SG_ 1910 DTCI_DTCTriggered_776 "BLN";
BA_ "PacketOrder" SG_ 1910 DTCI_DTCTriggered_776 8;
BA_ "SignalLongName" SG_ 1910 DTCI_DTCTriggered_776 "Diagnostic Trouble Code Information Extended 776 : Diagnostic Trouble Code Triggered";
BA_ "VNSigAllNodes" SG_ 1910 DTCI_DTCTriggered_776 1;
BA_ "SignalType" SG_ 1910 DTCIUnused7_776 "BLN";
BA_ "PacketOrder" SG_ 1910 DTCIUnused7_776 7;
BA_ "SignalLongName" SG_ 1910 DTCIUnused7_776 "Diagnostic Trouble Code Information Extended 776 : Unused 7";
BA_ "VNSigAllNodes" SG_ 1910 DTCIUnused7_776 1;
BA_ "SignalType" SG_ 1910 DTCIUnused6_776 "BLN";
BA_ "PacketOrder" SG_ 1910 DTCIUnused6_776 6;
BA_ "SignalLongName" SG_ 1910 DTCIUnused6_776 "Diagnostic Trouble Code Information Extended 776 : Unused 6";
BA_ "VNSigAllNodes" SG_ 1910 DTCIUnused6_776 1;
BA_ "SignalType" SG_ 1910 DTCIUnused5_776 "BLN";
BA_ "PacketOrder" SG_ 1910 DTCIUnused5_776 5;
BA_ "SignalLongName" SG_ 1910 DTCIUnused5_776 "Diagnostic Trouble Code Information Extended 776 : Unused 5";
BA_ "VNSigAllNodes" SG_ 1910 DTCIUnused5_776 1;
BA_ "SignalType" SG_ 1910 DTCIUnused4_776 "BLN";
BA_ "PacketOrder" SG_ 1910 DTCIUnused4_776 4;
BA_ "SignalLongName" SG_ 1910 DTCIUnused4_776 "Diagnostic Trouble Code Information Extended 776 : Unused 4";
BA_ "VNSigAllNodes" SG_ 1910 DTCIUnused4_776 1;
BA_ "SignalType" SG_ 1910 DTCIUnused3_776 "BLN";
BA_ "PacketOrder" SG_ 1910 DTCIUnused3_776 3;
BA_ "SignalLongName" SG_ 1910 DTCIUnused3_776 "Diagnostic Trouble Code Information Extended 776 : Unused 3";
BA_ "VNSigAllNodes" SG_ 1910 DTCIUnused3_776 1;
BA_ "SignalType" SG_ 1910 DTCIUnused2_776 "BLN";
BA_ "PacketOrder" SG_ 1910 DTCIUnused2_776 2;
BA_ "SignalLongName" SG_ 1910 DTCIUnused2_776 "Diagnostic Trouble Code Information Extended 776 : Unused 2";
BA_ "VNSigAllNodes" SG_ 1910 DTCIUnused2_776 1;
BA_ "SignalType" SG_ 1910 DTCIUnused1_776 "BLN";
BA_ "PacketOrder" SG_ 1910 DTCIUnused1_776 1;
BA_ "SignalLongName" SG_ 1910 DTCIUnused1_776 "Diagnostic Trouble Code Information Extended 776 : Unused 1";
BA_ "VNSigAllNodes" SG_ 1910 DTCIUnused1_776 1;
BA_ "SignalType" SG_ 1912 DTCI_DTCFaultType_778 "ENM";
BA_ "PacketOrder" SG_ 1912 DTCI_DTCFaultType_778 20;
BA_ "SignalLongName" SG_ 1912 DTCI_DTCFaultType_778 "Diagnostic Trouble Code Information Extended 778 : Diagnostic Trouble Code Fault Type";
BA_ "VNSigAllNodes" SG_ 1912 DTCI_DTCFaultType_778 1;
BA_ "SignalType" SG_ 1912 DTCI_CodeSupported_778 "BLN";
BA_ "PacketOrder" SG_ 1912 DTCI_CodeSupported_778 19;
BA_ "SignalLongName" SG_ 1912 DTCI_CodeSupported_778 "Diagnostic Trouble Code Information Extended 778 : Code Supported";
BA_ "VNSigAllNodes" SG_ 1912 DTCI_CodeSupported_778 1;
BA_ "SignalType" SG_ 1912 DTCI_CurrentStatus_778 "BLN";
BA_ "PacketOrder" SG_ 1912 DTCI_CurrentStatus_778 18;
BA_ "SignalLongName" SG_ 1912 DTCI_CurrentStatus_778 "Diagnostic Trouble Code Information Extended 778 : Current Status";
BA_ "VNSigAllNodes" SG_ 1912 DTCI_CurrentStatus_778 1;
BA_ "SignalType" SG_ 1912 DTCI_TstNPsdCdClrdSt_778 "BLN";
BA_ "PacketOrder" SG_ 1912 DTCI_TstNPsdCdClrdSt_778 17;
BA_ "SignalLongName" SG_ 1912 DTCI_TstNPsdCdClrdSt_778 "Diagnostic Trouble Code Information Extended 778 : Test Not Passed Since Code Cleared Status";
BA_ "VNSigAllNodes" SG_ 1912 DTCI_TstNPsdCdClrdSt_778 1;
BA_ "SignalType" SG_ 1912 DTCI_TstFldCdClrdStat_778 "BLN";
BA_ "PacketOrder" SG_ 1912 DTCI_TstFldCdClrdStat_778 16;
BA_ "SignalLongName" SG_ 1912 DTCI_TstFldCdClrdStat_778 "Diagnostic Trouble Code Information Extended 778 : Test Failed Since Code Cleared Status";
BA_ "VNSigAllNodes" SG_ 1912 DTCI_TstFldCdClrdStat_778 1;
BA_ "SignalType" SG_ 1912 DTCI_HistStat_778 "BLN";
BA_ "PacketOrder" SG_ 1912 DTCI_HistStat_778 15;
BA_ "SignalLongName" SG_ 1912 DTCI_HistStat_778 "Diagnostic Trouble Code Information Extended 778 : History Status";
BA_ "VNSigAllNodes" SG_ 1912 DTCI_HistStat_778 1;
BA_ "SignalType" SG_ 1912 DTCI_TstNPsdPwrUpSt_778 "BLN";
BA_ "PacketOrder" SG_ 1912 DTCI_TstNPsdPwrUpSt_778 14;
BA_ "SignalLongName" SG_ 1912 DTCI_TstNPsdPwrUpSt_778 "Diagnostic Trouble Code Information Extended 778 : Test Not Passed Since Power Up Status";
BA_ "VNSigAllNodes" SG_ 1912 DTCI_TstNPsdPwrUpSt_778 1;
BA_ "SignalType" SG_ 1912 DTCI_TstFldPwrUpSt_778 "BLN";
BA_ "PacketOrder" SG_ 1912 DTCI_TstFldPwrUpSt_778 13;
BA_ "SignalLongName" SG_ 1912 DTCI_TstFldPwrUpSt_778 "Diagnostic Trouble Code Information Extended 778 : Test Failed Since Power Up Status";
BA_ "VNSigAllNodes" SG_ 1912 DTCI_TstFldPwrUpSt_778 1;
BA_ "SignalType" SG_ 1912 DTCI_WrnIndRqdSt_778 "BLN";
BA_ "PacketOrder" SG_ 1912 DTCI_WrnIndRqdSt_778 12;
BA_ "SignalLongName" SG_ 1912 DTCI_WrnIndRqdSt_778 "Diagnostic Trouble Code Information Extended 778 : Warning Indicator Requested Status";
BA_ "VNSigAllNodes" SG_ 1912 DTCI_WrnIndRqdSt_778 1;
BA_ "SignalType" SG_ 1912 DTCI_DTCFailType_778 "UNM";
BA_ "PacketOrder" SG_ 1912 DTCI_DTCFailType_778 11;
BA_ "SignalLongName" SG_ 1912 DTCI_DTCFailType_778 "Diagnostic Trouble Code Information Extended 778 : Diagnostic Trouble Code Failure Type";
BA_ "VNSigAllNodes" SG_ 1912 DTCI_DTCFailType_778 1;
BA_ "SignalType" SG_ 1912 DTCI_DTCNumber_778 "UNM";
BA_ "PacketOrder" SG_ 1912 DTCI_DTCNumber_778 10;
BA_ "SignalLongName" SG_ 1912 DTCI_DTCNumber_778 "Diagnostic Trouble Code Information Extended 778 : Diagnostic Trouble Code Number";
BA_ "VNSigAllNodes" SG_ 1912 DTCI_DTCNumber_778 1;
BA_ "SignalType" SG_ 1912 DTCI_DTCSource_778 "UNM";
BA_ "PacketOrder" SG_ 1912 DTCI_DTCSource_778 9;
BA_ "SignalLongName" SG_ 1912 DTCI_DTCSource_778 "Diagnostic Trouble Code Information Extended 778 : Diagnostic Trouble Code Source";
BA_ "VNSigAllNodes" SG_ 1912 DTCI_DTCSource_778 1;
BA_ "SignalType" SG_ 1912 DTCI_DTCTriggered_778 "BLN";
BA_ "PacketOrder" SG_ 1912 DTCI_DTCTriggered_778 8;
BA_ "SignalLongName" SG_ 1912 DTCI_DTCTriggered_778 "Diagnostic Trouble Code Information Extended 778 : Diagnostic Trouble Code Triggered";
BA_ "VNSigAllNodes" SG_ 1912 DTCI_DTCTriggered_778 1;
BA_ "SignalType" SG_ 1912 DTCIUnused7_778 "BLN";
BA_ "PacketOrder" SG_ 1912 DTCIUnused7_778 7;
BA_ "SignalLongName" SG_ 1912 DTCIUnused7_778 "Diagnostic Trouble Code Information Extended 778 : Unused 7";
BA_ "VNSigAllNodes" SG_ 1912 DTCIUnused7_778 1;
BA_ "SignalType" SG_ 1912 DTCIUnused6_778 "BLN";
BA_ "PacketOrder" SG_ 1912 DTCIUnused6_778 6;
BA_ "SignalLongName" SG_ 1912 DTCIUnused6_778 "Diagnostic Trouble Code Information Extended 778 : Unused 6";
BA_ "VNSigAllNodes" SG_ 1912 DTCIUnused6_778 1;
BA_ "SignalType" SG_ 1912 DTCIUnused5_778 "BLN";
BA_ "PacketOrder" SG_ 1912 DTCIUnused5_778 5;
BA_ "SignalLongName" SG_ 1912 DTCIUnused5_778 "Diagnostic Trouble Code Information Extended 778 : Unused 5";
BA_ "VNSigAllNodes" SG_ 1912 DTCIUnused5_778 1;
BA_ "SignalType" SG_ 1912 DTCIUnused4_778 "BLN";
BA_ "PacketOrder" SG_ 1912 DTCIUnused4_778 4;
BA_ "SignalLongName" SG_ 1912 DTCIUnused4_778 "Diagnostic Trouble Code Information Extended 778 : Unused 4";
BA_ "VNSigAllNodes" SG_ 1912 DTCIUnused4_778 1;
BA_ "SignalType" SG_ 1912 DTCIUnused3_778 "BLN";
BA_ "PacketOrder" SG_ 1912 DTCIUnused3_778 3;
BA_ "SignalLongName" SG_ 1912 DTCIUnused3_778 "Diagnostic Trouble Code Information Extended 778 : Unused 3";
BA_ "VNSigAllNodes" SG_ 1912 DTCIUnused3_778 1;
BA_ "SignalType" SG_ 1912 DTCIUnused2_778 "BLN";
BA_ "PacketOrder" SG_ 1912 DTCIUnused2_778 2;
BA_ "SignalLongName" SG_ 1912 DTCIUnused2_778 "Diagnostic Trouble Code Information Extended 778 : Unused 2";
BA_ "VNSigAllNodes" SG_ 1912 DTCIUnused2_778 1;
BA_ "SignalType" SG_ 1912 DTCIUnused1_778 "BLN";
BA_ "PacketOrder" SG_ 1912 DTCIUnused1_778 1;
BA_ "SignalLongName" SG_ 1912 DTCIUnused1_778 "Diagnostic Trouble Code Information Extended 778 : Unused 1";
BA_ "VNSigAllNodes" SG_ 1912 DTCIUnused1_778 1;
BA_ "SignalType" SG_ 1913 DTCI_DTCFaultType_779 "ENM";
BA_ "PacketOrder" SG_ 1913 DTCI_DTCFaultType_779 20;
BA_ "SignalLongName" SG_ 1913 DTCI_DTCFaultType_779 "Diagnostic Trouble Code Information Extended 779 : Diagnostic Trouble Code Fault Type";
BA_ "VNSigAllNodes" SG_ 1913 DTCI_DTCFaultType_779 1;
BA_ "SignalType" SG_ 1913 DTCI_CodeSupported_779 "BLN";
BA_ "PacketOrder" SG_ 1913 DTCI_CodeSupported_779 19;
BA_ "SignalLongName" SG_ 1913 DTCI_CodeSupported_779 "Diagnostic Trouble Code Information Extended 779 : Code Supported";
BA_ "VNSigAllNodes" SG_ 1913 DTCI_CodeSupported_779 1;
BA_ "SignalType" SG_ 1913 DTCI_CurrentStatus_779 "BLN";
BA_ "PacketOrder" SG_ 1913 DTCI_CurrentStatus_779 18;
BA_ "SignalLongName" SG_ 1913 DTCI_CurrentStatus_779 "Diagnostic Trouble Code Information Extended 779 : Current Status";
BA_ "VNSigAllNodes" SG_ 1913 DTCI_CurrentStatus_779 1;
BA_ "SignalType" SG_ 1913 DTCI_TstNPsdCdClrdSt_779 "BLN";
BA_ "PacketOrder" SG_ 1913 DTCI_TstNPsdCdClrdSt_779 17;
BA_ "SignalLongName" SG_ 1913 DTCI_TstNPsdCdClrdSt_779 "Diagnostic Trouble Code Information Extended 779 : Test Not Passed Since Code Cleared Status";
BA_ "VNSigAllNodes" SG_ 1913 DTCI_TstNPsdCdClrdSt_779 1;
BA_ "SignalType" SG_ 1913 DTCI_TstFldCdClrdStat_779 "BLN";
BA_ "PacketOrder" SG_ 1913 DTCI_TstFldCdClrdStat_779 16;
BA_ "SignalLongName" SG_ 1913 DTCI_TstFldCdClrdStat_779 "Diagnostic Trouble Code Information Extended 779 : Test Failed Since Code Cleared Status";
BA_ "VNSigAllNodes" SG_ 1913 DTCI_TstFldCdClrdStat_779 1;
BA_ "SignalType" SG_ 1913 DTCI_HistStat_779 "BLN";
BA_ "PacketOrder" SG_ 1913 DTCI_HistStat_779 15;
BA_ "SignalLongName" SG_ 1913 DTCI_HistStat_779 "Diagnostic Trouble Code Information Extended 779 : History Status";
BA_ "VNSigAllNodes" SG_ 1913 DTCI_HistStat_779 1;
BA_ "SignalType" SG_ 1913 DTCI_TstNPsdPwrUpSt_779 "BLN";
BA_ "PacketOrder" SG_ 1913 DTCI_TstNPsdPwrUpSt_779 14;
BA_ "SignalLongName" SG_ 1913 DTCI_TstNPsdPwrUpSt_779 "Diagnostic Trouble Code Information Extended 779 : Test Not Passed Since Power Up Status";
BA_ "VNSigAllNodes" SG_ 1913 DTCI_TstNPsdPwrUpSt_779 1;
BA_ "SignalType" SG_ 1913 DTCI_TstFldPwrUpSt_779 "BLN";
BA_ "PacketOrder" SG_ 1913 DTCI_TstFldPwrUpSt_779 13;
BA_ "SignalLongName" SG_ 1913 DTCI_TstFldPwrUpSt_779 "Diagnostic Trouble Code Information Extended 779 : Test Failed Since Power Up Status";
BA_ "VNSigAllNodes" SG_ 1913 DTCI_TstFldPwrUpSt_779 1;
BA_ "SignalType" SG_ 1913 DTCI_WrnIndRqdSt_779 "BLN";
BA_ "PacketOrder" SG_ 1913 DTCI_WrnIndRqdSt_779 12;
BA_ "SignalLongName" SG_ 1913 DTCI_WrnIndRqdSt_779 "Diagnostic Trouble Code Information Extended 779 : Warning Indicator Requested Status";
BA_ "VNSigAllNodes" SG_ 1913 DTCI_WrnIndRqdSt_779 1;
BA_ "SignalType" SG_ 1913 DTCI_DTCFailType_779 "UNM";
BA_ "PacketOrder" SG_ 1913 DTCI_DTCFailType_779 11;
BA_ "SignalLongName" SG_ 1913 DTCI_DTCFailType_779 "Diagnostic Trouble Code Information Extended 779 : Diagnostic Trouble Code Failure Type";
BA_ "VNSigAllNodes" SG_ 1913 DTCI_DTCFailType_779 1;
BA_ "SignalType" SG_ 1913 DTCI_DTCNumber_779 "UNM";
BA_ "PacketOrder" SG_ 1913 DTCI_DTCNumber_779 10;
BA_ "SignalLongName" SG_ 1913 DTCI_DTCNumber_779 "Diagnostic Trouble Code Information Extended 779 : Diagnostic Trouble Code Number";
BA_ "VNSigAllNodes" SG_ 1913 DTCI_DTCNumber_779 1;
BA_ "SignalType" SG_ 1913 DTCI_DTCSource_779 "UNM";
BA_ "PacketOrder" SG_ 1913 DTCI_DTCSource_779 9;
BA_ "SignalLongName" SG_ 1913 DTCI_DTCSource_779 "Diagnostic Trouble Code Information Extended 779 : Diagnostic Trouble Code Source";
BA_ "VNSigAllNodes" SG_ 1913 DTCI_DTCSource_779 1;
BA_ "SignalType" SG_ 1913 DTCI_DTCTriggered_779 "BLN";
BA_ "PacketOrder" SG_ 1913 DTCI_DTCTriggered_779 8;
BA_ "SignalLongName" SG_ 1913 DTCI_DTCTriggered_779 "Diagnostic Trouble Code Information Extended 779 : Diagnostic Trouble Code Triggered";
BA_ "VNSigAllNodes" SG_ 1913 DTCI_DTCTriggered_779 1;
BA_ "SignalType" SG_ 1913 DTCIUnused7_779 "BLN";
BA_ "PacketOrder" SG_ 1913 DTCIUnused7_779 7;
BA_ "SignalLongName" SG_ 1913 DTCIUnused7_779 "Diagnostic Trouble Code Information Extended 779 : Unused 7";
BA_ "VNSigAllNodes" SG_ 1913 DTCIUnused7_779 1;
BA_ "SignalType" SG_ 1913 DTCIUnused6_779 "BLN";
BA_ "PacketOrder" SG_ 1913 DTCIUnused6_779 6;
BA_ "SignalLongName" SG_ 1913 DTCIUnused6_779 "Diagnostic Trouble Code Information Extended 779 : Unused 6";
BA_ "VNSigAllNodes" SG_ 1913 DTCIUnused6_779 1;
BA_ "SignalType" SG_ 1913 DTCIUnused5_779 "BLN";
BA_ "PacketOrder" SG_ 1913 DTCIUnused5_779 5;
BA_ "SignalLongName" SG_ 1913 DTCIUnused5_779 "Diagnostic Trouble Code Information Extended 779 : Unused 5";
BA_ "VNSigAllNodes" SG_ 1913 DTCIUnused5_779 1;
BA_ "SignalType" SG_ 1913 DTCIUnused4_779 "BLN";
BA_ "PacketOrder" SG_ 1913 DTCIUnused4_779 4;
BA_ "SignalLongName" SG_ 1913 DTCIUnused4_779 "Diagnostic Trouble Code Information Extended 779 : Unused 4";
BA_ "VNSigAllNodes" SG_ 1913 DTCIUnused4_779 1;
BA_ "SignalType" SG_ 1913 DTCIUnused3_779 "BLN";
BA_ "PacketOrder" SG_ 1913 DTCIUnused3_779 3;
BA_ "SignalLongName" SG_ 1913 DTCIUnused3_779 "Diagnostic Trouble Code Information Extended 779 : Unused 3";
BA_ "VNSigAllNodes" SG_ 1913 DTCIUnused3_779 1;
BA_ "SignalType" SG_ 1913 DTCIUnused2_779 "BLN";
BA_ "PacketOrder" SG_ 1913 DTCIUnused2_779 2;
BA_ "SignalLongName" SG_ 1913 DTCIUnused2_779 "Diagnostic Trouble Code Information Extended 779 : Unused 2";
BA_ "VNSigAllNodes" SG_ 1913 DTCIUnused2_779 1;
BA_ "SignalType" SG_ 1913 DTCIUnused1_779 "BLN";
BA_ "PacketOrder" SG_ 1913 DTCIUnused1_779 1;
BA_ "SignalLongName" SG_ 1913 DTCIUnused1_779 "Diagnostic Trouble Code Information Extended 779 : Unused 1";
BA_ "VNSigAllNodes" SG_ 1913 DTCIUnused1_779 1;
BA_ "SignalType" SG_ 1916 DTCI_DTCFaultType_77C "ENM";
BA_ "PacketOrder" SG_ 1916 DTCI_DTCFaultType_77C 20;
BA_ "SignalLongName" SG_ 1916 DTCI_DTCFaultType_77C "Diagnostic Trouble Code Information Extended 77C : Diagnostic Trouble Code Fault Type";
BA_ "VNSigAllNodes" SG_ 1916 DTCI_DTCFaultType_77C 1;
BA_ "SignalType" SG_ 1916 DTCI_CodeSupported_77C "BLN";
BA_ "PacketOrder" SG_ 1916 DTCI_CodeSupported_77C 19;
BA_ "SignalLongName" SG_ 1916 DTCI_CodeSupported_77C "Diagnostic Trouble Code Information Extended 77C : Code Supported";
BA_ "VNSigAllNodes" SG_ 1916 DTCI_CodeSupported_77C 1;
BA_ "SignalType" SG_ 1916 DTCI_CurrentStatus_77C "BLN";
BA_ "PacketOrder" SG_ 1916 DTCI_CurrentStatus_77C 18;
BA_ "SignalLongName" SG_ 1916 DTCI_CurrentStatus_77C "Diagnostic Trouble Code Information Extended 77C : Current Status";
BA_ "VNSigAllNodes" SG_ 1916 DTCI_CurrentStatus_77C 1;
BA_ "SignalType" SG_ 1916 DTCI_TstNPsdCdClrdSt_77C "BLN";
BA_ "PacketOrder" SG_ 1916 DTCI_TstNPsdCdClrdSt_77C 17;
BA_ "SignalLongName" SG_ 1916 DTCI_TstNPsdCdClrdSt_77C "Diagnostic Trouble Code Information Extended 77C : Test Not Passed Since Code Cleared Status";
BA_ "VNSigAllNodes" SG_ 1916 DTCI_TstNPsdCdClrdSt_77C 1;
BA_ "SignalType" SG_ 1916 DTCI_TstFldCdClrdStat_77C "BLN";
BA_ "PacketOrder" SG_ 1916 DTCI_TstFldCdClrdStat_77C 16;
BA_ "SignalLongName" SG_ 1916 DTCI_TstFldCdClrdStat_77C "Diagnostic Trouble Code Information Extended 77C : Test Failed Since Code Cleared Status";
BA_ "VNSigAllNodes" SG_ 1916 DTCI_TstFldCdClrdStat_77C 1;
BA_ "SignalType" SG_ 1916 DTCI_HistStat_77C "BLN";
BA_ "PacketOrder" SG_ 1916 DTCI_HistStat_77C 15;
BA_ "SignalLongName" SG_ 1916 DTCI_HistStat_77C "Diagnostic Trouble Code Information Extended 77C : History Status";
BA_ "VNSigAllNodes" SG_ 1916 DTCI_HistStat_77C 1;
BA_ "SignalType" SG_ 1916 DTCI_TstNPsdPwrUpSt_77C "BLN";
BA_ "PacketOrder" SG_ 1916 DTCI_TstNPsdPwrUpSt_77C 14;
BA_ "SignalLongName" SG_ 1916 DTCI_TstNPsdPwrUpSt_77C "Diagnostic Trouble Code Information Extended 77C : Test Not Passed Since Power Up Status";
BA_ "VNSigAllNodes" SG_ 1916 DTCI_TstNPsdPwrUpSt_77C 1;
BA_ "SignalType" SG_ 1916 DTCI_TstFldPwrUpSt_77C "BLN";
BA_ "PacketOrder" SG_ 1916 DTCI_TstFldPwrUpSt_77C 13;
BA_ "SignalLongName" SG_ 1916 DTCI_TstFldPwrUpSt_77C "Diagnostic Trouble Code Information Extended 77C : Test Failed Since Power Up Status";
BA_ "VNSigAllNodes" SG_ 1916 DTCI_TstFldPwrUpSt_77C 1;
BA_ "SignalType" SG_ 1916 DTCI_WrnIndRqdSt_77C "BLN";
BA_ "PacketOrder" SG_ 1916 DTCI_WrnIndRqdSt_77C 12;
BA_ "SignalLongName" SG_ 1916 DTCI_WrnIndRqdSt_77C "Diagnostic Trouble Code Information Extended 77C : Warning Indicator Requested Status";
BA_ "VNSigAllNodes" SG_ 1916 DTCI_WrnIndRqdSt_77C 1;
BA_ "SignalType" SG_ 1916 DTCI_DTCFailType_77C "UNM";
BA_ "PacketOrder" SG_ 1916 DTCI_DTCFailType_77C 11;
BA_ "SignalLongName" SG_ 1916 DTCI_DTCFailType_77C "Diagnostic Trouble Code Information Extended 77C : Diagnostic Trouble Code Failure Type";
BA_ "VNSigAllNodes" SG_ 1916 DTCI_DTCFailType_77C 1;
BA_ "SignalType" SG_ 1916 DTCI_DTCNumber_77C "UNM";
BA_ "PacketOrder" SG_ 1916 DTCI_DTCNumber_77C 10;
BA_ "SignalLongName" SG_ 1916 DTCI_DTCNumber_77C "Diagnostic Trouble Code Information Extended 77C : Diagnostic Trouble Code Number";
BA_ "VNSigAllNodes" SG_ 1916 DTCI_DTCNumber_77C 1;
BA_ "SignalType" SG_ 1916 DTCI_DTCSource_77C "UNM";
BA_ "PacketOrder" SG_ 1916 DTCI_DTCSource_77C 9;
BA_ "SignalLongName" SG_ 1916 DTCI_DTCSource_77C "Diagnostic Trouble Code Information Extended 77C : Diagnostic Trouble Code Source";
BA_ "VNSigAllNodes" SG_ 1916 DTCI_DTCSource_77C 1;
BA_ "SignalType" SG_ 1916 DTCI_DTCTriggered_77C "BLN";
BA_ "PacketOrder" SG_ 1916 DTCI_DTCTriggered_77C 8;
BA_ "SignalLongName" SG_ 1916 DTCI_DTCTriggered_77C "Diagnostic Trouble Code Information Extended 77C : Diagnostic Trouble Code Triggered";
BA_ "VNSigAllNodes" SG_ 1916 DTCI_DTCTriggered_77C 1;
BA_ "SignalType" SG_ 1916 DTCIUnused7_77C "BLN";
BA_ "PacketOrder" SG_ 1916 DTCIUnused7_77C 7;
BA_ "SignalLongName" SG_ 1916 DTCIUnused7_77C "Diagnostic Trouble Code Information Extended 77C : Unused 7";
BA_ "VNSigAllNodes" SG_ 1916 DTCIUnused7_77C 1;
BA_ "SignalType" SG_ 1916 DTCIUnused6_77C "BLN";
BA_ "PacketOrder" SG_ 1916 DTCIUnused6_77C 6;
BA_ "SignalLongName" SG_ 1916 DTCIUnused6_77C "Diagnostic Trouble Code Information Extended 77C : Unused 6";
BA_ "VNSigAllNodes" SG_ 1916 DTCIUnused6_77C 1;
BA_ "SignalType" SG_ 1916 DTCIUnused5_77C "BLN";
BA_ "PacketOrder" SG_ 1916 DTCIUnused5_77C 5;
BA_ "SignalLongName" SG_ 1916 DTCIUnused5_77C "Diagnostic Trouble Code Information Extended 77C : Unused 5";
BA_ "VNSigAllNodes" SG_ 1916 DTCIUnused5_77C 1;
BA_ "SignalType" SG_ 1916 DTCIUnused4_77C "BLN";
BA_ "PacketOrder" SG_ 1916 DTCIUnused4_77C 4;
BA_ "SignalLongName" SG_ 1916 DTCIUnused4_77C "Diagnostic Trouble Code Information Extended 77C : Unused 4";
BA_ "VNSigAllNodes" SG_ 1916 DTCIUnused4_77C 1;
BA_ "SignalType" SG_ 1916 DTCIUnused3_77C "BLN";
BA_ "PacketOrder" SG_ 1916 DTCIUnused3_77C 3;
BA_ "SignalLongName" SG_ 1916 DTCIUnused3_77C "Diagnostic Trouble Code Information Extended 77C : Unused 3";
BA_ "VNSigAllNodes" SG_ 1916 DTCIUnused3_77C 1;
BA_ "SignalType" SG_ 1916 DTCIUnused2_77C "BLN";
BA_ "PacketOrder" SG_ 1916 DTCIUnused2_77C 2;
BA_ "SignalLongName" SG_ 1916 DTCIUnused2_77C "Diagnostic Trouble Code Information Extended 77C : Unused 2";
BA_ "VNSigAllNodes" SG_ 1916 DTCIUnused2_77C 1;
BA_ "SignalType" SG_ 1916 DTCIUnused1_77C "BLN";
BA_ "PacketOrder" SG_ 1916 DTCIUnused1_77C 1;
BA_ "SignalLongName" SG_ 1916 DTCIUnused1_77C "Diagnostic Trouble Code Information Extended 77C : Unused 1";
BA_ "VNSigAllNodes" SG_ 1916 DTCIUnused1_77C 1;
BA_ "SignalType" SG_ 1917 DTCI_DTCFaultType_77D "ENM";
BA_ "PacketOrder" SG_ 1917 DTCI_DTCFaultType_77D 20;
BA_ "SignalLongName" SG_ 1917 DTCI_DTCFaultType_77D "Diagnostic Trouble Code Information Extended 77D : Diagnostic Trouble Code Fault Type";
BA_ "VNSigAllNodes" SG_ 1917 DTCI_DTCFaultType_77D 1;
BA_ "SignalType" SG_ 1917 DTCI_CodeSupported_77D "BLN";
BA_ "PacketOrder" SG_ 1917 DTCI_CodeSupported_77D 19;
BA_ "SignalLongName" SG_ 1917 DTCI_CodeSupported_77D "Diagnostic Trouble Code Information Extended 77D : Code Supported";
BA_ "VNSigAllNodes" SG_ 1917 DTCI_CodeSupported_77D 1;
BA_ "SignalType" SG_ 1917 DTCI_CurrentStatus_77D "BLN";
BA_ "PacketOrder" SG_ 1917 DTCI_CurrentStatus_77D 18;
BA_ "SignalLongName" SG_ 1917 DTCI_CurrentStatus_77D "Diagnostic Trouble Code Information Extended 77D : Current Status";
BA_ "VNSigAllNodes" SG_ 1917 DTCI_CurrentStatus_77D 1;
BA_ "SignalType" SG_ 1917 DTCI_TstNPsdCdClrdSt_77D "BLN";
BA_ "PacketOrder" SG_ 1917 DTCI_TstNPsdCdClrdSt_77D 17;
BA_ "SignalLongName" SG_ 1917 DTCI_TstNPsdCdClrdSt_77D "Diagnostic Trouble Code Information Extended 77D : Test Not Passed Since Code Cleared Status";
BA_ "VNSigAllNodes" SG_ 1917 DTCI_TstNPsdCdClrdSt_77D 1;
BA_ "SignalType" SG_ 1917 DTCI_TstFldCdClrdStat_77D "BLN";
BA_ "PacketOrder" SG_ 1917 DTCI_TstFldCdClrdStat_77D 16;
BA_ "SignalLongName" SG_ 1917 DTCI_TstFldCdClrdStat_77D "Diagnostic Trouble Code Information Extended 77D : Test Failed Since Code Cleared Status";
BA_ "VNSigAllNodes" SG_ 1917 DTCI_TstFldCdClrdStat_77D 1;
BA_ "SignalType" SG_ 1917 DTCI_HistStat_77D "BLN";
BA_ "PacketOrder" SG_ 1917 DTCI_HistStat_77D 15;
BA_ "SignalLongName" SG_ 1917 DTCI_HistStat_77D "Diagnostic Trouble Code Information Extended 77D : History Status";
BA_ "VNSigAllNodes" SG_ 1917 DTCI_HistStat_77D 1;
BA_ "SignalType" SG_ 1917 DTCI_TstNPsdPwrUpSt_77D "BLN";
BA_ "PacketOrder" SG_ 1917 DTCI_TstNPsdPwrUpSt_77D 14;
BA_ "SignalLongName" SG_ 1917 DTCI_TstNPsdPwrUpSt_77D "Diagnostic Trouble Code Information Extended 77D : Test Not Passed Since Power Up Status";
BA_ "VNSigAllNodes" SG_ 1917 DTCI_TstNPsdPwrUpSt_77D 1;
BA_ "SignalType" SG_ 1917 DTCI_TstFldPwrUpSt_77D "BLN";
BA_ "PacketOrder" SG_ 1917 DTCI_TstFldPwrUpSt_77D 13;
BA_ "SignalLongName" SG_ 1917 DTCI_TstFldPwrUpSt_77D "Diagnostic Trouble Code Information Extended 77D : Test Failed Since Power Up Status";
BA_ "VNSigAllNodes" SG_ 1917 DTCI_TstFldPwrUpSt_77D 1;
BA_ "SignalType" SG_ 1917 DTCI_WrnIndRqdSt_77D "BLN";
BA_ "PacketOrder" SG_ 1917 DTCI_WrnIndRqdSt_77D 12;
BA_ "SignalLongName" SG_ 1917 DTCI_WrnIndRqdSt_77D "Diagnostic Trouble Code Information Extended 77D : Warning Indicator Requested Status";
BA_ "VNSigAllNodes" SG_ 1917 DTCI_WrnIndRqdSt_77D 1;
BA_ "SignalType" SG_ 1917 DTCI_DTCFailType_77D "UNM";
BA_ "PacketOrder" SG_ 1917 DTCI_DTCFailType_77D 11;
BA_ "SignalLongName" SG_ 1917 DTCI_DTCFailType_77D "Diagnostic Trouble Code Information Extended 77D : Diagnostic Trouble Code Failure Type";
BA_ "VNSigAllNodes" SG_ 1917 DTCI_DTCFailType_77D 1;
BA_ "SignalType" SG_ 1917 DTCI_DTCNumber_77D "UNM";
BA_ "PacketOrder" SG_ 1917 DTCI_DTCNumber_77D 10;
BA_ "SignalLongName" SG_ 1917 DTCI_DTCNumber_77D "Diagnostic Trouble Code Information Extended 77D : Diagnostic Trouble Code Number";
BA_ "VNSigAllNodes" SG_ 1917 DTCI_DTCNumber_77D 1;
BA_ "SignalType" SG_ 1917 DTCI_DTCSource_77D "UNM";
BA_ "PacketOrder" SG_ 1917 DTCI_DTCSource_77D 9;
BA_ "SignalLongName" SG_ 1917 DTCI_DTCSource_77D "Diagnostic Trouble Code Information Extended 77D : Diagnostic Trouble Code Source";
BA_ "VNSigAllNodes" SG_ 1917 DTCI_DTCSource_77D 1;
BA_ "SignalType" SG_ 1917 DTCI_DTCTriggered_77D "BLN";
BA_ "PacketOrder" SG_ 1917 DTCI_DTCTriggered_77D 8;
BA_ "SignalLongName" SG_ 1917 DTCI_DTCTriggered_77D "Diagnostic Trouble Code Information Extended 77D : Diagnostic Trouble Code Triggered";
BA_ "VNSigAllNodes" SG_ 1917 DTCI_DTCTriggered_77D 1;
BA_ "SignalType" SG_ 1917 DTCIUnused7_77D "BLN";
BA_ "PacketOrder" SG_ 1917 DTCIUnused7_77D 7;
BA_ "SignalLongName" SG_ 1917 DTCIUnused7_77D "Diagnostic Trouble Code Information Extended 77D : Unused 7";
BA_ "VNSigAllNodes" SG_ 1917 DTCIUnused7_77D 1;
BA_ "SignalType" SG_ 1917 DTCIUnused6_77D "BLN";
BA_ "PacketOrder" SG_ 1917 DTCIUnused6_77D 6;
BA_ "SignalLongName" SG_ 1917 DTCIUnused6_77D "Diagnostic Trouble Code Information Extended 77D : Unused 6";
BA_ "VNSigAllNodes" SG_ 1917 DTCIUnused6_77D 1;
BA_ "SignalType" SG_ 1917 DTCIUnused5_77D "BLN";
BA_ "PacketOrder" SG_ 1917 DTCIUnused5_77D 5;
BA_ "SignalLongName" SG_ 1917 DTCIUnused5_77D "Diagnostic Trouble Code Information Extended 77D : Unused 5";
BA_ "VNSigAllNodes" SG_ 1917 DTCIUnused5_77D 1;
BA_ "SignalType" SG_ 1917 DTCIUnused4_77D "BLN";
BA_ "PacketOrder" SG_ 1917 DTCIUnused4_77D 4;
BA_ "SignalLongName" SG_ 1917 DTCIUnused4_77D "Diagnostic Trouble Code Information Extended 77D : Unused 4";
BA_ "VNSigAllNodes" SG_ 1917 DTCIUnused4_77D 1;
BA_ "SignalType" SG_ 1917 DTCIUnused3_77D "BLN";
BA_ "PacketOrder" SG_ 1917 DTCIUnused3_77D 3;
BA_ "SignalLongName" SG_ 1917 DTCIUnused3_77D "Diagnostic Trouble Code Information Extended 77D : Unused 3";
BA_ "VNSigAllNodes" SG_ 1917 DTCIUnused3_77D 1;
BA_ "SignalType" SG_ 1917 DTCIUnused2_77D "BLN";
BA_ "PacketOrder" SG_ 1917 DTCIUnused2_77D 2;
BA_ "SignalLongName" SG_ 1917 DTCIUnused2_77D "Diagnostic Trouble Code Information Extended 77D : Unused 2";
BA_ "VNSigAllNodes" SG_ 1917 DTCIUnused2_77D 1;
BA_ "SignalType" SG_ 1917 DTCIUnused1_77D "BLN";
BA_ "PacketOrder" SG_ 1917 DTCIUnused1_77D 1;
BA_ "SignalLongName" SG_ 1917 DTCIUnused1_77D "Diagnostic Trouble Code Information Extended 77D : Unused 1";
BA_ "VNSigAllNodes" SG_ 1917 DTCIUnused1_77D 1;
BA_ "SignalType" SG_ 1918 DTCI_DTCFaultType_77E "ENM";
BA_ "PacketOrder" SG_ 1918 DTCI_DTCFaultType_77E 20;
BA_ "SignalLongName" SG_ 1918 DTCI_DTCFaultType_77E "Diagnostic Trouble Code Information Extended 77E : Diagnostic Trouble Code Fault Type";
BA_ "VNSigAllNodes" SG_ 1918 DTCI_DTCFaultType_77E 1;
BA_ "SignalType" SG_ 1918 DTCI_CodeSupported_77E "BLN";
BA_ "PacketOrder" SG_ 1918 DTCI_CodeSupported_77E 19;
BA_ "SignalLongName" SG_ 1918 DTCI_CodeSupported_77E "Diagnostic Trouble Code Information Extended 77E : Code Supported";
BA_ "VNSigAllNodes" SG_ 1918 DTCI_CodeSupported_77E 1;
BA_ "SignalType" SG_ 1918 DTCI_CurrentStatus_77E "BLN";
BA_ "PacketOrder" SG_ 1918 DTCI_CurrentStatus_77E 18;
BA_ "SignalLongName" SG_ 1918 DTCI_CurrentStatus_77E "Diagnostic Trouble Code Information Extended 77E : Current Status";
BA_ "VNSigAllNodes" SG_ 1918 DTCI_CurrentStatus_77E 1;
BA_ "SignalType" SG_ 1918 DTCI_TstNPsdCdClrdSt_77E "BLN";
BA_ "PacketOrder" SG_ 1918 DTCI_TstNPsdCdClrdSt_77E 17;
BA_ "SignalLongName" SG_ 1918 DTCI_TstNPsdCdClrdSt_77E "Diagnostic Trouble Code Information Extended 77E : Test Not Passed Since Code Cleared Status";
BA_ "VNSigAllNodes" SG_ 1918 DTCI_TstNPsdCdClrdSt_77E 1;
BA_ "SignalType" SG_ 1918 DTCI_TstFldCdClrdStat_77E "BLN";
BA_ "PacketOrder" SG_ 1918 DTCI_TstFldCdClrdStat_77E 16;
BA_ "SignalLongName" SG_ 1918 DTCI_TstFldCdClrdStat_77E "Diagnostic Trouble Code Information Extended 77E : Test Failed Since Code Cleared Status";
BA_ "VNSigAllNodes" SG_ 1918 DTCI_TstFldCdClrdStat_77E 1;
BA_ "SignalType" SG_ 1918 DTCI_HistStat_77E "BLN";
BA_ "PacketOrder" SG_ 1918 DTCI_HistStat_77E 15;
BA_ "SignalLongName" SG_ 1918 DTCI_HistStat_77E "Diagnostic Trouble Code Information Extended 77E : History Status";
BA_ "VNSigAllNodes" SG_ 1918 DTCI_HistStat_77E 1;
BA_ "SignalType" SG_ 1918 DTCI_TstNPsdPwrUpSt_77E "BLN";
BA_ "PacketOrder" SG_ 1918 DTCI_TstNPsdPwrUpSt_77E 14;
BA_ "SignalLongName" SG_ 1918 DTCI_TstNPsdPwrUpSt_77E "Diagnostic Trouble Code Information Extended 77E : Test Not Passed Since Power Up Status";
BA_ "VNSigAllNodes" SG_ 1918 DTCI_TstNPsdPwrUpSt_77E 1;
BA_ "SignalType" SG_ 1918 DTCI_TstFldPwrUpSt_77E "BLN";
BA_ "PacketOrder" SG_ 1918 DTCI_TstFldPwrUpSt_77E 13;
BA_ "SignalLongName" SG_ 1918 DTCI_TstFldPwrUpSt_77E "Diagnostic Trouble Code Information Extended 77E : Test Failed Since Power Up Status";
BA_ "VNSigAllNodes" SG_ 1918 DTCI_TstFldPwrUpSt_77E 1;
BA_ "SignalType" SG_ 1918 DTCI_WrnIndRqdSt_77E "BLN";
BA_ "PacketOrder" SG_ 1918 DTCI_WrnIndRqdSt_77E 12;
BA_ "SignalLongName" SG_ 1918 DTCI_WrnIndRqdSt_77E "Diagnostic Trouble Code Information Extended 77E : Warning Indicator Requested Status";
BA_ "VNSigAllNodes" SG_ 1918 DTCI_WrnIndRqdSt_77E 1;
BA_ "SignalType" SG_ 1918 DTCI_DTCFailType_77E "UNM";
BA_ "PacketOrder" SG_ 1918 DTCI_DTCFailType_77E 11;
BA_ "SignalLongName" SG_ 1918 DTCI_DTCFailType_77E "Diagnostic Trouble Code Information Extended 77E : Diagnostic Trouble Code Failure Type";
BA_ "VNSigAllNodes" SG_ 1918 DTCI_DTCFailType_77E 1;
BA_ "SignalType" SG_ 1918 DTCI_DTCNumber_77E "UNM";
BA_ "PacketOrder" SG_ 1918 DTCI_DTCNumber_77E 10;
BA_ "SignalLongName" SG_ 1918 DTCI_DTCNumber_77E "Diagnostic Trouble Code Information Extended 77E : Diagnostic Trouble Code Number";
BA_ "VNSigAllNodes" SG_ 1918 DTCI_DTCNumber_77E 1;
BA_ "SignalType" SG_ 1918 DTCI_DTCSource_77E "UNM";
BA_ "PacketOrder" SG_ 1918 DTCI_DTCSource_77E 9;
BA_ "SignalLongName" SG_ 1918 DTCI_DTCSource_77E "Diagnostic Trouble Code Information Extended 77E : Diagnostic Trouble Code Source";
BA_ "VNSigAllNodes" SG_ 1918 DTCI_DTCSource_77E 1;
BA_ "SignalType" SG_ 1918 DTCI_DTCTriggered_77E "BLN";
BA_ "PacketOrder" SG_ 1918 DTCI_DTCTriggered_77E 8;
BA_ "SignalLongName" SG_ 1918 DTCI_DTCTriggered_77E "Diagnostic Trouble Code Information Extended 77E : Diagnostic Trouble Code Triggered";
BA_ "VNSigAllNodes" SG_ 1918 DTCI_DTCTriggered_77E 1;
BA_ "SignalType" SG_ 1918 DTCIUnused7_77E "BLN";
BA_ "PacketOrder" SG_ 1918 DTCIUnused7_77E 7;
BA_ "SignalLongName" SG_ 1918 DTCIUnused7_77E "Diagnostic Trouble Code Information Extended 77E : Unused 7";
BA_ "VNSigAllNodes" SG_ 1918 DTCIUnused7_77E 1;
BA_ "SignalType" SG_ 1918 DTCIUnused6_77E "BLN";
BA_ "PacketOrder" SG_ 1918 DTCIUnused6_77E 6;
BA_ "SignalLongName" SG_ 1918 DTCIUnused6_77E "Diagnostic Trouble Code Information Extended 77E : Unused 6";
BA_ "VNSigAllNodes" SG_ 1918 DTCIUnused6_77E 1;
BA_ "SignalType" SG_ 1918 DTCIUnused5_77E "BLN";
BA_ "PacketOrder" SG_ 1918 DTCIUnused5_77E 5;
BA_ "SignalLongName" SG_ 1918 DTCIUnused5_77E "Diagnostic Trouble Code Information Extended 77E : Unused 5";
BA_ "VNSigAllNodes" SG_ 1918 DTCIUnused5_77E 1;
BA_ "SignalType" SG_ 1918 DTCIUnused4_77E "BLN";
BA_ "PacketOrder" SG_ 1918 DTCIUnused4_77E 4;
BA_ "SignalLongName" SG_ 1918 DTCIUnused4_77E "Diagnostic Trouble Code Information Extended 77E : Unused 4";
BA_ "VNSigAllNodes" SG_ 1918 DTCIUnused4_77E 1;
BA_ "SignalType" SG_ 1918 DTCIUnused3_77E "BLN";
BA_ "PacketOrder" SG_ 1918 DTCIUnused3_77E 3;
BA_ "SignalLongName" SG_ 1918 DTCIUnused3_77E "Diagnostic Trouble Code Information Extended 77E : Unused 3";
BA_ "VNSigAllNodes" SG_ 1918 DTCIUnused3_77E 1;
BA_ "SignalType" SG_ 1918 DTCIUnused2_77E "BLN";
BA_ "PacketOrder" SG_ 1918 DTCIUnused2_77E 2;
BA_ "SignalLongName" SG_ 1918 DTCIUnused2_77E "Diagnostic Trouble Code Information Extended 77E : Unused 2";
BA_ "VNSigAllNodes" SG_ 1918 DTCIUnused2_77E 1;
BA_ "SignalType" SG_ 1918 DTCIUnused1_77E "BLN";
BA_ "PacketOrder" SG_ 1918 DTCIUnused1_77E 1;
BA_ "SignalLongName" SG_ 1918 DTCIUnused1_77E "Diagnostic Trouble Code Information Extended 77E : Unused 1";
BA_ "VNSigAllNodes" SG_ 1918 DTCIUnused1_77E 1;
BA_ "SignalType" SG_ 1919 DTCI_DTCFaultType_77F "ENM";
BA_ "PacketOrder" SG_ 1919 DTCI_DTCFaultType_77F 20;
BA_ "SignalLongName" SG_ 1919 DTCI_DTCFaultType_77F "Diagnostic Trouble Code Information Extended 77F : Diagnostic Trouble Code Fault Type";
BA_ "VNSigAllNodes" SG_ 1919 DTCI_DTCFaultType_77F 1;
BA_ "SignalType" SG_ 1919 DTCI_CodeSupported_77F "BLN";
BA_ "PacketOrder" SG_ 1919 DTCI_CodeSupported_77F 19;
BA_ "SignalLongName" SG_ 1919 DTCI_CodeSupported_77F "Diagnostic Trouble Code Information Extended 77F : Code Supported";
BA_ "VNSigAllNodes" SG_ 1919 DTCI_CodeSupported_77F 1;
BA_ "SignalType" SG_ 1919 DTCI_CurrentStatus_77F "BLN";
BA_ "PacketOrder" SG_ 1919 DTCI_CurrentStatus_77F 18;
BA_ "SignalLongName" SG_ 1919 DTCI_CurrentStatus_77F "Diagnostic Trouble Code Information Extended 77F : Current Status";
BA_ "VNSigAllNodes" SG_ 1919 DTCI_CurrentStatus_77F 1;
BA_ "SignalType" SG_ 1919 DTCI_TstNPsdCdClrdSt_77F "BLN";
BA_ "PacketOrder" SG_ 1919 DTCI_TstNPsdCdClrdSt_77F 17;
BA_ "SignalLongName" SG_ 1919 DTCI_TstNPsdCdClrdSt_77F "Diagnostic Trouble Code Information Extended 77F : Test Not Passed Since Code Cleared Status";
BA_ "VNSigAllNodes" SG_ 1919 DTCI_TstNPsdCdClrdSt_77F 1;
BA_ "SignalType" SG_ 1919 DTCI_TstFldCdClrdStat_77F "BLN";
BA_ "PacketOrder" SG_ 1919 DTCI_TstFldCdClrdStat_77F 16;
BA_ "SignalLongName" SG_ 1919 DTCI_TstFldCdClrdStat_77F "Diagnostic Trouble Code Information Extended 77F : Test Failed Since Code Cleared Status";
BA_ "VNSigAllNodes" SG_ 1919 DTCI_TstFldCdClrdStat_77F 1;
BA_ "SignalType" SG_ 1919 DTCI_HistStat_77F "BLN";
BA_ "PacketOrder" SG_ 1919 DTCI_HistStat_77F 15;
BA_ "SignalLongName" SG_ 1919 DTCI_HistStat_77F "Diagnostic Trouble Code Information Extended 77F : History Status";
BA_ "VNSigAllNodes" SG_ 1919 DTCI_HistStat_77F 1;
BA_ "SignalType" SG_ 1919 DTCI_TstNPsdPwrUpSt_77F "BLN";
BA_ "PacketOrder" SG_ 1919 DTCI_TstNPsdPwrUpSt_77F 14;
BA_ "SignalLongName" SG_ 1919 DTCI_TstNPsdPwrUpSt_77F "Diagnostic Trouble Code Information Extended 77F : Test Not Passed Since Power Up Status";
BA_ "VNSigAllNodes" SG_ 1919 DTCI_TstNPsdPwrUpSt_77F 1;
BA_ "SignalType" SG_ 1919 DTCI_TstFldPwrUpSt_77F "BLN";
BA_ "PacketOrder" SG_ 1919 DTCI_TstFldPwrUpSt_77F 13;
BA_ "SignalLongName" SG_ 1919 DTCI_TstFldPwrUpSt_77F "Diagnostic Trouble Code Information Extended 77F : Test Failed Since Power Up Status";
BA_ "VNSigAllNodes" SG_ 1919 DTCI_TstFldPwrUpSt_77F 1;
BA_ "SignalType" SG_ 1919 DTCI_WrnIndRqdSt_77F "BLN";
BA_ "PacketOrder" SG_ 1919 DTCI_WrnIndRqdSt_77F 12;
BA_ "SignalLongName" SG_ 1919 DTCI_WrnIndRqdSt_77F "Diagnostic Trouble Code Information Extended 77F : Warning Indicator Requested Status";
BA_ "VNSigAllNodes" SG_ 1919 DTCI_WrnIndRqdSt_77F 1;
BA_ "SignalType" SG_ 1919 DTCI_DTCFailType_77F "UNM";
BA_ "PacketOrder" SG_ 1919 DTCI_DTCFailType_77F 11;
BA_ "SignalLongName" SG_ 1919 DTCI_DTCFailType_77F "Diagnostic Trouble Code Information Extended 77F : Diagnostic Trouble Code Failure Type";
BA_ "VNSigAllNodes" SG_ 1919 DTCI_DTCFailType_77F 1;
BA_ "SignalType" SG_ 1919 DTCI_DTCNumber_77F "UNM";
BA_ "PacketOrder" SG_ 1919 DTCI_DTCNumber_77F 10;
BA_ "SignalLongName" SG_ 1919 DTCI_DTCNumber_77F "Diagnostic Trouble Code Information Extended 77F : Diagnostic Trouble Code Number";
BA_ "VNSigAllNodes" SG_ 1919 DTCI_DTCNumber_77F 1;
BA_ "SignalType" SG_ 1919 DTCI_DTCSource_77F "UNM";
BA_ "PacketOrder" SG_ 1919 DTCI_DTCSource_77F 9;
BA_ "SignalLongName" SG_ 1919 DTCI_DTCSource_77F "Diagnostic Trouble Code Information Extended 77F : Diagnostic Trouble Code Source";
BA_ "VNSigAllNodes" SG_ 1919 DTCI_DTCSource_77F 1;
BA_ "SignalType" SG_ 1919 DTCI_DTCTriggered_77F "BLN";
BA_ "PacketOrder" SG_ 1919 DTCI_DTCTriggered_77F 8;
BA_ "SignalLongName" SG_ 1919 DTCI_DTCTriggered_77F "Diagnostic Trouble Code Information Extended 77F : Diagnostic Trouble Code Triggered";
BA_ "VNSigAllNodes" SG_ 1919 DTCI_DTCTriggered_77F 1;
BA_ "SignalType" SG_ 1919 DTCIUnused7_77F "BLN";
BA_ "PacketOrder" SG_ 1919 DTCIUnused7_77F 7;
BA_ "SignalLongName" SG_ 1919 DTCIUnused7_77F "Diagnostic Trouble Code Information Extended 77F : Unused 7";
BA_ "VNSigAllNodes" SG_ 1919 DTCIUnused7_77F 1;
BA_ "SignalType" SG_ 1919 DTCIUnused6_77F "BLN";
BA_ "PacketOrder" SG_ 1919 DTCIUnused6_77F 6;
BA_ "SignalLongName" SG_ 1919 DTCIUnused6_77F "Diagnostic Trouble Code Information Extended 77F : Unused 6";
BA_ "VNSigAllNodes" SG_ 1919 DTCIUnused6_77F 1;
BA_ "SignalType" SG_ 1919 DTCIUnused5_77F "BLN";
BA_ "PacketOrder" SG_ 1919 DTCIUnused5_77F 5;
BA_ "SignalLongName" SG_ 1919 DTCIUnused5_77F "Diagnostic Trouble Code Information Extended 77F : Unused 5";
BA_ "VNSigAllNodes" SG_ 1919 DTCIUnused5_77F 1;
BA_ "SignalType" SG_ 1919 DTCIUnused4_77F "BLN";
BA_ "PacketOrder" SG_ 1919 DTCIUnused4_77F 4;
BA_ "SignalLongName" SG_ 1919 DTCIUnused4_77F "Diagnostic Trouble Code Information Extended 77F : Unused 4";
BA_ "VNSigAllNodes" SG_ 1919 DTCIUnused4_77F 1;
BA_ "SignalType" SG_ 1919 DTCIUnused3_77F "BLN";
BA_ "PacketOrder" SG_ 1919 DTCIUnused3_77F 3;
BA_ "SignalLongName" SG_ 1919 DTCIUnused3_77F "Diagnostic Trouble Code Information Extended 77F : Unused 3";
BA_ "VNSigAllNodes" SG_ 1919 DTCIUnused3_77F 1;
BA_ "SignalType" SG_ 1919 DTCIUnused2_77F "BLN";
BA_ "PacketOrder" SG_ 1919 DTCIUnused2_77F 2;
BA_ "SignalLongName" SG_ 1919 DTCIUnused2_77F "Diagnostic Trouble Code Information Extended 77F : Unused 2";
BA_ "VNSigAllNodes" SG_ 1919 DTCIUnused2_77F 1;
BA_ "SignalType" SG_ 1919 DTCIUnused1_77F "BLN";
BA_ "PacketOrder" SG_ 1919 DTCIUnused1_77F 1;
BA_ "SignalLongName" SG_ 1919 DTCIUnused1_77F "Diagnostic Trouble Code Information Extended 77F : Unused 1";
BA_ "VNSigAllNodes" SG_ 1919 DTCIUnused1_77F 1;
BA_ "VNSigSLHSSharedDiagnostic" SG_ 589 DgnInf 1;
BA_ "SignalType" SG_ 589 DgnInf "UNM";
BA_ "SignalLongName" SG_ 589 DgnInf "Diagnostic Information";
BA_ "VNSigAllNodes" SG_ 589 DgnInf 1;
BA_ "VNSigSLHSSharedDiagnostic" SG_ 1357 DgnInf_HS54D 1;
BA_ "SignalType" SG_ 1357 DgnInf_HS54D "UNM";
BA_ "SignalLongName" SG_ 1357 DgnInf_HS54D "Diagnostic Information HS54D";
BA_ "VNSigAllNodes" SG_ 1357 DgnInf_HS54D 1;
BA_ "VNSigSLHSSharedDiagnostic" SG_ 1613 DgnInf 1;
BA_ "SignalType" SG_ 1613 DgnInf "UNM";
BA_ "SignalLongName" SG_ 1613 DgnInf "Diagnostic Information";
BA_ "VNSigAllNodes" SG_ 1613 DgnInf 1;
BA_ "VNSigSLHSSharedDiagnostic" SG_ 1606 DgnInf 1;
BA_ "SignalType" SG_ 1606 DgnInf "UNM";
BA_ "SignalLongName" SG_ 1606 DgnInf "Diagnostic Information";
BA_ "VNSigAllNodes" SG_ 1606 DgnInf 1;
BA_ "VNSigSLHSSharedDiagnostic" SG_ 582 DgnInf 1;
BA_ "SignalType" SG_ 582 DgnInf "UNM";
BA_ "SignalLongName" SG_ 582 DgnInf "Diagnostic Information";
BA_ "VNSigAllNodes" SG_ 582 DgnInf 1;
BA_ "VNSigSLHSSharedDiagnostic" SG_ 590 DgnInf 1;
BA_ "SignalType" SG_ 590 DgnInf "UNM";
BA_ "SignalLongName" SG_ 590 DgnInf "Diagnostic Information";
BA_ "VNSigAllNodes" SG_ 590 DgnInf 1;
BA_ "VNSigSLHSSharedDiagnostic" SG_ 601 DgnInf 1;
BA_ "SignalType" SG_ 601 DgnInf "UNM";
BA_ "SignalLongName" SG_ 601 DgnInf "Diagnostic Information";
BA_ "VNSigAllNodes" SG_ 601 DgnInf 1;
BA_ "VNSigSLHSSharedDiagnostic" SG_ 1369 DgnInf_HS559 1;
BA_ "SignalType" SG_ 1369 DgnInf_HS559 "UNM";
BA_ "SignalLongName" SG_ 1369 DgnInf_HS559 "Diagnostic Information HS559";
BA_ "VNSigAllNodes" SG_ 1369 DgnInf_HS559 1;
BA_ "VNSigSLHSSharedDiagnostic" SG_ 1625 DgnInf 1;
BA_ "SignalType" SG_ 1625 DgnInf "UNM";
BA_ "SignalLongName" SG_ 1625 DgnInf "Diagnostic Information";
BA_ "VNSigAllNodes" SG_ 1625 DgnInf 1;
BA_ "VNSigSLHSSharedDiagnostic" SG_ 1356 DgnInf_HS54C 1;
BA_ "SignalType" SG_ 1356 DgnInf_HS54C "UNM";
BA_ "SignalLongName" SG_ 1356 DgnInf_HS54C "Diagnostic Information HS54C";
BA_ "VNSigAllNodes" SG_ 1356 DgnInf_HS54C 1;
BA_ "VNSigSLHSSharedDiagnostic" SG_ 1358 DgnInf_HS54E 1;
BA_ "SignalType" SG_ 1358 DgnInf_HS54E "UNM";
BA_ "SignalLongName" SG_ 1358 DgnInf_HS54E "Diagnostic Information HS54E";
BA_ "VNSigAllNodes" SG_ 1358 DgnInf_HS54E 1;
BA_REL_ "GenSigSuprvResp" BU_SG_REL_ FCM_HS SG_ 389 VSELongAccLoRes 1;
BA_REL_ "GenSigTimeoutMsg" BU_SG_REL_ FCM_HS SG_ 389 VSELongAccLoRes 389;
BA_REL_ "GenSigTimeoutTime" BU_SG_REL_ FCM_HS SG_ 389 VSELongAccLoRes 250;
BA_REL_ "GenSigSuprvResp" BU_SG_REL_ VES_HS SG_ 389 VSELongAccLoRes 1;
BA_REL_ "GenSigTimeoutMsg" BU_SG_REL_ VES_HS SG_ 389 VSELongAccLoRes 389;
BA_REL_ "GenSigTimeoutTime" BU_SG_REL_ VES_HS SG_ 389 VSELongAccLoRes 250;
BA_REL_ "GenSigSuprvResp" BU_SG_REL_ EPS_HS SG_ 389 VSELongAccLoRes 1;
BA_REL_ "GenSigTimeoutMsg" BU_SG_REL_ EPS_HS SG_ 389 VSELongAccLoRes 389;
BA_REL_ "GenSigTimeoutTime" BU_SG_REL_ EPS_HS SG_ 389 VSELongAccLoRes 250;
BA_REL_ "GenSigSuprvResp" BU_SG_REL_ ACC_HS SG_ 389 VSELongAccLoRes 1;
BA_REL_ "GenSigTimeoutMsg" BU_SG_REL_ ACC_HS SG_ 389 VSELongAccLoRes 389;
BA_REL_ "GenSigTimeoutTime" BU_SG_REL_ ACC_HS SG_ 389 VSELongAccLoRes 250;
BA_REL_ "GenSigSuprvResp" BU_SG_REL_ EPS_HS SG_ 389 StrAngSnsPolRat 1;
BA_REL_ "GenSigTimeoutMsg" BU_SG_REL_ EPS_HS SG_ 389 StrAngSnsPolRat 389;
BA_REL_ "GenSigTimeoutTime" BU_SG_REL_ EPS_HS SG_ 389 StrAngSnsPolRat 250;
BA_REL_ "GenSigSuprvResp" BU_SG_REL_ EPS_HS SG_ 389 LatAccSnsPolRat 1;
BA_REL_ "GenSigTimeoutMsg" BU_SG_REL_ EPS_HS SG_ 389 LatAccSnsPolRat 389;
BA_REL_ "GenSigTimeoutTime" BU_SG_REL_ EPS_HS SG_ 389 LatAccSnsPolRat 250;
BA_REL_ "GenSigSuprvResp" BU_SG_REL_ BCM_HS SG_ 562 SndPerfMdCsStAvl 1;
BA_REL_ "GenSigTimeoutMsg" BU_SG_REL_ BCM_HS SG_ 562 SndPerfMdCsStAvl 562;
BA_REL_ "GenSigTimeoutTime" BU_SG_REL_ BCM_HS SG_ 562 SndPerfMdCsStAvl 250;
BA_REL_ "GenSigSuprvResp" BU_SG_REL_ BCM_HS SG_ 562 SndPerfMdCsCrStVal 1;
BA_REL_ "GenSigTimeoutMsg" BU_SG_REL_ BCM_HS SG_ 562 SndPerfMdCsCrStVal 562;
BA_REL_ "GenSigTimeoutTime" BU_SG_REL_ BCM_HS SG_ 562 SndPerfMdCsCrStVal 250;
BA_REL_ "GenSigSuprvResp" BU_SG_REL_ BCM_HS SG_ 562 DispPerfMdCsStAvl 1;
BA_REL_ "GenSigTimeoutMsg" BU_SG_REL_ BCM_HS SG_ 562 DispPerfMdCsStAvl 562;
BA_REL_ "GenSigTimeoutTime" BU_SG_REL_ BCM_HS SG_ 562 DispPerfMdCsStAvl 250;
BA_REL_ "GenSigSuprvResp" BU_SG_REL_ BCM_HS SG_ 562 DispPerfMdCsCrStVal 1;
BA_REL_ "GenSigTimeoutMsg" BU_SG_REL_ BCM_HS SG_ 562 DispPerfMdCsCrStVal 562;
BA_REL_ "GenSigTimeoutTime" BU_SG_REL_ BCM_HS SG_ 562 DispPerfMdCsCrStVal 250;
BA_REL_ "GenSigSuprvResp" BU_SG_REL_ ICCM_OBD_HS SG_ 562 DrvlneMntsPerfMdRq 1;
BA_REL_ "GenSigTimeoutMsg" BU_SG_REL_ ICCM_OBD_HS SG_ 562 DrvlneMntsPerfMdRq 562;
BA_REL_ "GenSigTimeoutTime" BU_SG_REL_ ICCM_OBD_HS SG_ 562 DrvlneMntsPerfMdRq 250;
BA_REL_ "GenSigSuprvResp" BU_SG_REL_ ICCM_HS SG_ 562 DrvlneMntsPerfMdRq 1;
BA_REL_ "GenSigTimeoutMsg" BU_SG_REL_ ICCM_HS SG_ 562 DrvlneMntsPerfMdRq 562;
BA_REL_ "GenSigTimeoutTime" BU_SG_REL_ ICCM_HS SG_ 562 DrvlneMntsPerfMdRq 250;
BA_REL_ "GenSigSuprvResp" BU_SG_REL_ SADS_HS SG_ 562 RideCntrlPerfMdRq 1;
BA_REL_ "GenSigTimeoutMsg" BU_SG_REL_ SADS_HS SG_ 562 RideCntrlPerfMdRq 562;
BA_REL_ "GenSigTimeoutTime" BU_SG_REL_ SADS_HS SG_ 562 RideCntrlPerfMdRq 250;
BA_REL_ "GenSigSuprvResp" BU_SG_REL_ VES_HS SG_ 562 StgSysPerfMdRq 1;
BA_REL_ "GenSigTimeoutMsg" BU_SG_REL_ VES_HS SG_ 562 StgSysPerfMdRq 562;
BA_REL_ "GenSigTimeoutTime" BU_SG_REL_ VES_HS SG_ 562 StgSysPerfMdRq 250;
BA_REL_ "GenSigSuprvResp" BU_SG_REL_ EPS_HS SG_ 562 StgSysPerfMdRq 1;
BA_REL_ "GenSigTimeoutMsg" BU_SG_REL_ EPS_HS SG_ 562 StgSysPerfMdRq 562;
BA_REL_ "GenSigTimeoutTime" BU_SG_REL_ EPS_HS SG_ 562 StgSysPerfMdRq 250;
BA_REL_ "GenSigSuprvResp" BU_SG_REL_ ARS_HS SG_ 562 StgSysPerfMdRq 1;
BA_REL_ "GenSigTimeoutMsg" BU_SG_REL_ ARS_HS SG_ 562 StgSysPerfMdRq 562;
BA_REL_ "GenSigTimeoutTime" BU_SG_REL_ ARS_HS SG_ 562 StgSysPerfMdRq 250;
BA_REL_ "GenSigSuprvResp" BU_SG_REL_ AFS_HS SG_ 562 StgSysPerfMdRq 1;
BA_REL_ "GenSigTimeoutMsg" BU_SG_REL_ AFS_HS SG_ 562 StgSysPerfMdRq 562;
BA_REL_ "GenSigTimeoutTime" BU_SG_REL_ AFS_HS SG_ 562 StgSysPerfMdRq 250;
BA_REL_ "GenSigSuprvResp" BU_SG_REL_ ICCM_OBD_HS SG_ 562 DiffPerfMdRq 1;
BA_REL_ "GenSigTimeoutMsg" BU_SG_REL_ ICCM_OBD_HS SG_ 562 DiffPerfMdRq 562;
BA_REL_ "GenSigTimeoutTime" BU_SG_REL_ ICCM_OBD_HS SG_ 562 DiffPerfMdRq 250;
BA_REL_ "GenSigSuprvResp" BU_SG_REL_ ICCM_HS SG_ 562 DiffPerfMdRq 1;
BA_REL_ "GenSigTimeoutMsg" BU_SG_REL_ ICCM_HS SG_ 562 DiffPerfMdRq 562;
BA_REL_ "GenSigTimeoutTime" BU_SG_REL_ ICCM_HS SG_ 562 DiffPerfMdRq 250;
BA_REL_ "GenSigSuprvResp" BU_SG_REL_ BCM_HS SG_ 562 SndEnhcmtPerfMdRq 1;
BA_REL_ "GenSigTimeoutMsg" BU_SG_REL_ BCM_HS SG_ 562 SndEnhcmtPerfMdRq 562;
BA_REL_ "GenSigTimeoutTime" BU_SG_REL_ BCM_HS SG_ 562 SndEnhcmtPerfMdRq 250;
BA_REL_ "GenSigSuprvResp" BU_SG_REL_ AMP_HS SG_ 562 SndEnhcmtPerfMdRq 1;
BA_REL_ "GenSigTimeoutMsg" BU_SG_REL_ AMP_HS SG_ 562 SndEnhcmtPerfMdRq 562;
BA_REL_ "GenSigTimeoutTime" BU_SG_REL_ AMP_HS SG_ 562 SndEnhcmtPerfMdRq 250;
BA_REL_ "GenSigSuprvResp" BU_SG_REL_ BCM_HS SG_ 562 DsplyPerfMdRq 1;
BA_REL_ "GenSigTimeoutMsg" BU_SG_REL_ BCM_HS SG_ 562 DsplyPerfMdRq 562;
BA_REL_ "GenSigTimeoutTime" BU_SG_REL_ BCM_HS SG_ 562 DsplyPerfMdRq 250;
BA_REL_ "GenSigSuprvResp" BU_SG_REL_ FSCM_HS SG_ 562 ExhstPerfMdRq 1;
BA_REL_ "GenSigTimeoutMsg" BU_SG_REL_ FSCM_HS SG_ 562 ExhstPerfMdRq 562;
BA_REL_ "GenSigTimeoutTime" BU_SG_REL_ FSCM_HS SG_ 562 ExhstPerfMdRq 250;
BA_REL_ "GenSigSuprvResp" BU_SG_REL_ ICCM_OBD_HS SG_ 562 ExhstPerfMdRq 1;
BA_REL_ "GenSigTimeoutMsg" BU_SG_REL_ ICCM_OBD_HS SG_ 562 ExhstPerfMdRq 562;
BA_REL_ "GenSigTimeoutTime" BU_SG_REL_ ICCM_OBD_HS SG_ 562 ExhstPerfMdRq 250;
BA_REL_ "GenSigSuprvResp" BU_SG_REL_ ICCM_HS SG_ 562 ExhstPerfMdRq 1;
BA_REL_ "GenSigTimeoutMsg" BU_SG_REL_ ICCM_HS SG_ 562 ExhstPerfMdRq 562;
BA_REL_ "GenSigTimeoutTime" BU_SG_REL_ ICCM_HS SG_ 562 ExhstPerfMdRq 250;
BA_REL_ "GenSigSuprvResp" BU_SG_REL_ SADS_HS SG_ 562 DrvMdCntrlState 1;
BA_REL_ "GenSigTimeoutMsg" BU_SG_REL_ SADS_HS SG_ 562 DrvMdCntrlState 562;
BA_REL_ "GenSigTimeoutTime" BU_SG_REL_ SADS_HS SG_ 562 DrvMdCntrlState 250;
BA_REL_ "GenSigSuprvResp" BU_SG_REL_ RDCM_HS SG_ 562 AWDPerfMdRq 1;
BA_REL_ "GenSigTimeoutMsg" BU_SG_REL_ RDCM_HS SG_ 562 AWDPerfMdRq 562;
BA_REL_ "GenSigTimeoutTime" BU_SG_REL_ RDCM_HS SG_ 562 AWDPerfMdRq 250;
BA_REL_ "GenSigSuprvResp" BU_SG_REL_ TCCM_HS SG_ 562 AWDPerfMdRq 1;
BA_REL_ "GenSigTimeoutMsg" BU_SG_REL_ TCCM_HS SG_ 562 AWDPerfMdRq 562;
BA_REL_ "GenSigTimeoutTime" BU_SG_REL_ TCCM_HS SG_ 562 AWDPerfMdRq 250;
BA_REL_ "GenSigSuprvResp" BU_SG_REL_ ICCM_OBD_HS SG_ 532 RedntVSEActARC 1;
BA_REL_ "GenSigTimeoutMsg" BU_SG_REL_ ICCM_OBD_HS SG_ 532 RedntVSEActARC 532;
BA_REL_ "GenSigTimeoutTime" BU_SG_REL_ ICCM_OBD_HS SG_ 532 RedntVSEActARC 250;
BA_REL_ "GenSigSuprvResp" BU_SG_REL_ ICCM_HS SG_ 532 RedntVSEActARC 1;
BA_REL_ "GenSigTimeoutMsg" BU_SG_REL_ ICCM_HS SG_ 532 RedntVSEActARC 532;
BA_REL_ "GenSigTimeoutTime" BU_SG_REL_ ICCM_HS SG_ 532 RedntVSEActARC 250;
BA_REL_ "GenSigSuprvResp" BU_SG_REL_ ICCM_OBD_HS SG_ 532 RedntVSEAct 1;
BA_REL_ "GenSigTimeoutMsg" BU_SG_REL_ ICCM_OBD_HS SG_ 532 RedntVSEAct 532;
BA_REL_ "GenSigTimeoutTime" BU_SG_REL_ ICCM_OBD_HS SG_ 532 RedntVSEAct 250;
BA_REL_ "GenSigSuprvResp" BU_SG_REL_ ICCM_HS SG_ 532 RedntVSEAct 1;
BA_REL_ "GenSigTimeoutMsg" BU_SG_REL_ ICCM_HS SG_ 532 RedntVSEAct 532;
BA_REL_ "GenSigTimeoutTime" BU_SG_REL_ ICCM_HS SG_ 532 RedntVSEAct 250;
BA_REL_ "GenSigSuprvResp" BU_SG_REL_ ICCM_OBD_HS SG_ 532 AutoBrkngActARC 1;
BA_REL_ "GenSigTimeoutMsg" BU_SG_REL_ ICCM_OBD_HS SG_ 532 AutoBrkngActARC 532;
BA_REL_ "GenSigTimeoutTime" BU_SG_REL_ ICCM_OBD_HS SG_ 532 AutoBrkngActARC 250;
BA_REL_ "GenSigSuprvResp" BU_SG_REL_ ICCM_HS SG_ 532 AutoBrkngActARC 1;
BA_REL_ "GenSigTimeoutMsg" BU_SG_REL_ ICCM_HS SG_ 532 AutoBrkngActARC 532;
BA_REL_ "GenSigTimeoutTime" BU_SG_REL_ ICCM_HS SG_ 532 AutoBrkngActARC 250;
BA_REL_ "GenSigSuprvResp" BU_SG_REL_ ICCM_OBD_HS SG_ 532 ABSActvProtPVal 1;
BA_REL_ "GenSigTimeoutMsg" BU_SG_REL_ ICCM_OBD_HS SG_ 532 ABSActvProtPVal 532;
BA_REL_ "GenSigTimeoutTime" BU_SG_REL_ ICCM_OBD_HS SG_ 532 ABSActvProtPVal 125;
BA_REL_ "GenSigSuprvResp" BU_SG_REL_ ICCM_HS SG_ 532 ABSActvProtPVal 1;
BA_REL_ "GenSigTimeoutMsg" BU_SG_REL_ ICCM_HS SG_ 532 ABSActvProtPVal 532;
BA_REL_ "GenSigTimeoutTime" BU_SG_REL_ ICCM_HS SG_ 532 ABSActvProtPVal 125;
BA_REL_ "GenSigSuprvResp" BU_SG_REL_ ICCM_OBD_HS SG_ 532 ABSActvProtARC 1;
BA_REL_ "GenSigTimeoutMsg" BU_SG_REL_ ICCM_OBD_HS SG_ 532 ABSActvProtARC 532;
BA_REL_ "GenSigTimeoutTime" BU_SG_REL_ ICCM_OBD_HS SG_ 532 ABSActvProtARC 125;
BA_REL_ "GenSigSuprvResp" BU_SG_REL_ ICCM_HS SG_ 532 ABSActvProtARC 1;
BA_REL_ "GenSigTimeoutMsg" BU_SG_REL_ ICCM_HS SG_ 532 ABSActvProtARC 532;
BA_REL_ "GenSigTimeoutTime" BU_SG_REL_ ICCM_HS SG_ 532 ABSActvProtARC 125;
BA_REL_ "GenSigSuprvResp" BU_SG_REL_ ICCM_OBD_HS SG_ 532 ABSActvProt 1;
BA_REL_ "GenSigTimeoutMsg" BU_SG_REL_ ICCM_OBD_HS SG_ 532 ABSActvProt 532;
BA_REL_ "GenSigTimeoutTime" BU_SG_REL_ ICCM_OBD_HS SG_ 532 ABSActvProt 125;
BA_REL_ "GenSigSuprvResp" BU_SG_REL_ ICCM_HS SG_ 532 ABSActvProt 1;
BA_REL_ "GenSigTimeoutMsg" BU_SG_REL_ ICCM_HS SG_ 532 ABSActvProt 532;
BA_REL_ "GenSigTimeoutTime" BU_SG_REL_ ICCM_HS SG_ 532 ABSActvProt 125;
BA_REL_ "GenSigSuprvResp" BU_SG_REL_ EPB_HS SG_ 532 BrkSysAutBrkFld 1;
BA_REL_ "GenSigTimeoutMsg" BU_SG_REL_ EPB_HS SG_ 532 BrkSysAutBrkFld 532;
BA_REL_ "GenSigTimeoutTime" BU_SG_REL_ EPB_HS SG_ 532 BrkSysAutBrkFld 250;
BA_REL_ "GenSigSuprvResp" BU_SG_REL_ ACC_HS SG_ 532 BrkSysAutBrkFld 1;
BA_REL_ "GenSigTimeoutMsg" BU_SG_REL_ ACC_HS SG_ 532 BrkSysAutBrkFld 532;
BA_REL_ "GenSigTimeoutTime" BU_SG_REL_ ACC_HS SG_ 532 BrkSysAutBrkFld 250;
BA_REL_ "GenSigSuprvResp" BU_SG_REL_ BCM_HS SG_ 532 BrkSysMalFuncIndOn 1;
BA_REL_ "GenSigTimeoutMsg" BU_SG_REL_ BCM_HS SG_ 532 BrkSysMalFuncIndOn 532;
BA_REL_ "GenSigTimeoutTime" BU_SG_REL_ BCM_HS SG_ 532 BrkSysMalFuncIndOn 300;
BA_REL_ "GenSigSuprvResp" BU_SG_REL_ FSCM_ITBC_HS SG_ 532 BPDAPS_BkPDrvApPV 1;
BA_REL_ "GenSigTimeoutMsg" BU_SG_REL_ FSCM_ITBC_HS SG_ 532 BPDAPS_BkPDrvApPV 532;
BA_REL_ "GenSigTimeoutTime" BU_SG_REL_ FSCM_ITBC_HS SG_ 532 BPDAPS_BkPDrvApPV 250;
BA_REL_ "GenSigSuprvResp" BU_SG_REL_ ACC_HS SG_ 532 BPDAPS_BkPDrvApPV 1;
BA_REL_ "GenSigTimeoutMsg" BU_SG_REL_ ACC_HS SG_ 532 BPDAPS_BkPDrvApPV 532;
BA_REL_ "GenSigTimeoutTime" BU_SG_REL_ ACC_HS SG_ 532 BPDAPS_BkPDrvApPV 250;
BA_REL_ "GenSigSuprvResp" BU_SG_REL_ SADS_HS SG_ 532 BPDAPS_BkPDrvApPV 1;
BA_REL_ "GenSigTimeoutMsg" BU_SG_REL_ SADS_HS SG_ 532 BPDAPS_BkPDrvApPV 532;
BA_REL_ "GenSigTimeoutTime" BU_SG_REL_ SADS_HS SG_ 532 BPDAPS_BkPDrvApPV 250;
BA_REL_ "GenSigSuprvResp" BU_SG_REL_ EPB_HS SG_ 532 BPDAPS_BkPDrvApPV 1;
BA_REL_ "GenSigTimeoutMsg" BU_SG_REL_ EPB_HS SG_ 532 BPDAPS_BkPDrvApPV 532;
BA_REL_ "GenSigTimeoutTime" BU_SG_REL_ EPB_HS SG_ 532 BPDAPS_BkPDrvApPV 250;
BA_REL_ "GenSigSuprvResp" BU_SG_REL_ EPB_HS SG_ 532 BPDAPS_BkPDrvApPV 1;
BA_REL_ "GenSigTimeoutMsg" BU_SG_REL_ EPB_HS SG_ 532 BPDAPS_BkPDrvApPV 532;
BA_REL_ "GenSigTimeoutTime" BU_SG_REL_ EPB_HS SG_ 532 BPDAPS_BkPDrvApPV 250;
BA_REL_ "GenSigSuprvResp" BU_SG_REL_ FSCM_ITBC_HS SG_ 532 BPDAPS_BkPDrvApP 1;
BA_REL_ "GenSigTimeoutMsg" BU_SG_REL_ FSCM_ITBC_HS SG_ 532 BPDAPS_BkPDrvApP 532;
BA_REL_ "GenSigTimeoutTime" BU_SG_REL_ FSCM_ITBC_HS SG_ 532 BPDAPS_BkPDrvApP 250;
BA_REL_ "GenSigSuprvResp" BU_SG_REL_ ACC_HS SG_ 532 BPDAPS_BkPDrvApP 1;
BA_REL_ "GenSigTimeoutMsg" BU_SG_REL_ ACC_HS SG_ 532 BPDAPS_BkPDrvApP 532;
BA_REL_ "GenSigTimeoutTime" BU_SG_REL_ ACC_HS SG_ 532 BPDAPS_BkPDrvApP 250;
BA_REL_ "GenSigSuprvResp" BU_SG_REL_ SADS_HS SG_ 532 BPDAPS_BkPDrvApP 1;
BA_REL_ "GenSigTimeoutMsg" BU_SG_REL_ SADS_HS SG_ 532 BPDAPS_BkPDrvApP 532;
BA_REL_ "GenSigTimeoutTime" BU_SG_REL_ SADS_HS SG_ 532 BPDAPS_BkPDrvApP 250;
BA_REL_ "GenSigSuprvResp" BU_SG_REL_ EPB_HS SG_ 532 BPDAPS_BkPDrvApP 1;
BA_REL_ "GenSigTimeoutMsg" BU_SG_REL_ EPB_HS SG_ 532 BPDAPS_BkPDrvApP 532;
BA_REL_ "GenSigTimeoutTime" BU_SG_REL_ EPB_HS SG_ 532 BPDAPS_BkPDrvApP 250;
BA_REL_ "GenSigSuprvResp" BU_SG_REL_ EPB_HS SG_ 532 BPDAPS_BkPDrvApP 1;
BA_REL_ "GenSigTimeoutMsg" BU_SG_REL_ EPB_HS SG_ 532 BPDAPS_BkPDrvApP 532;
BA_REL_ "GenSigTimeoutTime" BU_SG_REL_ EPB_HS SG_ 532 BPDAPS_BkPDrvApP 250;
BA_REL_ "GenSigSuprvResp" BU_SG_REL_ EOCM_F_HS SG_ 532 BrkPdDrvAppPrsAlRC 1;
BA_REL_ "GenSigTimeoutMsg" BU_SG_REL_ EOCM_F_HS SG_ 532 BrkPdDrvAppPrsAlRC 532;
BA_REL_ "GenSigTimeoutTime" BU_SG_REL_ EOCM_F_HS SG_ 532 BrkPdDrvAppPrsAlRC 120;
BA_REL_ "GenSigSuprvResp" BU_SG_REL_ ICCM_OBD_HS SG_ 532 AutoBrkngAct 1;
BA_REL_ "GenSigTimeoutMsg" BU_SG_REL_ ICCM_OBD_HS SG_ 532 AutoBrkngAct 532;
BA_REL_ "GenSigTimeoutTime" BU_SG_REL_ ICCM_OBD_HS SG_ 532 AutoBrkngAct 250;
BA_REL_ "GenSigSuprvResp" BU_SG_REL_ ICCM_HS SG_ 532 AutoBrkngAct 1;
BA_REL_ "GenSigTimeoutMsg" BU_SG_REL_ ICCM_HS SG_ 532 AutoBrkngAct 532;
BA_REL_ "GenSigTimeoutTime" BU_SG_REL_ ICCM_HS SG_ 532 AutoBrkngAct 250;
BA_REL_ "GenSigSuprvResp" BU_SG_REL_ EPB_HS SG_ 532 AutoBrkngAct 1;
BA_REL_ "GenSigTimeoutMsg" BU_SG_REL_ EPB_HS SG_ 532 AutoBrkngAct 532;
BA_REL_ "GenSigTimeoutTime" BU_SG_REL_ EPB_HS SG_ 532 AutoBrkngAct 250;
BA_REL_ "GenSigSuprvResp" BU_SG_REL_ ACC_HS SG_ 532 AutoBrkngAct 1;
BA_REL_ "GenSigTimeoutMsg" BU_SG_REL_ ACC_HS SG_ 532 AutoBrkngAct 532;
BA_REL_ "GenSigTimeoutTime" BU_SG_REL_ ACC_HS SG_ 532 AutoBrkngAct 250;
BA_REL_ "GenSigVBitResp" BU_SG_REL_ BCM_HS SG_ 532 BrkFldLvlLw 1;
BA_REL_ "GenSigSuprvResp" BU_SG_REL_ BCM_HS SG_ 532 BrkFldLvlLw 1;
BA_REL_ "GenSigTimeoutMsg" BU_SG_REL_ BCM_HS SG_ 532 BrkFldLvlLw 532;
BA_REL_ "GenSigTimeoutTime" BU_SG_REL_ BCM_HS SG_ 532 BrkFldLvlLw 300;
BA_REL_ "GenSigSuprvResp" BU_SG_REL_ BCM_HS SG_ 328 StrngAsstRdcdIO 1;
BA_REL_ "GenSigTimeoutMsg" BU_SG_REL_ BCM_HS SG_ 328 StrngAsstRdcdIO 328;
BA_REL_ "GenSigTimeoutTime" BU_SG_REL_ BCM_HS SG_ 328 StrngAsstRdcdIO 2500;
BA_REL_ "GenSigSuprvResp" BU_SG_REL_ BCM_HS SG_ 328 PwrStrIO 1;
BA_REL_ "GenSigTimeoutMsg" BU_SG_REL_ BCM_HS SG_ 328 PwrStrIO 328;
BA_REL_ "GenSigTimeoutTime" BU_SG_REL_ BCM_HS SG_ 328 PwrStrIO 2500;
BA_REL_ "GenSigSuprvResp" BU_SG_REL_ BCM_HS SG_ 560 AllNodesVNA 1;
BA_REL_ "GenSigTimeoutMsg" BU_SG_REL_ BCM_HS SG_ 560 AllNodesVNA 560;
BA_REL_ "GenSigTimeoutTime" BU_SG_REL_ BCM_HS SG_ 560 AllNodesVNA 250;
BA_REL_ "GenSigSuprvResp" BU_SG_REL_ BCM_HS SG_ 560 StpOnBrkToRelPBIndOn 1;
BA_REL_ "GenSigTimeoutMsg" BU_SG_REL_ BCM_HS SG_ 560 StpOnBrkToRelPBIndOn 560;
BA_REL_ "GenSigTimeoutTime" BU_SG_REL_ BCM_HS SG_ 560 StpOnBrkToRelPBIndOn 250;
BA_REL_ "GenSigSuprvResp" BU_SG_REL_ BCM_HS SG_ 560 EPBSysDspMsgReq 1;
BA_REL_ "GenSigTimeoutMsg" BU_SG_REL_ BCM_HS SG_ 560 EPBSysDspMsgReq 560;
BA_REL_ "GenSigTimeoutTime" BU_SG_REL_ BCM_HS SG_ 560 EPBSysDspMsgReq 250;
BA_REL_ "GenSigSuprvResp" BU_SG_REL_ BCM_HS SG_ 560 EPBSysAudWarnReq 1;
BA_REL_ "GenSigTimeoutMsg" BU_SG_REL_ BCM_HS SG_ 560 EPBSysAudWarnReq 560;
BA_REL_ "GenSigTimeoutTime" BU_SG_REL_ BCM_HS SG_ 560 EPBSysAudWarnReq 250;
BA_REL_ "GenSigSuprvResp" BU_SG_REL_ ACC_HS SG_ 560 ElecPrkBrkStat 1;
BA_REL_ "GenSigTimeoutMsg" BU_SG_REL_ ACC_HS SG_ 560 ElecPrkBrkStat 560;
BA_REL_ "GenSigTimeoutTime" BU_SG_REL_ ACC_HS SG_ 560 ElecPrkBrkStat 125;
BA_REL_ "GenSigSuprvResp" BU_SG_REL_ EOCM_F_HS SG_ 560 ElecPrkBrkStat 1;
BA_REL_ "GenSigTimeoutMsg" BU_SG_REL_ EOCM_F_HS SG_ 560 ElecPrkBrkStat 560;
BA_REL_ "GenSigTimeoutTime" BU_SG_REL_ EOCM_F_HS SG_ 560 ElecPrkBrkStat 160;
BA_REL_ "GenSigSuprvResp" BU_SG_REL_ EOCM_F_HS SG_ 560 ElecPrkBrkStat 1;
BA_REL_ "GenSigTimeoutMsg" BU_SG_REL_ EOCM_F_HS SG_ 560 ElecPrkBrkStat 560;
BA_REL_ "GenSigTimeoutTime" BU_SG_REL_ EOCM_F_HS SG_ 560 ElecPrkBrkStat 160;
BA_REL_ "GenSigSuprvResp" BU_SG_REL_ BCM_HS SG_ 560 ElecPrkBrkStat 1;
BA_REL_ "GenSigTimeoutMsg" BU_SG_REL_ BCM_HS SG_ 560 ElecPrkBrkStat 560;
BA_REL_ "GenSigTimeoutTime" BU_SG_REL_ BCM_HS SG_ 560 ElecPrkBrkStat 250;
BA_REL_ "GenSigSuprvResp" BU_SG_REL_ RDCM_HS SG_ 560 ElecPrkBrkStat 1;
BA_REL_ "GenSigTimeoutMsg" BU_SG_REL_ RDCM_HS SG_ 560 ElecPrkBrkStat 560;
BA_REL_ "GenSigTimeoutTime" BU_SG_REL_ RDCM_HS SG_ 560 ElecPrkBrkStat 250;
BA_REL_ "GenSigRxStartValue" BU_SG_REL_ ACC_HS SG_ 560 EPBCrsCanRq "0";
BA_REL_ "GenSigSuprvResp" BU_SG_REL_ ACC_HS SG_ 560 EPBCrsCanRq 1;
BA_REL_ "GenSigTimeoutMsg" BU_SG_REL_ ACC_HS SG_ 560 EPBCrsCanRq 560;
BA_REL_ "GenSigTimeoutTime" BU_SG_REL_ ACC_HS SG_ 560 EPBCrsCanRq 125;
BA_REL_ "GenSigSuprvResp" BU_SG_REL_ EOCM_F_HS SG_ 560 EPBCrsCanRq 1;
BA_REL_ "GenSigTimeoutMsg" BU_SG_REL_ EOCM_F_HS SG_ 560 EPBCrsCanRq 560;
BA_REL_ "GenSigTimeoutTime" BU_SG_REL_ EOCM_F_HS SG_ 560 EPBCrsCanRq 160;
BA_REL_ "GenSigSuprvResp" BU_SG_REL_ BCM_HS SG_ 560 EPBSysBrkLtsReq 1;
BA_REL_ "GenSigTimeoutMsg" BU_SG_REL_ BCM_HS SG_ 560 EPBSysBrkLtsReq 560;
BA_REL_ "GenSigTimeoutTime" BU_SG_REL_ BCM_HS SG_ 560 EPBSysBrkLtsReq 250;
BA_REL_ "GenSigSuprvResp" BU_SG_REL_ BCM_HS SG_ 383 StSysVehTopSpdLimReq 1;
BA_REL_ "GenSigTimeoutMsg" BU_SG_REL_ BCM_HS SG_ 383 StSysVehTopSpdLimReq 383;
BA_REL_ "GenSigTimeoutTime" BU_SG_REL_ BCM_HS SG_ 383 StSysVehTopSpdLimReq 250;
BA_REL_ "GenSigSuprvResp" BU_SG_REL_ BCM_HS SG_ 383 FrStSysVeTpSpLimIndOn 1;
BA_REL_ "GenSigTimeoutMsg" BU_SG_REL_ BCM_HS SG_ 383 FrStSysVeTpSpLimIndOn 383;
BA_REL_ "GenSigTimeoutTime" BU_SG_REL_ BCM_HS SG_ 383 FrStSysVeTpSpLimIndOn 250;
BA_REL_ "GenSigSuprvResp" BU_SG_REL_ BCM_HS SG_ 451 GlwPlgCrnkDelAct 1;
BA_REL_ "GenSigTimeoutMsg" BU_SG_REL_ BCM_HS SG_ 451 GlwPlgCrnkDelAct 451;
BA_REL_ "GenSigTimeoutTime" BU_SG_REL_ BCM_HS SG_ 451 GlwPlgCrnkDelAct 250;
BA_REL_ "GenSigSuprvResp" BU_SG_REL_ PTO_HS SG_ 451 PltfrmEngSpdCmmndSt 1;
BA_REL_ "GenSigTimeoutMsg" BU_SG_REL_ PTO_HS SG_ 451 PltfrmEngSpdCmmndSt 451;
BA_REL_ "GenSigTimeoutTime" BU_SG_REL_ PTO_HS SG_ 451 PltfrmEngSpdCmmndSt 250;
BA_REL_ "GenSigSuprvResp" BU_SG_REL_ ICCM_OBD_HS SG_ 451 AccPos 1;
BA_REL_ "GenSigTimeoutMsg" BU_SG_REL_ ICCM_OBD_HS SG_ 451 AccPos 451;
BA_REL_ "GenSigTimeoutTime" BU_SG_REL_ ICCM_OBD_HS SG_ 451 AccPos 250;
BA_REL_ "GenSigSuprvResp" BU_SG_REL_ ICCM_HS SG_ 451 AccPos 1;
BA_REL_ "GenSigTimeoutMsg" BU_SG_REL_ ICCM_HS SG_ 451 AccPos 451;
BA_REL_ "GenSigTimeoutTime" BU_SG_REL_ ICCM_HS SG_ 451 AccPos 250;
BA_REL_ "GenSigSuprvResp" BU_SG_REL_ FSCM_ITBC_HS SG_ 451 AccPos 1;
BA_REL_ "GenSigTimeoutMsg" BU_SG_REL_ FSCM_ITBC_HS SG_ 451 AccPos 451;
BA_REL_ "GenSigTimeoutTime" BU_SG_REL_ FSCM_ITBC_HS SG_ 451 AccPos 250;
BA_REL_ "GenSigSuprvResp" BU_SG_REL_ FSCM_HS SG_ 451 AccPos 1;
BA_REL_ "GenSigTimeoutMsg" BU_SG_REL_ FSCM_HS SG_ 451 AccPos 451;
BA_REL_ "GenSigTimeoutTime" BU_SG_REL_ FSCM_HS SG_ 451 AccPos 250;
BA_REL_ "GenSigSuprvResp" BU_SG_REL_ EOCM_F_HS SG_ 451 AccPos 2;
BA_REL_ "GenSigTimeoutMsg" BU_SG_REL_ EOCM_F_HS SG_ 451 AccPos 451;
BA_REL_ "GenSigTimeoutTime" BU_SG_REL_ EOCM_F_HS SG_ 451 AccPos 120;
BA_REL_ "GenSigSuprvResp" BU_SG_REL_ VICM_HS SG_ 451 AccPos 1;
BA_REL_ "GenSigTimeoutMsg" BU_SG_REL_ VICM_HS SG_ 451 AccPos 451;
BA_REL_ "GenSigTimeoutTime" BU_SG_REL_ VICM_HS SG_ 451 AccPos 250;
BA_REL_ "GenSigSuprvResp" BU_SG_REL_ VICM_HS SG_ 451 AccPos 1;
BA_REL_ "GenSigTimeoutMsg" BU_SG_REL_ VICM_HS SG_ 451 AccPos 451;
BA_REL_ "GenSigTimeoutTime" BU_SG_REL_ VICM_HS SG_ 451 AccPos 250;
BA_REL_ "GenSigSuprvResp" BU_SG_REL_ TCCM_HS SG_ 451 AccPos 1;
BA_REL_ "GenSigTimeoutMsg" BU_SG_REL_ TCCM_HS SG_ 451 AccPos 451;
BA_REL_ "GenSigTimeoutTime" BU_SG_REL_ TCCM_HS SG_ 451 AccPos 250;
BA_REL_ "GenSigSuprvResp" BU_SG_REL_ LVMPC_HS SG_ 451 EngTrqDrRqdExtRng 1;
BA_REL_ "GenSigTimeoutMsg" BU_SG_REL_ LVMPC_HS SG_ 451 EngTrqDrRqdExtRng 451;
BA_REL_ "GenSigTimeoutTime" BU_SG_REL_ LVMPC_HS SG_ 451 EngTrqDrRqdExtRng 250;
BA_REL_ "GenSigSuprvResp" BU_SG_REL_ BCM_HS SG_ 451 EngTrqDrRqdExtRng 1;
BA_REL_ "GenSigTimeoutMsg" BU_SG_REL_ BCM_HS SG_ 451 EngTrqDrRqdExtRng 451;
BA_REL_ "GenSigTimeoutTime" BU_SG_REL_ BCM_HS SG_ 451 EngTrqDrRqdExtRng 250;
BA_REL_ "GenSigSuprvResp" BU_SG_REL_ ACC_HS SG_ 451 EngTrqDrRqdExtRng 1;
BA_REL_ "GenSigTimeoutMsg" BU_SG_REL_ ACC_HS SG_ 451 EngTrqDrRqdExtRng 451;
BA_REL_ "GenSigTimeoutTime" BU_SG_REL_ ACC_HS SG_ 451 EngTrqDrRqdExtRng 250;
BA_REL_ "GenSigSuprvResp" BU_SG_REL_ ICCM_OBD_HS SG_ 451 EngTrqActExtRng 1;
BA_REL_ "GenSigTimeoutMsg" BU_SG_REL_ ICCM_OBD_HS SG_ 451 EngTrqActExtRng 451;
BA_REL_ "GenSigTimeoutTime" BU_SG_REL_ ICCM_OBD_HS SG_ 451 EngTrqActExtRng 250;
BA_REL_ "GenSigSuprvResp" BU_SG_REL_ ICCM_HS SG_ 451 EngTrqActExtRng 1;
BA_REL_ "GenSigTimeoutMsg" BU_SG_REL_ ICCM_HS SG_ 451 EngTrqActExtRng 451;
BA_REL_ "GenSigTimeoutTime" BU_SG_REL_ ICCM_HS SG_ 451 EngTrqActExtRng 250;
BA_REL_ "GenSigSuprvResp" BU_SG_REL_ FSCM_ITBC_HS SG_ 451 EngTrqActExtRng 1;
BA_REL_ "GenSigTimeoutMsg" BU_SG_REL_ FSCM_ITBC_HS SG_ 451 EngTrqActExtRng 451;
BA_REL_ "GenSigTimeoutTime" BU_SG_REL_ FSCM_ITBC_HS SG_ 451 EngTrqActExtRng 250;
BA_REL_ "GenSigSuprvResp" BU_SG_REL_ FSCM_HS SG_ 451 EngTrqActExtRng 1;
BA_REL_ "GenSigTimeoutMsg" BU_SG_REL_ FSCM_HS SG_ 451 EngTrqActExtRng 451;
BA_REL_ "GenSigTimeoutTime" BU_SG_REL_ FSCM_HS SG_ 451 EngTrqActExtRng 250;
BA_REL_ "GenSigSuprvResp" BU_SG_REL_ PTO_HS SG_ 451 EngTrqActExtRng 1;
BA_REL_ "GenSigTimeoutMsg" BU_SG_REL_ PTO_HS SG_ 451 EngTrqActExtRng 451;
BA_REL_ "GenSigTimeoutTime" BU_SG_REL_ PTO_HS SG_ 451 EngTrqActExtRng 250;
BA_REL_ "GenSigSuprvResp" BU_SG_REL_ AMP_HS SG_ 451 EngTrqActExtRng 1;
BA_REL_ "GenSigTimeoutMsg" BU_SG_REL_ AMP_HS SG_ 451 EngTrqActExtRng 451;
BA_REL_ "GenSigTimeoutTime" BU_SG_REL_ AMP_HS SG_ 451 EngTrqActExtRng 250;
BA_REL_ "GenSigSuprvResp" BU_SG_REL_ ACC_HS SG_ 451 EngTrqActExtRng 1;
BA_REL_ "GenSigTimeoutMsg" BU_SG_REL_ ACC_HS SG_ 451 EngTrqActExtRng 451;
BA_REL_ "GenSigTimeoutTime" BU_SG_REL_ ACC_HS SG_ 451 EngTrqActExtRng 250;
BA_REL_ "GenSigSuprvResp" BU_SG_REL_ EPB_HS SG_ 451 EngTrqActExtRng 1;
BA_REL_ "GenSigTimeoutMsg" BU_SG_REL_ EPB_HS SG_ 451 EngTrqActExtRng 451;
BA_REL_ "GenSigTimeoutTime" BU_SG_REL_ EPB_HS SG_ 451 EngTrqActExtRng 250;
BA_REL_ "GenSigVBitResp" BU_SG_REL_ BCM_HS SG_ 451 EngTrqActExtRng 1;
BA_REL_ "GenSigSuprvResp" BU_SG_REL_ BCM_HS SG_ 451 EngTrqActExtRng 1;
BA_REL_ "GenSigTimeoutMsg" BU_SG_REL_ BCM_HS SG_ 451 EngTrqActExtRng 451;
BA_REL_ "GenSigTimeoutTime" BU_SG_REL_ BCM_HS SG_ 451 EngTrqActExtRng 250;
BA_REL_ "GenSigRxStartValue" BU_SG_REL_ RDCM_HS SG_ 451 EngTrqActExtRng "$6A0 (0 converted)";
BA_REL_ "GenSigSuprvResp" BU_SG_REL_ RDCM_HS SG_ 451 EngTrqActExtRng 1;
BA_REL_ "GenSigTimeoutMsg" BU_SG_REL_ RDCM_HS SG_ 451 EngTrqActExtRng 451;
BA_REL_ "GenSigTimeoutTime" BU_SG_REL_ RDCM_HS SG_ 451 EngTrqActExtRng 250;
BA_REL_ "GenSigSuprvResp" BU_SG_REL_ EBCM_OBD_HS SG_ 451 EngTrqActExtRng 1;
BA_REL_ "GenSigTimeoutMsg" BU_SG_REL_ EBCM_OBD_HS SG_ 451 EngTrqActExtRng 451;
BA_REL_ "GenSigTimeoutTime" BU_SG_REL_ EBCM_OBD_HS SG_ 451 EngTrqActExtRng 63;
BA_REL_ "GenSigSuprvResp" BU_SG_REL_ EBCM_HS SG_ 451 EngTrqActExtRng 1;
BA_REL_ "GenSigTimeoutMsg" BU_SG_REL_ EBCM_HS SG_ 451 EngTrqActExtRng 451;
BA_REL_ "GenSigTimeoutTime" BU_SG_REL_ EBCM_HS SG_ 451 EngTrqActExtRng 63;
BA_REL_ "GenSigSuprvResp" BU_SG_REL_ SADS_HS SG_ 451 EngTrqActExtRng 1;
BA_REL_ "GenSigTimeoutMsg" BU_SG_REL_ SADS_HS SG_ 451 EngTrqActExtRng 451;
BA_REL_ "GenSigTimeoutTime" BU_SG_REL_ SADS_HS SG_ 451 EngTrqActExtRng 63;
BA_REL_ "GenSigSuprvResp" BU_SG_REL_ AHL_AFL_HS SG_ 801 WBRP_ARC 1;
BA_REL_ "GenSigTimeoutMsg" BU_SG_REL_ AHL_AFL_HS SG_ 801 WBRP_ARC 801;
BA_REL_ "GenSigTimeoutTime" BU_SG_REL_ AHL_AFL_HS SG_ 801 WBRP_ARC 250;
BA_REL_ "GenSigSuprvResp" BU_SG_REL_ AHL_AFL_HS SG_ 801 WBRP_Tmestmp 1;
BA_REL_ "GenSigTimeoutMsg" BU_SG_REL_ AHL_AFL_HS SG_ 801 WBRP_Tmestmp 801;
BA_REL_ "GenSigTimeoutTime" BU_SG_REL_ AHL_AFL_HS SG_ 801 WBRP_Tmestmp 250;
BA_REL_ "GenSigSuprvResp" BU_SG_REL_ AHL_AFL_HS SG_ 801 WBRP_RtFrtV 1;
BA_REL_ "GenSigTimeoutMsg" BU_SG_REL_ AHL_AFL_HS SG_ 801 WBRP_RtFrtV 801;
BA_REL_ "GenSigTimeoutTime" BU_SG_REL_ AHL_AFL_HS SG_ 801 WBRP_RtFrtV 250;
BA_REL_ "GenSigSuprvResp" BU_SG_REL_ AHL_AFL_HS SG_ 801 WBRP_RtFrt 1;
BA_REL_ "GenSigTimeoutMsg" BU_SG_REL_ AHL_AFL_HS SG_ 801 WBRP_RtFrt 801;
BA_REL_ "GenSigTimeoutTime" BU_SG_REL_ AHL_AFL_HS SG_ 801 WBRP_RtFrt 250;
BA_REL_ "GenSigSuprvResp" BU_SG_REL_ AHL_AFL_HS SG_ 801 WBRP_RtRrV 1;
BA_REL_ "GenSigTimeoutMsg" BU_SG_REL_ AHL_AFL_HS SG_ 801 WBRP_RtRrV 801;
BA_REL_ "GenSigTimeoutTime" BU_SG_REL_ AHL_AFL_HS SG_ 801 WBRP_RtRrV 250;
BA_REL_ "GenSigSuprvResp" BU_SG_REL_ AHL_AFL_HS SG_ 801 WBRP_RtRr 1;
BA_REL_ "GenSigTimeoutMsg" BU_SG_REL_ AHL_AFL_HS SG_ 801 WBRP_RtRr 801;
BA_REL_ "GenSigTimeoutTime" BU_SG_REL_ AHL_AFL_HS SG_ 801 WBRP_RtRr 250;
BA_REL_ "GenSigSuprvResp" BU_SG_REL_ AHL_AFL_HS SG_ 801 WBRP_LftRrV 1;
BA_REL_ "GenSigTimeoutMsg" BU_SG_REL_ AHL_AFL_HS SG_ 801 WBRP_LftRrV 801;
BA_REL_ "GenSigTimeoutTime" BU_SG_REL_ AHL_AFL_HS SG_ 801 WBRP_LftRrV 250;
BA_REL_ "GenSigSuprvResp" BU_SG_REL_ AHL_AFL_HS SG_ 801 WBRP_LftRr 1;
BA_REL_ "GenSigTimeoutMsg" BU_SG_REL_ AHL_AFL_HS SG_ 801 WBRP_LftRr 801;
BA_REL_ "GenSigTimeoutTime" BU_SG_REL_ AHL_AFL_HS SG_ 801 WBRP_LftRr 250;
BA_REL_ "GenSigSuprvResp" BU_SG_REL_ AHL_AFL_HS SG_ 801 WBRP_LftFrtV 1;
BA_REL_ "GenSigTimeoutMsg" BU_SG_REL_ AHL_AFL_HS SG_ 801 WBRP_LftFrtV 801;
BA_REL_ "GenSigTimeoutTime" BU_SG_REL_ AHL_AFL_HS SG_ 801 WBRP_LftFrtV 250;
BA_REL_ "GenSigSuprvResp" BU_SG_REL_ AHL_AFL_HS SG_ 801 WBRP_LftFrt 1;
BA_REL_ "GenSigTimeoutMsg" BU_SG_REL_ AHL_AFL_HS SG_ 801 WBRP_LftFrt 801;
BA_REL_ "GenSigTimeoutTime" BU_SG_REL_ AHL_AFL_HS SG_ 801 WBRP_LftFrt 250;
BA_REL_ "GenSigSuprvResp" BU_SG_REL_ AHL_AFL_HS SG_ 320 BrkLtsAtv 1;
BA_REL_ "GenSigTimeoutMsg" BU_SG_REL_ AHL_AFL_HS SG_ 320 BrkLtsAtv 320;
BA_REL_ "GenSigTimeoutTime" BU_SG_REL_ AHL_AFL_HS SG_ 320 BrkLtsAtv 2500;
BA_REL_ "GenSigSuprvResp" BU_SG_REL_ EOCM_F_HS SG_ 320 BrkLtsAtv 1;
BA_REL_ "GenSigTimeoutMsg" BU_SG_REL_ EOCM_F_HS SG_ 320 BrkLtsAtv 320;
BA_REL_ "GenSigTimeoutTime" BU_SG_REL_ EOCM_F_HS SG_ 320 BrkLtsAtv 2500;
BA_REL_ "GenSigSuprvResp" BU_SG_REL_ EOCM_F_HS SG_ 320 BrkLtsAtv 1;
BA_REL_ "GenSigTimeoutTime" BU_SG_REL_ EOCM_F_HS SG_ 320 BrkLtsAtv 2500;
BA_REL_ "GenSigSuprvResp" BU_SG_REL_ EOCM_F_HS SG_ 320 TrnSwAct 1;
BA_REL_ "GenSigTimeoutTime" BU_SG_REL_ EOCM_F_HS SG_ 320 TrnSwAct 2500;
BA_REL_ "GenSigSuprvResp" BU_SG_REL_ EOCM_F_HS SG_ 320 OtsdAmbtLtLvlStat 1;
BA_REL_ "GenSigTimeoutMsg" BU_SG_REL_ EOCM_F_HS SG_ 320 OtsdAmbtLtLvlStat 320;
BA_REL_ "GenSigTimeoutTime" BU_SG_REL_ EOCM_F_HS SG_ 320 OtsdAmbtLtLvlStat 2500;
BA_REL_ "GenSigSuprvResp" BU_SG_REL_ EOCM_F_HS SG_ 320 LowBmAct 2;
BA_REL_ "GenSigTimeoutTime" BU_SG_REL_ EOCM_F_HS SG_ 320 LowBmAct 2500;
BA_REL_ "GenSigSuprvResp" BU_SG_REL_ EOCM_F_HS SG_ 320 HighBmAct 2;
BA_REL_ "GenSigTimeoutTime" BU_SG_REL_ EOCM_F_HS SG_ 320 HighBmAct 2500;
BA_REL_ "GenSigSuprvResp" BU_SG_REL_ AHL_AFL_HS SG_ 320 AdvFrntLghtSysEnbld 1;
BA_REL_ "GenSigTimeoutMsg" BU_SG_REL_ AHL_AFL_HS SG_ 320 AdvFrntLghtSysEnbld 320;
BA_REL_ "GenSigTimeoutTime" BU_SG_REL_ AHL_AFL_HS SG_ 320 AdvFrntLghtSysEnbld 2500;
BA_REL_ "GenSigSuprvResp" BU_SG_REL_ PCM_HS SG_ 957 RdctHtrCStat 1;
BA_REL_ "GenSigTimeoutMsg" BU_SG_REL_ PCM_HS SG_ 957 RdctHtrCStat 957;
BA_REL_ "GenSigTimeoutTime" BU_SG_REL_ PCM_HS SG_ 957 RdctHtrCStat 250;
BA_REL_ "GenSigSuprvResp" BU_SG_REL_ ECM_HS SG_ 957 RdctHtrCStat 1;
BA_REL_ "GenSigTimeoutMsg" BU_SG_REL_ ECM_HS SG_ 957 RdctHtrCStat 957;
BA_REL_ "GenSigTimeoutTime" BU_SG_REL_ ECM_HS SG_ 957 RdctHtrCStat 250;
BA_REL_ "GenSigSuprvResp" BU_SG_REL_ PCM_HS SG_ 957 RdctHtrBStat 1;
BA_REL_ "GenSigTimeoutMsg" BU_SG_REL_ PCM_HS SG_ 957 RdctHtrBStat 957;
BA_REL_ "GenSigTimeoutTime" BU_SG_REL_ PCM_HS SG_ 957 RdctHtrBStat 250;
BA_REL_ "GenSigSuprvResp" BU_SG_REL_ ECM_HS SG_ 957 RdctHtrBStat 1;
BA_REL_ "GenSigTimeoutMsg" BU_SG_REL_ ECM_HS SG_ 957 RdctHtrBStat 957;
BA_REL_ "GenSigTimeoutTime" BU_SG_REL_ ECM_HS SG_ 957 RdctHtrBStat 250;
BA_REL_ "GenSigSuprvResp" BU_SG_REL_ PCM_HS SG_ 957 RdctHtrAStat 1;
BA_REL_ "GenSigTimeoutMsg" BU_SG_REL_ PCM_HS SG_ 957 RdctHtrAStat 957;
BA_REL_ "GenSigTimeoutTime" BU_SG_REL_ PCM_HS SG_ 957 RdctHtrAStat 250;
BA_REL_ "GenSigSuprvResp" BU_SG_REL_ ECM_HS SG_ 957 RdctHtrAStat 1;
BA_REL_ "GenSigTimeoutMsg" BU_SG_REL_ ECM_HS SG_ 957 RdctHtrAStat 957;
BA_REL_ "GenSigTimeoutTime" BU_SG_REL_ ECM_HS SG_ 957 RdctHtrAStat 250;
BA_REL_ "GenSigSuprvResp" BU_SG_REL_ PCM_HS SG_ 957 DslGlwPlgMdOvTmOD 1;
BA_REL_ "GenSigTimeoutMsg" BU_SG_REL_ PCM_HS SG_ 957 DslGlwPlgMdOvTmOD 957;
BA_REL_ "GenSigTimeoutTime" BU_SG_REL_ PCM_HS SG_ 957 DslGlwPlgMdOvTmOD 250;
BA_REL_ "GenSigSuprvResp" BU_SG_REL_ ECM_HS SG_ 957 DslGlwPlgMdOvTmOD 1;
BA_REL_ "GenSigTimeoutMsg" BU_SG_REL_ ECM_HS SG_ 957 DslGlwPlgMdOvTmOD 957;
BA_REL_ "GenSigTimeoutTime" BU_SG_REL_ ECM_HS SG_ 957 DslGlwPlgMdOvTmOD 250;
VAL_ 389 VSELongAccLoResV 1 "Invalid" 0 "Valid" ;
VAL_ 389 StrAngSnsPolRat 0 "Not Passed" 1 "Passed" ;
VAL_ 389 LatAccSnsPolRat 0 "Not Passed" 1 "Passed" ;
VAL_ 1922 DTCI_WrnIndRqdSt_782 1 "true" 0 "false" ;
VAL_ 1922 DTCIUnused7_782 1 "true" 0 "false" ;
VAL_ 1922 DTCIUnused6_782 1 "true" 0 "false" ;
VAL_ 1922 DTCIUnused5_782 1 "true" 0 "false" ;
VAL_ 1922 DTCIUnused4_782 1 "true" 0 "false" ;
VAL_ 1922 DTCIUnused3_782 1 "true" 0 "false" ;
VAL_ 1922 DTCIUnused2_782 1 "true" 0 "false" ;
VAL_ 1922 DTCIUnused1_782 1 "true" 0 "false" ;
VAL_ 1922 DTCI_TstNPsdPwrUpSt_782 1 "true" 0 "false" ;
VAL_ 1922 DTCI_TstNPsdCdClrdSt_782 1 "true" 0 "false" ;
VAL_ 1922 DTCI_TstFldPwrUpSt_782 1 "true" 0 "false" ;
VAL_ 1922 DTCI_TstFldCdClrdStat_782 1 "true" 0 "false" ;
VAL_ 1922 DTCI_HistStat_782 1 "true" 0 "false" ;
VAL_ 1922 DTCI_DTCTriggered_782 1 "true" 0 "false" ;
VAL_ 1922 DTCI_DTCFaultType_782 3 "Type C" 2 "Type B" 1 "Type A" 0 "Not Supported" ;
VAL_ 1922 DTCI_CurrentStatus_782 1 "true" 0 "false" ;
VAL_ 1922 DTCI_CodeSupported_782 1 "true" 0 "false" ;
VAL_ 352 LrnEnvIdSt 1 "Info_valid" 0 "No_info" ;
VAL_ 352 ImoIdSt 1 "Info valid" 0 "No info" ;
VAL_ 562 SndPerfMdCsStAvl 1 "true" 0 "false" ;
VAL_ 562 SndPerfMdCsCrStVal 0 "No Action" 1 "Performance Mode 1" 2 "Performance Mode 2" 3 "Performance Mode 3" 4 "Performance Mode 4" 5 "Performance Mode 5" 6 "Performance Mode 6" 7 "Auto" ;
VAL_ 562 DispPerfMdCsStAvl 1 "true" 0 "false" ;
VAL_ 562 DispPerfMdCsCrStVal 0 "No Action" 1 "Performance Mode 1" 2 "Performance Mode 2" 3 "Performance Mode 3" 4 "Performance Mode 4" 5 "Performance Mode 5" 6 "Performance Mode 6" 7 "Auto" ;
VAL_ 562 DrvlneMntsPerfMdRq 0 "No Action" 1 "Performance Mode 1" 2 "Performance Mode 2" 3 "Performance Mode 3" 4 "Performance Mode 4" 5 "Performance Mode 5" 6 "Performance Mode 6" 7 "Performance Mode 7" ;
VAL_ 562 RideCntrlPerfMdRq 7 "Performance Mode 7" 6 "Performance Mode 6" 5 "Performance Mode 5" 4 "Performance Mode 4" 3 "Performance Mode 3" 2 "Performance Mode 2" 1 "Performance Mode 1" 0 "No Action" ;
VAL_ 562 StgSysPerfMdRq 7 "Performance Mode 7" 6 "Performance Mode 6" 5 "Performance Mode 5" 4 "Performance Mode 4" 3 "Performance Mode 3" 2 "Performance Mode 2" 1 "Performance Mode 1" 0 "No Action" ;
VAL_ 562 DiffPerfMdRq 7 "Performance Mode 7" 6 "Performance Mode 6" 5 "Performance Mode 5" 4 "Performance Mode 4" 3 "Performance Mode 3" 2 "Performance Mode 2" 1 "Performance Mode 1" 0 "No Action" ;
VAL_ 562 SndEnhcmtPerfMdRq 7 "Performance Mode 7" 6 "Performance Mode 6" 5 "Performance Mode 5" 4 "Performance Mode 4" 3 "Performance Mode 3" 2 "Performance Mode 2" 1 "Performance Mode 1" 0 "No Action" ;
VAL_ 562 DsplyPerfMdRq 7 "Performance Mode 7" 6 "Performance Mode 6" 5 "Performance Mode 5" 4 "Performance Mode 4" 3 "Performance Mode 3" 2 "Performance Mode 2" 1 "Performance Mode 1" 0 "No Action" ;
VAL_ 562 ExhstPerfMdRq 7 "Performance Mode 7" 6 "Performance Mode 6" 5 "Performance Mode 5" 4 "Performance Mode 4" 3 "Performance Mode 3" 2 "Performance Mode 2" 1 "Performance Mode 1" 0 "No Action" ;
VAL_ 562 HillDscntCntlSysStat 4 "Temporarily Inhibited" 3 "Failed" 2 "Active" 1 "Enabled" 0 "Normal" ;
VAL_ 562 SusCustStngAvlbl 1 "true" 0 "false" ;
VAL_ 562 SusCustCurrStngVal 7 "Auto" 6 "Performance Mode 6" 5 "Performance Mode 5" 4 "Performance Mode 4" 3 "Performance Mode 3" 0 "No Action" 1 "Performance Mode 1" 2 "Performance Mode 2" ;
VAL_ 562 StrCustStngAvlbl 1 "true" 0 "false" ;
VAL_ 562 StrCustCurrStngVal 7 "Auto" 6 "Performance Mode 6" 5 "Performance Mode 5" 4 "Performance Mode 4" 3 "Performance Mode 3" 0 "No Action" 1 "Performance Mode 1" 2 "Performance Mode 2" ;
VAL_ 562 DrvlnCustStngAvlbl 1 "true" 0 "false" ;
VAL_ 562 AWDPerfMdRq 7 "Performance Mode 7" 6 "Performance Mode 6" 5 "Performance Mode 5" 4 "Performance Mode 4" 3 "Performance Mode 3" 2 "Performance Mode 2" 1 "Performance Mode 1" 0 "No Action" ;
VAL_ 562 DrvlnCustCurrStngVal 7 "Auto" 6 "Performance Mode 6" 5 "Performance Mode 5" 4 "Performance Mode 4" 3 "Performance Mode 3" 0 "No Action" 1 "Performance Mode 1" 2 "Performance Mode 2" ;
VAL_ 893 AFLGPSCstStAvl 1 "true" 0 "false" ;
VAL_ 893 AFLGPSCstCrStVal 0 "No Value" 1 "Corner And Curve Lighting Only" 2 "Intelligent Light Distribution" 3 "GPS Assistance" 4 "Reserved1" 5 "Reserved2" 6 "Reserved3" 7 "Reserved4" ;
VAL_ 893 AFLCstStAvl 1 "true" 0 "false" ;
VAL_ 893 AFLCstCrStVal 0 "No Value" 1 "Corner And Curve Lighting Only" 2 "Intelligent Light Distribution" 3 "Reserved1" 4 "Reserved2" 5 "Reserved3" 6 "Reserved4" 7 "Reserved5" ;
VAL_ 892 AdpHgBmAsSnCsCrStVal 0 "No Value" 1 "Off" 2 "On Normal Sensitivity" 3 "On Reduced Sensitivity" 4 "Reserved1" 5 "Reserved2" 6 "Reserved3" 7 "Reserved4" ;
VAL_ 892 AdpHgBmAsSnCsStAvl 1 "true" 0 "false" ;
VAL_ 892 AdpHgBmAsCsCrStVal 0 "No Value" 1 "Off" 2 "On" 3 "Reserved1" 4 "Reserved2" 5 "Reserved3" 6 "Reserved4" 7 "Reserved5" ;
VAL_ 892 AdpHgBmAsCsStAvl 1 "true" 0 "false" ;
VAL_ 892 AutHgBmAsCsCrStVal 0 "No Value" 1 "Off" 2 "On" 3 "Reserved1" 4 "Reserved2" 5 "Reserved3" 6 "Reserved4" 7 "Reserved5" ;
VAL_ 892 AutHgBmAsSnCsStAvl 1 "true" 0 "false" ;
VAL_ 892 AutHgBmAsSnCsCrStVa 0 "No Value" 1 "Off" 2 "On Normal Sensitivity" 3 "On Reduced Sensitivity" 4 "Reserved1" 5 "Reserved2" 6 "Reserved3" 7 "Reserved4" ;
VAL_ 892 AutHgBmAsCsStAvl 1 "true" 0 "false" ;
VAL_ 386 EnvIdRspSt4 3 "Environment_id_request" 2 "Incorrect_immo_id" 1 "Info_valid" 0 "No_info" ;
VAL_ 532 RedntVSEAct 1 "true" 0 "false" ;
VAL_ 532 AutoBrkngAvlbl 1 "true" 0 "false" ;
VAL_ 532 ABSAutnmsBrkReq 1 "true" 0 "false" ;
VAL_ 532 HlStrAssActIO 1 "true" 0 "false" ;
VAL_ 532 ABSActvProt 1 "true" 0 "false" ;
VAL_ 532 BrkSysAutBrkFld 1 "true" 0 "false" ;
VAL_ 532 IntBrkAssPreFilReq 1 "true" 0 "false" ;
VAL_ 532 BrkSysMalFuncIndOn 1 "true" 0 "false" ;
VAL_ 532 BPDAPS_BkPDrvApPV 1 "Invalid" 0 "Valid" ;
VAL_ 532 BrkFldLvlLwV 1 "Invalid" 0 "Valid" ;
VAL_ 532 AutoBrkngAct 1 "true" 0 "false" ;
VAL_ 532 BrkFldLvlLw 1 "true" 0 "false" ;
VAL_ 890 LtRtHnTrGPCsCrStVal 0 "No Value" 1 "Left Hand Traffic" 2 "Right Hand Traffic" 3 "Automatic" 4 "Reserved1" 5 "Reserved2" 6 "Reserved3" 7 "Reserved4" ;
VAL_ 890 LtRtHnTrGPSCsStAvl 1 "true" 0 "false" ;
VAL_ 890 LtRtHnTrCstStVal 0 "No Value" 1 "Left Hand Drive" 2 "Right Hand Drive" ;
VAL_ 890 LtRtHnTrCstStAvail 0 "Not Available" 1 "Present" ;
VAL_ 328 StrngAsstRdcdIO 1 "true" 0 "false" ;
VAL_ 328 PwrStrIO 1 "true" 0 "false" ;
VAL_ 560 ElecPrkBrkSwStatV 1 "Invalid" 0 "Valid" ;
VAL_ 560 ElecPrkBrkSwStat 2 "Apply" 1 "Release" 0 "NotActive" ;
VAL_ 560 AllNodesVNA 1 "Activate Virtual Network" 0 "No Activation" ;
VAL_ 560 StpOnBrkToRelPBIndOn 1 "true" 0 "false" ;
VAL_ 560 EPBC_EPBrkAutBrkRq 1 "true" 0 "false" ;
VAL_ 560 EPBSysDspMsgReq 7 "Message #7" 6 "Message #6" 5 "Message #5" 4 "Message #4" 3 "Message #3" 2 "Message #2" 1 "Message #1" 0 "Off" ;
VAL_ 560 EPBSysAudWarnReq 2 "Warning #2" 1 "Warning #1" 0 "Off" ;
VAL_ 560 ElecPrkBrkStat 2 "Fault" 1 "Applied" 0 "Released" ;
VAL_ 560 EPBCrsCanRq 1 "true" 0 "false" ;
VAL_ 560 EPBSysStatIndReq 3 "Flash Rate 2 Indication" 2 "Flash Rate 1 Indication" 1 "Continuous Indication" 0 "No Indication" ;
VAL_ 560 EPBSysWrnIndReq 3 "Flash Rate #2 Indication" 2 "Flash Rate #1 Indication" 1 "Continuous Indication" 0 "No Indication" ;
VAL_ 560 EPBSysBrkLtsReq 1 "true" 0 "false" ;
VAL_ 383 AFSSysFail 1 "true" 0 "false" ;
VAL_ 383 FrStSysVeTpSpLimIndOn 1 "true" 0 "false" ;
VAL_ 383 AFSIndOn 1 "true" 0 "false" ;
VAL_ 451 GlwPlgCrnkDelAct 1 "true" 0 "false" ;
VAL_ 451 PltfrmEngSpdCmmndSt 3 "Request Denied" 2 "Lost Arbitration" 1 "Request Honored" 0 "No Request" ;
VAL_ 451 AuxHtrAlwd 1 "true" 0 "false" ;
VAL_ 451 EconMdRqDndIO 1 "true" 0 "false" ;
VAL_ 451 EconMdAtvIO 1 "true" 0 "false" ;
VAL_ 451 AppCltchAutSrtIO 1 "true" 0 "false" ;
VAL_ 451 AccPosV 1 "Invalid" 0 "Valid" ;
VAL_ 451 EngTrqRdFlrSt 4 "Torq Reduction Communication Failed" 3 "Torque Reduction Limited" 2 "Torque Reduction Permanently Failed" 1 "Torque Reduction Temporarily Failed" 0 "Torque Reduction OK" ;
VAL_ 451 EngTrqDrRqdExtRngV 1 "Invalid" 0 "Valid" ;
VAL_ 451 EngTrqActExtRngV 1 "Invalid" 0 "Valid" ;
VAL_ 801 WhlBdySnsHmPosLrnd 1 "true" 0 "false" ;
VAL_ 801 WBRP_RtFrtV 1 "Invalid" 0 "Valid" ;
VAL_ 801 WBRP_RtRrV 1 "Invalid" 0 "Valid" ;
VAL_ 801 WBRP_LftRrV 1 "Invalid" 0 "Valid" ;
VAL_ 801 WBRP_LftFrtV 1 "Invalid" 0 "Valid" ;
VAL_ 320 BrkLtsAtv 1 "true" 0 "false" ;
VAL_ 320 TrnSwAct 2 "Right" 1 "Left" 0 "No Activation" ;
VAL_ 320 RrFogLmpsAct 1 "true" 0 "false" ;
VAL_ 320 OtsdAmbtLtLvlStatV 1 "Invalid" 0 "Valid" ;
VAL_ 320 OtsdAmbtLtLvlStat 2 "Day" 1 "Night" 0 "Unknown" ;
VAL_ 320 MainLghtSw 3 "HEADLAMP" 2 "PARKLAMP" 1 "OFF" 0 "AUTO" ;
VAL_ 320 LowBmAct 1 "true" 0 "false" ;
VAL_ 320 HighBmAct 1 "true" 0 "false" ;
VAL_ 320 HdlmpBmSelectStat 2 "High Beams" 1 "Low Beams" 0 "Unknown" ;
VAL_ 320 FlToPsSwAtv 1 "true" 0 "false" ;
VAL_ 320 AdvFrntLghtSysEnbld 1 "true" 0 "false" ;
VAL_ 320 FrFogLmpsAct 1 "true" 0 "false" ;
VAL_ 320 AutLghtCtrl 1 "true" 0 "false" ;
VAL_ 957 RdctHtrCStat 0 "Off" 1 "On" ;
VAL_ 957 RdctHtrBStat 0 "Off" 1 "On" ;
VAL_ 957 RdctHtrAStat 0 "Off" 1 "On" ;
VAL_ 957 GPCMDS2_DTCStatus 4 "Diagnostic Failed" 3 "Diagnostic Passed" 2 "No Status to Report" 1 "Critically Disabled" 0 "Not Supported" ;
VAL_ 957 IntAirHtrPwrConsmpV 1 "Invalid" 0 "Valid" ;
VAL_ 957 DslGlwPlgMdOvTmOD 1 "true" 0 "false" ;
VAL_ 957 IQAI_InjIdInd 7 "Injector 8" 6 "Injector 7" 5 "Injector 6" 4 "Injector 5" 3 "Injector 4" 2 "Injector 3" 1 "Injector 2" 0 "Injector 1" ;
VAL_ 957 IQAI_DataStat 1 "IQA Data Byte Stored" 0 "IQA Data Byte Not Stored" ;
VAL_ 957 IntAirHtrTempSensVoltV 1 "Invalid" 0 "Valid" ;
VAL_ 957 IntAirHtrSupVoltV 1 "Invalid" 0 "Valid" ;
VAL_ 957 GPCMDS_DTCStatus 4 "Diagnostic Failed" 3 "Diagnostic Passed" 2 "No Status to Report" 1 "Critically Disabled" 0 "Not Supported" ;
VAL_ 1904 DTCI_WrnIndRqdSt_770 1 "true" 0 "false" ;
VAL_ 1904 DTCIUnused7_770 1 "true" 0 "false" ;
VAL_ 1904 DTCIUnused6_770 1 "true" 0 "false" ;
VAL_ 1904 DTCIUnused5_770 1 "true" 0 "false" ;
VAL_ 1904 DTCIUnused4_770 1 "true" 0 "false" ;
VAL_ 1904 DTCIUnused3_770 1 "true" 0 "false" ;
VAL_ 1904 DTCIUnused2_770 1 "true" 0 "false" ;
VAL_ 1904 DTCIUnused1_770 1 "true" 0 "false" ;
VAL_ 1904 DTCI_TstNPsdPwrUpSt_770 1 "true" 0 "false" ;
VAL_ 1904 DTCI_TstNPsdCdClrdSt_770 1 "true" 0 "false" ;
VAL_ 1904 DTCI_TstFldPwrUpSt_770 1 "true" 0 "false" ;
VAL_ 1904 DTCI_TstFldCdClrdStat_770 1 "true" 0 "false" ;
VAL_ 1904 DTCI_HistStat_770 1 "true" 0 "false" ;
VAL_ 1904 DTCI_DTCTriggered_770 1 "true" 0 "false" ;
VAL_ 1904 DTCI_DTCFaultType_770 3 "Type C" 2 "Type B" 1 "Type A" 0 "Not Supported" ;
VAL_ 1904 DTCI_CurrentStatus_770 1 "true" 0 "false" ;
VAL_ 1904 DTCI_CodeSupported_770 1 "true" 0 "false" ;
VAL_ 1908 DTCI_DTCFaultType_774 3 "Type C" 2 "Type B" 1 "Type A" 0 "Not Supported" ;
VAL_ 1908 DTCI_CodeSupported_774 1 "true" 0 "false" ;
VAL_ 1908 DTCI_CurrentStatus_774 1 "true" 0 "false" ;
VAL_ 1908 DTCI_TstNPsdCdClrdSt_774 1 "true" 0 "false" ;
VAL_ 1908 DTCI_TstFldCdClrdStat_774 1 "true" 0 "false" ;
VAL_ 1908 DTCI_HistStat_774 1 "true" 0 "false" ;
VAL_ 1908 DTCI_TstNPsdPwrUpSt_774 1 "true" 0 "false" ;
VAL_ 1908 DTCI_TstFldPwrUpSt_774 1 "true" 0 "false" ;
VAL_ 1908 DTCI_WrnIndRqdSt_774 1 "true" 0 "false" ;
VAL_ 1908 DTCI_DTCTriggered_774 1 "true" 0 "false" ;
VAL_ 1908 DTCIUnused7_774 1 "true" 0 "false" ;
VAL_ 1908 DTCIUnused6_774 1 "true" 0 "false" ;
VAL_ 1908 DTCIUnused5_774 1 "true" 0 "false" ;
VAL_ 1908 DTCIUnused4_774 1 "true" 0 "false" ;
VAL_ 1908 DTCIUnused3_774 1 "true" 0 "false" ;
VAL_ 1908 DTCIUnused2_774 1 "true" 0 "false" ;
VAL_ 1908 DTCIUnused1_774 1 "true" 0 "false" ;
VAL_ 1909 DTCI_DTCFaultType_775 3 "Type C" 2 "Type B" 1 "Type A" 0 "Not Supported" ;
VAL_ 1909 DTCI_CodeSupported_775 1 "true" 0 "false" ;
VAL_ 1909 DTCI_CurrentStatus_775 1 "true" 0 "false" ;
VAL_ 1909 DTCI_TstNPsdCdClrdSt_775 1 "true" 0 "false" ;
VAL_ 1909 DTCI_TstFldCdClrdStat_775 1 "true" 0 "false" ;
VAL_ 1909 DTCI_HistStat_775 1 "true" 0 "false" ;
VAL_ 1909 DTCI_TstNPsdPwrUpSt_775 1 "true" 0 "false" ;
VAL_ 1909 DTCI_TstFldPwrUpSt_775 1 "true" 0 "false" ;
VAL_ 1909 DTCI_WrnIndRqdSt_775 1 "true" 0 "false" ;
VAL_ 1909 DTCI_DTCTriggered_775 1 "true" 0 "false" ;
VAL_ 1909 DTCIUnused7_775 1 "true" 0 "false" ;
VAL_ 1909 DTCIUnused6_775 1 "true" 0 "false" ;
VAL_ 1909 DTCIUnused5_775 1 "true" 0 "false" ;
VAL_ 1909 DTCIUnused4_775 1 "true" 0 "false" ;
VAL_ 1909 DTCIUnused3_775 1 "true" 0 "false" ;
VAL_ 1909 DTCIUnused2_775 1 "true" 0 "false" ;
VAL_ 1909 DTCIUnused1_775 1 "true" 0 "false" ;
VAL_ 1910 DTCI_DTCFaultType_776 3 "Type C" 2 "Type B" 1 "Type A" 0 "Not Supported" ;
VAL_ 1910 DTCI_CodeSupported_776 1 "true" 0 "false" ;
VAL_ 1910 DTCI_CurrentStatus_776 1 "true" 0 "false" ;
VAL_ 1910 DTCI_TstNPsdCdClrdSt_776 1 "true" 0 "false" ;
VAL_ 1910 DTCI_TstFldCdClrdStat_776 1 "true" 0 "false" ;
VAL_ 1910 DTCI_HistStat_776 1 "true" 0 "false" ;
VAL_ 1910 DTCI_TstNPsdPwrUpSt_776 1 "true" 0 "false" ;
VAL_ 1910 DTCI_TstFldPwrUpSt_776 1 "true" 0 "false" ;
VAL_ 1910 DTCI_WrnIndRqdSt_776 1 "true" 0 "false" ;
VAL_ 1910 DTCI_DTCTriggered_776 1 "true" 0 "false" ;
VAL_ 1910 DTCIUnused7_776 1 "true" 0 "false" ;
VAL_ 1910 DTCIUnused6_776 1 "true" 0 "false" ;
VAL_ 1910 DTCIUnused5_776 1 "true" 0 "false" ;
VAL_ 1910 DTCIUnused4_776 1 "true" 0 "false" ;
VAL_ 1910 DTCIUnused3_776 1 "true" 0 "false" ;
VAL_ 1910 DTCIUnused2_776 1 "true" 0 "false" ;
VAL_ 1910 DTCIUnused1_776 1 "true" 0 "false" ;
VAL_ 1912 DTCI_DTCFaultType_778 3 "Type C" 2 "Type B" 1 "Type A" 0 "Not Supported" ;
VAL_ 1912 DTCI_CodeSupported_778 1 "true" 0 "false" ;
VAL_ 1912 DTCI_CurrentStatus_778 1 "true" 0 "false" ;
VAL_ 1912 DTCI_TstNPsdCdClrdSt_778 1 "true" 0 "false" ;
VAL_ 1912 DTCI_TstFldCdClrdStat_778 1 "true" 0 "false" ;
VAL_ 1912 DTCI_HistStat_778 1 "true" 0 "false" ;
VAL_ 1912 DTCI_TstNPsdPwrUpSt_778 1 "true" 0 "false" ;
VAL_ 1912 DTCI_TstFldPwrUpSt_778 1 "true" 0 "false" ;
VAL_ 1912 DTCI_WrnIndRqdSt_778 1 "true" 0 "false" ;
VAL_ 1912 DTCI_DTCTriggered_778 1 "true" 0 "false" ;
VAL_ 1912 DTCIUnused7_778 1 "true" 0 "false" ;
VAL_ 1912 DTCIUnused6_778 1 "true" 0 "false" ;
VAL_ 1912 DTCIUnused5_778 1 "true" 0 "false" ;
VAL_ 1912 DTCIUnused4_778 1 "true" 0 "false" ;
VAL_ 1912 DTCIUnused3_778 1 "true" 0 "false" ;
VAL_ 1912 DTCIUnused2_778 1 "true" 0 "false" ;
VAL_ 1912 DTCIUnused1_778 1 "true" 0 "false" ;
VAL_ 1913 DTCI_DTCFaultType_779 3 "Type C" 2 "Type B" 1 "Type A" 0 "Not Supported" ;
VAL_ 1913 DTCI_CodeSupported_779 1 "true" 0 "false" ;
VAL_ 1913 DTCI_CurrentStatus_779 1 "true" 0 "false" ;
VAL_ 1913 DTCI_TstNPsdCdClrdSt_779 1 "true" 0 "false" ;
VAL_ 1913 DTCI_TstFldCdClrdStat_779 1 "true" 0 "false" ;
VAL_ 1913 DTCI_HistStat_779 1 "true" 0 "false" ;
VAL_ 1913 DTCI_TstNPsdPwrUpSt_779 1 "true" 0 "false" ;
VAL_ 1913 DTCI_TstFldPwrUpSt_779 1 "true" 0 "false" ;
VAL_ 1913 DTCI_WrnIndRqdSt_779 1 "true" 0 "false" ;
VAL_ 1913 DTCI_DTCTriggered_779 1 "true" 0 "false" ;
VAL_ 1913 DTCIUnused7_779 1 "true" 0 "false" ;
VAL_ 1913 DTCIUnused6_779 1 "true" 0 "false" ;
VAL_ 1913 DTCIUnused5_779 1 "true" 0 "false" ;
VAL_ 1913 DTCIUnused4_779 1 "true" 0 "false" ;
VAL_ 1913 DTCIUnused3_779 1 "true" 0 "false" ;
VAL_ 1913 DTCIUnused2_779 1 "true" 0 "false" ;
VAL_ 1913 DTCIUnused1_779 1 "true" 0 "false" ;
VAL_ 1916 DTCI_DTCFaultType_77C 3 "Type C" 2 "Type B" 1 "Type A" 0 "Not Supported" ;
VAL_ 1916 DTCI_CodeSupported_77C 1 "true" 0 "false" ;
VAL_ 1916 DTCI_CurrentStatus_77C 1 "true" 0 "false" ;
VAL_ 1916 DTCI_TstNPsdCdClrdSt_77C 1 "true" 0 "false" ;
VAL_ 1916 DTCI_TstFldCdClrdStat_77C 1 "true" 0 "false" ;
VAL_ 1916 DTCI_HistStat_77C 1 "true" 0 "false" ;
VAL_ 1916 DTCI_TstNPsdPwrUpSt_77C 1 "true" 0 "false" ;
VAL_ 1916 DTCI_TstFldPwrUpSt_77C 1 "true" 0 "false" ;
VAL_ 1916 DTCI_WrnIndRqdSt_77C 1 "true" 0 "false" ;
VAL_ 1916 DTCI_DTCTriggered_77C 1 "true" 0 "false" ;
VAL_ 1916 DTCIUnused7_77C 1 "true" 0 "false" ;
VAL_ 1916 DTCIUnused6_77C 1 "true" 0 "false" ;
VAL_ 1916 DTCIUnused5_77C 1 "true" 0 "false" ;
VAL_ 1916 DTCIUnused4_77C 1 "true" 0 "false" ;
VAL_ 1916 DTCIUnused3_77C 1 "true" 0 "false" ;
VAL_ 1916 DTCIUnused2_77C 1 "true" 0 "false" ;
VAL_ 1916 DTCIUnused1_77C 1 "true" 0 "false" ;
VAL_ 1917 DTCI_DTCFaultType_77D 3 "Type C" 2 "Type B" 1 "Type A" 0 "Not Supported" ;
VAL_ 1917 DTCI_CodeSupported_77D 1 "true" 0 "false" ;
VAL_ 1917 DTCI_CurrentStatus_77D 1 "true" 0 "false" ;
VAL_ 1917 DTCI_TstNPsdCdClrdSt_77D 1 "true" 0 "false" ;
VAL_ 1917 DTCI_TstFldCdClrdStat_77D 1 "true" 0 "false" ;
VAL_ 1917 DTCI_HistStat_77D 1 "true" 0 "false" ;
VAL_ 1917 DTCI_TstNPsdPwrUpSt_77D 1 "true" 0 "false" ;
VAL_ 1917 DTCI_TstFldPwrUpSt_77D 1 "true" 0 "false" ;
VAL_ 1917 DTCI_WrnIndRqdSt_77D 1 "true" 0 "false" ;
VAL_ 1917 DTCI_DTCTriggered_77D 1 "true" 0 "false" ;
VAL_ 1917 DTCIUnused7_77D 1 "true" 0 "false" ;
VAL_ 1917 DTCIUnused6_77D 1 "true" 0 "false" ;
VAL_ 1917 DTCIUnused5_77D 1 "true" 0 "false" ;
VAL_ 1917 DTCIUnused4_77D 1 "true" 0 "false" ;
VAL_ 1917 DTCIUnused3_77D 1 "true" 0 "false" ;
VAL_ 1917 DTCIUnused2_77D 1 "true" 0 "false" ;
VAL_ 1917 DTCIUnused1_77D 1 "true" 0 "false" ;
VAL_ 1918 DTCI_DTCFaultType_77E 3 "Type C" 2 "Type B" 1 "Type A" 0 "Not Supported" ;
VAL_ 1918 DTCI_CodeSupported_77E 1 "true" 0 "false" ;
VAL_ 1918 DTCI_CurrentStatus_77E 1 "true" 0 "false" ;
VAL_ 1918 DTCI_TstNPsdCdClrdSt_77E 1 "true" 0 "false" ;
VAL_ 1918 DTCI_TstFldCdClrdStat_77E 1 "true" 0 "false" ;
VAL_ 1918 DTCI_HistStat_77E 1 "true" 0 "false" ;
VAL_ 1918 DTCI_TstNPsdPwrUpSt_77E 1 "true" 0 "false" ;
VAL_ 1918 DTCI_TstFldPwrUpSt_77E 1 "true" 0 "false" ;
VAL_ 1918 DTCI_WrnIndRqdSt_77E 1 "true" 0 "false" ;
VAL_ 1918 DTCI_DTCTriggered_77E 1 "true" 0 "false" ;
VAL_ 1918 DTCIUnused7_77E 1 "true" 0 "false" ;
VAL_ 1918 DTCIUnused6_77E 1 "true" 0 "false" ;
VAL_ 1918 DTCIUnused5_77E 1 "true" 0 "false" ;
VAL_ 1918 DTCIUnused4_77E 1 "true" 0 "false" ;
VAL_ 1918 DTCIUnused3_77E 1 "true" 0 "false" ;
VAL_ 1918 DTCIUnused2_77E 1 "true" 0 "false" ;
VAL_ 1918 DTCIUnused1_77E 1 "true" 0 "false" ;
VAL_ 1919 DTCI_DTCFaultType_77F 3 "Type C" 2 "Type B" 1 "Type A" 0 "Not Supported" ;
VAL_ 1919 DTCI_CodeSupported_77F 1 "true" 0 "false" ;
VAL_ 1919 DTCI_CurrentStatus_77F 1 "true" 0 "false" ;
VAL_ 1919 DTCI_TstNPsdCdClrdSt_77F 1 "true" 0 "false" ;
VAL_ 1919 DTCI_TstFldCdClrdStat_77F 1 "true" 0 "false" ;
VAL_ 1919 DTCI_HistStat_77F 1 "true" 0 "false" ;
VAL_ 1919 DTCI_TstNPsdPwrUpSt_77F 1 "true" 0 "false" ;
VAL_ 1919 DTCI_TstFldPwrUpSt_77F 1 "true" 0 "false" ;
VAL_ 1919 DTCI_WrnIndRqdSt_77F 1 "true" 0 "false" ;
VAL_ 1919 DTCI_DTCTriggered_77F 1 "true" 0 "false" ;
VAL_ 1919 DTCIUnused7_77F 1 "true" 0 "false" ;
VAL_ 1919 DTCIUnused6_77F 1 "true" 0 "false" ;
VAL_ 1919 DTCIUnused5_77F 1 "true" 0 "false" ;
VAL_ 1919 DTCIUnused4_77F 1 "true" 0 "false" ;
VAL_ 1919 DTCIUnused3_77F 1 "true" 0 "false" ;
VAL_ 1919 DTCIUnused2_77F 1 "true" 0 "false" ;
VAL_ 1919 DTCIUnused1_77F 1 "true" 0 "false" ;
SIG_GROUP_ 1922 DTCInfo_782 1 : DTCI_WrnIndRqdSt_782 DTCIUnused7_782 DTCIUnused6_782 DTCIUnused5_782 DTCIUnused4_782 DTCIUnused3_782 DTCIUnused2_782 DTCIUnused1_782 DTCI_TstNPsdPwrUpSt_782 DTCI_TstNPsdCdClrdSt_782 DTCI_TstFldPwrUpSt_782 DTCI_TstFldCdClrdStat_782 DTCI_HistStat_782 DTCI_DTCTriggered_782 DTCI_DTCSource_782 DTCI_DTCNumber_782 DTCI_DTCFaultType_782 DTCI_DTCFailType_782 DTCI_CurrentStatus_782 DTCI_CodeSupported_782;
SIG_GROUP_ 532 BrkPdDrvAppPrsStat 1 : BPDAPS_BkPDrvApPV BPDAPS_BkPDrvApP;
SIG_GROUP_ 560 ElecPrkBrkCmd 1 : EPBC_EPBAccRq EPBC_EPBrkAutBrkRq;
SIG_GROUP_ 801 WhlBdyRelPos 1 : WBRP_ARC WBRP_Tmestmp WBRP_RtFrtV WBRP_RtFrt WBRP_RtRrV WBRP_RtRr WBRP_LftRrV WBRP_LftRr WBRP_LftFrtV WBRP_LftFrt;
SIG_GROUP_ 957 GlwPlgCntlModDiagSt2 1 : GPCMDS2_DTCStatus GPCMDS2_DTCIndex;
SIG_GROUP_ 957 InjQualAdjInfo 1 : IQAI_DataByte IQAI_DataSeqNmbr IQAI_InjIdInd IQAI_DataStat;
SIG_GROUP_ 957 GlwPlgCntlModDiagSt 1 : GPCMDS_DTCStatus GPCMDS_DTCIndex;
SIG_GROUP_ 1904 DTCInfo_770 1 : DTCI_WrnIndRqdSt_770 DTCIUnused7_770 DTCIUnused6_770 DTCIUnused5_770 DTCIUnused4_770 DTCIUnused3_770 DTCIUnused2_770 DTCIUnused1_770 DTCI_TstNPsdPwrUpSt_770 DTCI_TstNPsdCdClrdSt_770 DTCI_TstFldPwrUpSt_770 DTCI_TstFldCdClrdStat_770 DTCI_HistStat_770 DTCI_DTCTriggered_770 DTCI_DTCSource_770 DTCI_DTCNumber_770 DTCI_DTCFaultType_770 DTCI_DTCFailType_770 DTCI_CurrentStatus_770 DTCI_CodeSupported_770;
SIG_GROUP_ 1908 DTCInfo_774 1 : DTCI_DTCFaultType_774 DTCI_CodeSupported_774 DTCI_CurrentStatus_774 DTCI_TstNPsdCdClrdSt_774 DTCI_TstFldCdClrdStat_774 DTCI_HistStat_774 DTCI_TstNPsdPwrUpSt_774 DTCI_TstFldPwrUpSt_774 DTCI_WrnIndRqdSt_774 DTCI_DTCFailType_774 DTCI_DTCNumber_774 DTCI_DTCSource_774 DTCI_DTCTriggered_774 DTCIUnused7_774 DTCIUnused6_774 DTCIUnused5_774 DTCIUnused4_774 DTCIUnused3_774 DTCIUnused2_774 DTCIUnused1_774;
SIG_GROUP_ 1909 DTCInfo_775 1 : DTCI_DTCFaultType_775 DTCI_CodeSupported_775 DTCI_CurrentStatus_775 DTCI_TstNPsdCdClrdSt_775 DTCI_TstFldCdClrdStat_775 DTCI_HistStat_775 DTCI_TstNPsdPwrUpSt_775 DTCI_TstFldPwrUpSt_775 DTCI_WrnIndRqdSt_775 DTCI_DTCFailType_775 DTCI_DTCNumber_775 DTCI_DTCSource_775 DTCI_DTCTriggered_775 DTCIUnused7_775 DTCIUnused6_775 DTCIUnused5_775 DTCIUnused4_775 DTCIUnused3_775 DTCIUnused2_775 DTCIUnused1_775;
SIG_GROUP_ 1910 DTCInfo_776 1 : DTCI_DTCFaultType_776 DTCI_CodeSupported_776 DTCI_CurrentStatus_776 DTCI_TstNPsdCdClrdSt_776 DTCI_TstFldCdClrdStat_776 DTCI_HistStat_776 DTCI_TstNPsdPwrUpSt_776 DTCI_TstFldPwrUpSt_776 DTCI_WrnIndRqdSt_776 DTCI_DTCFailType_776 DTCI_DTCNumber_776 DTCI_DTCSource_776 DTCI_DTCTriggered_776 DTCIUnused7_776 DTCIUnused6_776 DTCIUnused5_776 DTCIUnused4_776 DTCIUnused3_776 DTCIUnused2_776 DTCIUnused1_776;
SIG_GROUP_ 1912 DTCInfo_778 1 : DTCI_DTCFaultType_778 DTCI_CodeSupported_778 DTCI_CurrentStatus_778 DTCI_TstNPsdCdClrdSt_778 DTCI_TstFldCdClrdStat_778 DTCI_HistStat_778 DTCI_TstNPsdPwrUpSt_778 DTCI_TstFldPwrUpSt_778 DTCI_WrnIndRqdSt_778 DTCI_DTCFailType_778 DTCI_DTCNumber_778 DTCI_DTCSource_778 DTCI_DTCTriggered_778 DTCIUnused7_778 DTCIUnused6_778 DTCIUnused5_778 DTCIUnused4_778 DTCIUnused3_778 DTCIUnused2_778 DTCIUnused1_778;
SIG_GROUP_ 1913 DTCInfo_779 1 : DTCI_DTCFaultType_779 DTCI_CodeSupported_779 DTCI_CurrentStatus_779 DTCI_TstNPsdCdClrdSt_779 DTCI_TstFldCdClrdStat_779 DTCI_HistStat_779 DTCI_TstNPsdPwrUpSt_779 DTCI_TstFldPwrUpSt_779 DTCI_WrnIndRqdSt_779 DTCI_DTCFailType_779 DTCI_DTCNumber_779 DTCI_DTCSource_779 DTCI_DTCTriggered_779 DTCIUnused7_779 DTCIUnused6_779 DTCIUnused5_779 DTCIUnused4_779 DTCIUnused3_779 DTCIUnused2_779 DTCIUnused1_779;
SIG_GROUP_ 1916 DTCInfo_77C 1 : DTCI_DTCFaultType_77C DTCI_CodeSupported_77C DTCI_CurrentStatus_77C DTCI_TstNPsdCdClrdSt_77C DTCI_TstFldCdClrdStat_77C DTCI_HistStat_77C DTCI_TstNPsdPwrUpSt_77C DTCI_TstFldPwrUpSt_77C DTCI_WrnIndRqdSt_77C DTCI_DTCFailType_77C DTCI_DTCNumber_77C DTCI_DTCSource_77C DTCI_DTCTriggered_77C DTCIUnused7_77C DTCIUnused6_77C DTCIUnused5_77C DTCIUnused4_77C DTCIUnused3_77C DTCIUnused2_77C DTCIUnused1_77C;
SIG_GROUP_ 1917 DTCInfo_77D 1 : DTCI_DTCFaultType_77D DTCI_CodeSupported_77D DTCI_CurrentStatus_77D DTCI_TstNPsdCdClrdSt_77D DTCI_TstFldCdClrdStat_77D DTCI_HistStat_77D DTCI_TstNPsdPwrUpSt_77D DTCI_TstFldPwrUpSt_77D DTCI_WrnIndRqdSt_77D DTCI_DTCFailType_77D DTCI_DTCNumber_77D DTCI_DTCSource_77D DTCI_DTCTriggered_77D DTCIUnused7_77D DTCIUnused6_77D DTCIUnused5_77D DTCIUnused4_77D DTCIUnused3_77D DTCIUnused2_77D DTCIUnused1_77D;
SIG_GROUP_ 1918 DTCInfo_77E 1 : DTCI_DTCFaultType_77E DTCI_CodeSupported_77E DTCI_CurrentStatus_77E DTCI_TstNPsdCdClrdSt_77E DTCI_TstFldCdClrdStat_77E DTCI_HistStat_77E DTCI_TstNPsdPwrUpSt_77E DTCI_TstFldPwrUpSt_77E DTCI_WrnIndRqdSt_77E DTCI_DTCFailType_77E DTCI_DTCNumber_77E DTCI_DTCSource_77E DTCI_DTCTriggered_77E DTCIUnused7_77E DTCIUnused6_77E DTCIUnused5_77E DTCIUnused4_77E DTCIUnused3_77E DTCIUnused2_77E DTCIUnused1_77E;
SIG_GROUP_ 1919 DTCInfo_77F 1 : DTCI_DTCFaultType_77F DTCI_CodeSupported_77F DTCI_CurrentStatus_77F DTCI_TstNPsdCdClrdSt_77F DTCI_TstFldCdClrdStat_77F DTCI_HistStat_77F DTCI_TstNPsdPwrUpSt_77F DTCI_TstFldPwrUpSt_77F DTCI_WrnIndRqdSt_77F DTCI_DTCFailType_77F DTCI_DTCNumber_77F DTCI_DTCSource_77F DTCI_DTCTriggered_77F DTCIUnused7_77F DTCIUnused6_77F DTCIUnused5_77F DTCIUnused4_77F DTCIUnused3_77F DTCIUnused2_77F DTCIUnused1_77F;
